VERSION "canboat-NMEA2000-curated"

NS_ :

BS_:

BU_: Vector__XXX
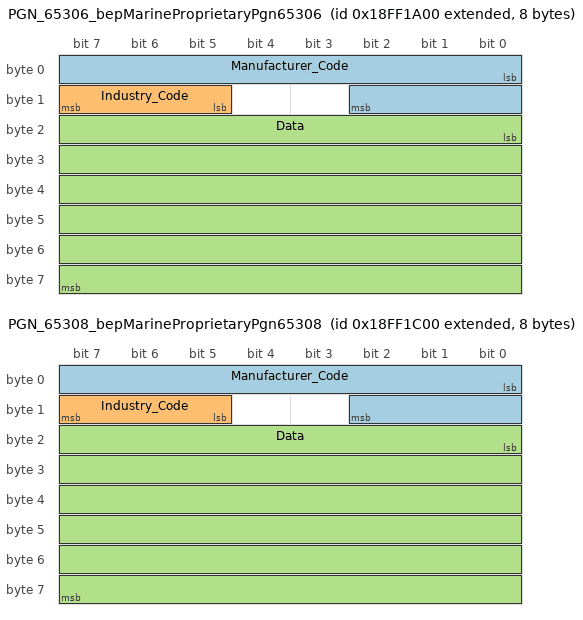
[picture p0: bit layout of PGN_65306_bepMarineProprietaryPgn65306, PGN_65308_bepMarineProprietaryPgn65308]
BO_ 2566855168 PGN_65306_bepMarineProprietaryPgn65306: 8 Vector__XXX
 SG_ Manufacturer_Code : 0|11@1+ (1.0,0) [0|2047] "" Vector__XXX
 SG_ Industry_Code : 13|3@1+ (1.0,0) [0|7] "" Vector__XXX
 SG_ Data : 16|48@1+ (1.0,0) [0|281474976710655] "" Vector__XXX

BO_ 2566855680 PGN_65308_bepMarineProprietaryPgn65308: 8 Vector__XXX
 SG_ Manufacturer_Code : 0|11@1+ (1.0,0) [0|2047] "" Vector__XXX
 SG_ Industry_Code : 13|3@1+ (1.0,0) [0|7] "" Vector__XXX
 SG_ Data : 16|48@1+ (1.0,0) [0|281474976710655] "" Vector__XXX

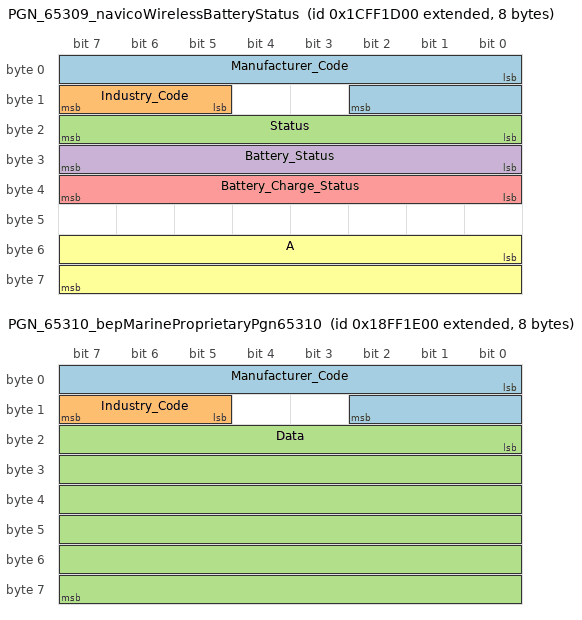
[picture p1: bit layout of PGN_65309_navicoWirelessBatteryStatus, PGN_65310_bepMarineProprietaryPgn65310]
BO_ 2633964800 PGN_65309_navicoWirelessBatteryStatus: 8 Vector__XXX
 SG_ Manufacturer_Code : 0|11@1+ (1.0,0) [0|2047] "" Vector__XXX
 SG_ Industry_Code : 13|3@1+ (1.0,0) [0|7] "" Vector__XXX
 SG_ Status : 16|8@1+ (1.0,0) [0|255] "" Vector__XXX
 SG_ Battery_Status : 24|8@1+ (1.0,0) [0|255] "%" Vector__XXX
 SG_ Battery_Charge_Status : 32|8@1+ (1.0,0) [0|255] "%" Vector__XXX
 SG_ A : 48|16@1- (1.0,0) [-32768|32767] "" Vector__XXX

BO_ 2566856192 PGN_65310_bepMarineProprietaryPgn65310: 8 Vector__XXX
 SG_ Manufacturer_Code : 0|11@1+ (1.0,0) [0|2047] "" Vector__XXX
 SG_ Industry_Code : 13|3@1+ (1.0,0) [0|7] "" Vector__XXX
 SG_ Data : 16|48@1+ (1.0,0) [0|281474976710655] "" Vector__XXX

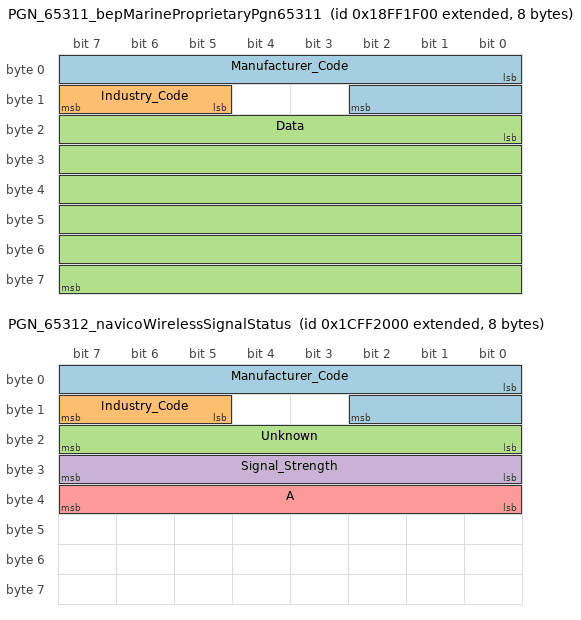
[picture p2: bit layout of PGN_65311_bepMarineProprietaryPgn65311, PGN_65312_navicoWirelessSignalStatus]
BO_ 2566856448 PGN_65311_bepMarineProprietaryPgn65311: 8 Vector__XXX
 SG_ Manufacturer_Code : 0|11@1+ (1.0,0) [0|2047] "" Vector__XXX
 SG_ Industry_Code : 13|3@1+ (1.0,0) [0|7] "" Vector__XXX
 SG_ Data : 16|48@1+ (1.0,0) [0|281474976710655] "" Vector__XXX

BO_ 2633965568 PGN_65312_navicoWirelessSignalStatus: 8 Vector__XXX
 SG_ Manufacturer_Code : 0|11@1+ (1.0,0) [0|2047] "" Vector__XXX
 SG_ Industry_Code : 13|3@1+ (1.0,0) [0|7] "" Vector__XXX
 SG_ Unknown : 16|8@1+ (1.0,0) [0|255] "" Vector__XXX
 SG_ Signal_Strength : 24|8@1+ (1.0,0) [0|255] "%" Vector__XXX
 SG_ A : 32|8@1- (1.0,0) [-128|127] "" Vector__XXX

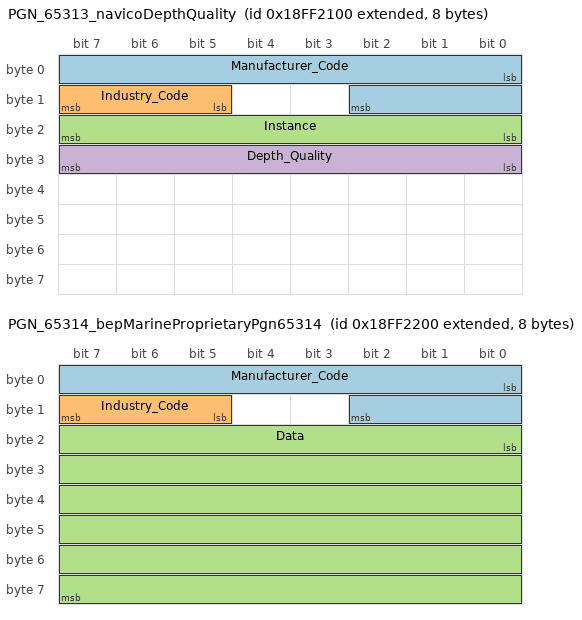
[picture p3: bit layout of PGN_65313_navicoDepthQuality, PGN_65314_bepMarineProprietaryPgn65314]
BO_ 2566856960 PGN_65313_navicoDepthQuality: 8 Vector__XXX
 SG_ Manufacturer_Code : 0|11@1+ (1.0,0) [0|2047] "" Vector__XXX
 SG_ Industry_Code : 13|3@1+ (1.0,0) [0|7] "" Vector__XXX
 SG_ Instance : 16|8@1+ (1.0,0) [0|255] "" Vector__XXX
 SG_ Depth_Quality : 24|8@1- (0.01,0) [-1.28|1.27] "" Vector__XXX

BO_ 2566857216 PGN_65314_bepMarineProprietaryPgn65314: 8 Vector__XXX
 SG_ Manufacturer_Code : 0|11@1+ (1.0,0) [0|2047] "" Vector__XXX
 SG_ Industry_Code : 13|3@1+ (1.0,0) [0|7] "" Vector__XXX
 SG_ Data : 16|48@1+ (1.0,0) [0|281474976710655] "" Vector__XXX

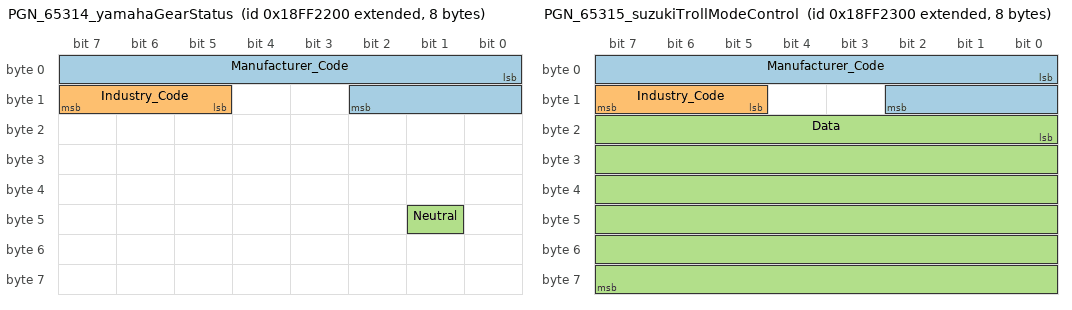
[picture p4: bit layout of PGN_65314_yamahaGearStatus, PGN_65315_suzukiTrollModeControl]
BO_ 2566857216 PGN_65314_yamahaGearStatus: 8 Vector__XXX
 SG_ Manufacturer_Code : 0|11@1+ (1.0,0) [0|2047] "" Vector__XXX
 SG_ Industry_Code : 13|3@1+ (1.0,0) [0|7] "" Vector__XXX
 SG_ Neutral : 41|1@1+ (1.0,0) [0|1] "" Vector__XXX

BO_ 2566857472 PGN_65315_suzukiTrollModeControl: 8 Vector__XXX
 SG_ Manufacturer_Code : 0|11@1+ (1.0,0) [0|2047] "" Vector__XXX
 SG_ Industry_Code : 13|3@1+ (1.0,0) [0|7] "" Vector__XXX
 SG_ Data : 16|48@1+ (1.0,0) [0|281474976710655] "" Vector__XXX

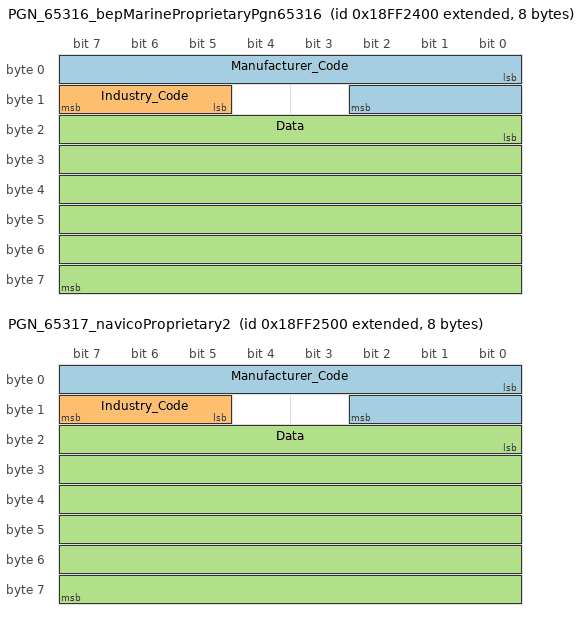
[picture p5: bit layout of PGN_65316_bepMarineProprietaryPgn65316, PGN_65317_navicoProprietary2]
BO_ 2566857728 PGN_65316_bepMarineProprietaryPgn65316: 8 Vector__XXX
 SG_ Manufacturer_Code : 0|11@1+ (1.0,0) [0|2047] "" Vector__XXX
 SG_ Industry_Code : 13|3@1+ (1.0,0) [0|7] "" Vector__XXX
 SG_ Data : 16|48@1+ (1.0,0) [0|281474976710655] "" Vector__XXX

BO_ 2566857984 PGN_65317_navicoProprietary2: 8 Vector__XXX
 SG_ Manufacturer_Code : 0|11@1+ (1.0,0) [0|2047] "" Vector__XXX
 SG_ Industry_Code : 13|3@1+ (1.0,0) [0|7] "" Vector__XXX
 SG_ Data : 16|48@1+ (1.0,0) [0|281474976710655] "" Vector__XXX

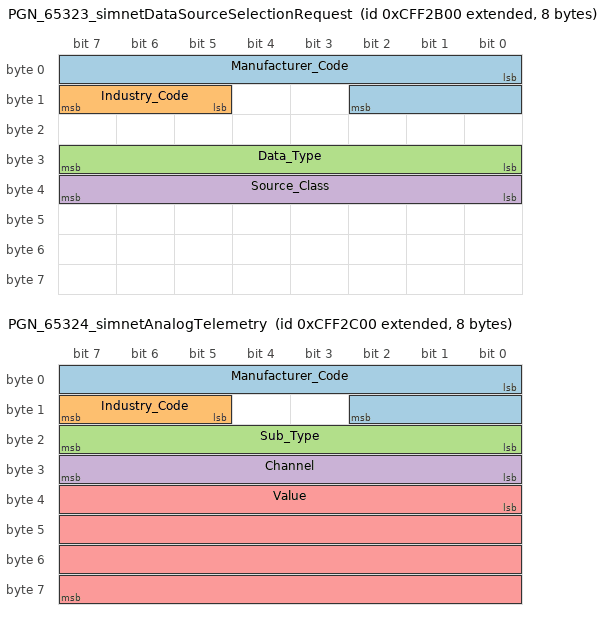
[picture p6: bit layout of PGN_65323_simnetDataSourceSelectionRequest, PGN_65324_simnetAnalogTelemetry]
BO_ 2365532928 PGN_65323_simnetDataSourceSelectionRequest: 8 Vector__XXX
 SG_ Manufacturer_Code : 0|11@1+ (1.0,0) [0|2047] "" Vector__XXX
 SG_ Industry_Code : 13|3@1+ (1.0,0) [0|7] "" Vector__XXX
 SG_ Data_Type : 24|8@1+ (1.0,0) [0|255] "" Vector__XXX
 SG_ Source_Class : 32|8@1+ (1.0,0) [0|255] "" Vector__XXX

BO_ 2365533184 PGN_65324_simnetAnalogTelemetry: 8 Vector__XXX
 SG_ Manufacturer_Code : 0|11@1+ (1.0,0) [0|2047] "" Vector__XXX
 SG_ Industry_Code : 13|3@1+ (1.0,0) [0|7] "" Vector__XXX
 SG_ Sub_Type : 16|8@1+ (1.0,0) [0|255] "" Vector__XXX
 SG_ Channel : 24|8@1+ (1.0,0) [0|255] "" Vector__XXX
 SG_ Value : 32|32@1+ (1.0,0) [0|4294967295] "" Vector__XXX

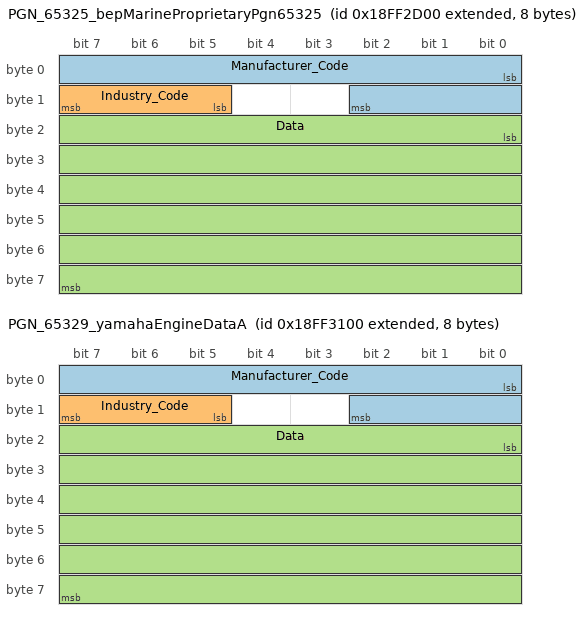
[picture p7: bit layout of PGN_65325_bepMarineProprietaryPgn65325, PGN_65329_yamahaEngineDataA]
BO_ 2566860032 PGN_65325_bepMarineProprietaryPgn65325: 8 Vector__XXX
 SG_ Manufacturer_Code : 0|11@1+ (1.0,0) [0|2047] "" Vector__XXX
 SG_ Industry_Code : 13|3@1+ (1.0,0) [0|7] "" Vector__XXX
 SG_ Data : 16|48@1+ (1.0,0) [0|281474976710655] "" Vector__XXX

BO_ 2566861056 PGN_65329_yamahaEngineDataA: 8 Vector__XXX
 SG_ Manufacturer_Code : 0|11@1+ (1.0,0) [0|2047] "" Vector__XXX
 SG_ Industry_Code : 13|3@1+ (1.0,0) [0|7] "" Vector__XXX
 SG_ Data : 16|48@1+ (1.0,0) [0|281474976710655] "" Vector__XXX

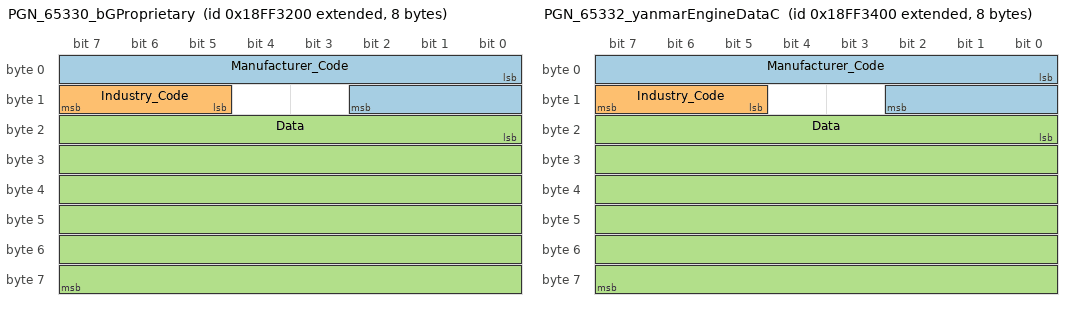
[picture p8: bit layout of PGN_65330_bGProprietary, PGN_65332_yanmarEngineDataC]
BO_ 2566861312 PGN_65330_bGProprietary: 8 Vector__XXX
 SG_ Manufacturer_Code : 0|11@1+ (1.0,0) [0|2047] "" Vector__XXX
 SG_ Industry_Code : 13|3@1+ (1.0,0) [0|7] "" Vector__XXX
 SG_ Data : 16|48@1+ (1.0,0) [0|281474976710655] "" Vector__XXX

BO_ 2566861824 PGN_65332_yanmarEngineDataC: 8 Vector__XXX
 SG_ Manufacturer_Code : 0|11@1+ (1.0,0) [0|2047] "" Vector__XXX
 SG_ Industry_Code : 13|3@1+ (1.0,0) [0|7] "" Vector__XXX
 SG_ Data : 16|48@1+ (1.0,0) [0|281474976710655] "" Vector__XXX

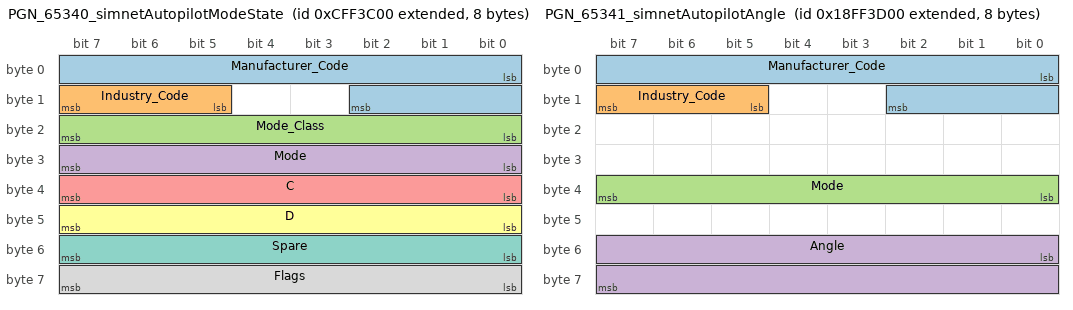
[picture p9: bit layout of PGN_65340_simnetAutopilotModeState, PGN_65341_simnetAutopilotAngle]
BO_ 2365537280 PGN_65340_simnetAutopilotModeState: 8 Vector__XXX
 SG_ Manufacturer_Code : 0|11@1+ (1.0,0) [0|2047] "" Vector__XXX
 SG_ Industry_Code : 13|3@1+ (1.0,0) [0|7] "" Vector__XXX
 SG_ Mode_Class : 16|8@1+ (1.0,0) [0|255] "" Vector__XXX
 SG_ Mode : 24|8@1+ (1.0,0) [0|255] "" Vector__XXX
 SG_ C : 32|8@1+ (1.0,0) [0|255] "" Vector__XXX
 SG_ D : 40|8@1+ (1.0,0) [0|255] "" Vector__XXX
 SG_ Spare : 48|8@1+ (1.0,0) [0|255] "" Vector__XXX
 SG_ Flags : 56|8@1+ (1.0,0) [0|255] "" Vector__XXX

BO_ 2566864128 PGN_65341_simnetAutopilotAngle: 8 Vector__XXX
 SG_ Manufacturer_Code : 0|11@1+ (1.0,0) [0|2047] "" Vector__XXX
 SG_ Industry_Code : 13|3@1+ (1.0,0) [0|7] "" Vector__XXX
 SG_ Mode : 32|8@1+ (1.0,0) [0|255] "" Vector__XXX
 SG_ Angle : 48|16@1+ (0.0001,0) [0.0|6.5535000000000005] "" Vector__XXX

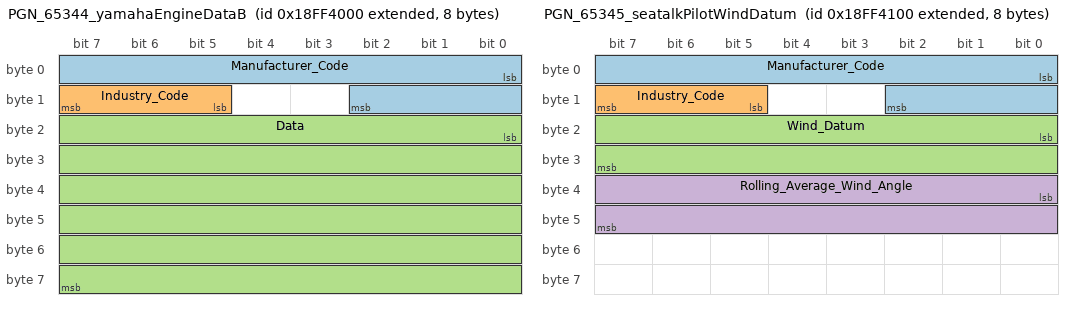
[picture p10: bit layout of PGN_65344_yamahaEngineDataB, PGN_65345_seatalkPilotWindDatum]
BO_ 2566864896 PGN_65344_yamahaEngineDataB: 8 Vector__XXX
 SG_ Manufacturer_Code : 0|11@1+ (1.0,0) [0|2047] "" Vector__XXX
 SG_ Industry_Code : 13|3@1+ (1.0,0) [0|7] "" Vector__XXX
 SG_ Data : 16|48@1+ (1.0,0) [0|281474976710655] "" Vector__XXX

BO_ 2566865152 PGN_65345_seatalkPilotWindDatum: 8 Vector__XXX
 SG_ Manufacturer_Code : 0|11@1+ (1.0,0) [0|2047] "" Vector__XXX
 SG_ Industry_Code : 13|3@1+ (1.0,0) [0|7] "" Vector__XXX
 SG_ Wind_Datum : 16|16@1+ (0.0001,0) [0.0|6.5535000000000005] "" Vector__XXX
 SG_ Rolling_Average_Wind_Angle : 32|16@1+ (0.0001,0) [0.0|6.5535000000000005] "" Vector__XXX

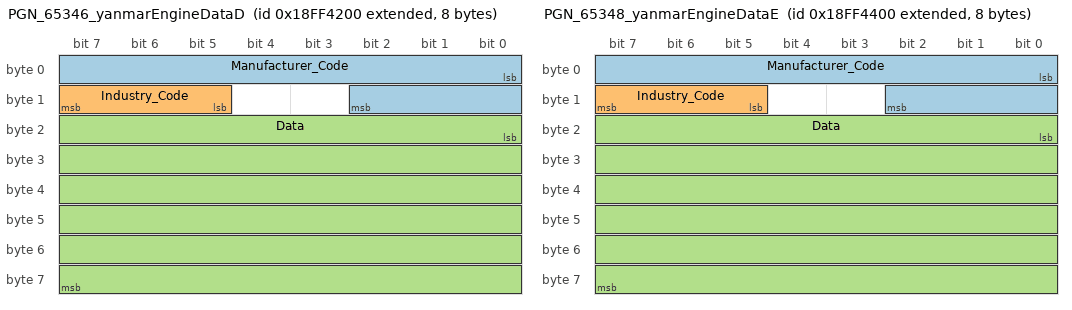
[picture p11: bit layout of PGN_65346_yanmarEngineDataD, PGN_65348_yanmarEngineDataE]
BO_ 2566865408 PGN_65346_yanmarEngineDataD: 8 Vector__XXX
 SG_ Manufacturer_Code : 0|11@1+ (1.0,0) [0|2047] "" Vector__XXX
 SG_ Industry_Code : 13|3@1+ (1.0,0) [0|7] "" Vector__XXX
 SG_ Data : 16|48@1+ (1.0,0) [0|281474976710655] "" Vector__XXX

BO_ 2566865920 PGN_65348_yanmarEngineDataE: 8 Vector__XXX
 SG_ Manufacturer_Code : 0|11@1+ (1.0,0) [0|2047] "" Vector__XXX
 SG_ Industry_Code : 13|3@1+ (1.0,0) [0|7] "" Vector__XXX
 SG_ Data : 16|48@1+ (1.0,0) [0|281474976710655] "" Vector__XXX

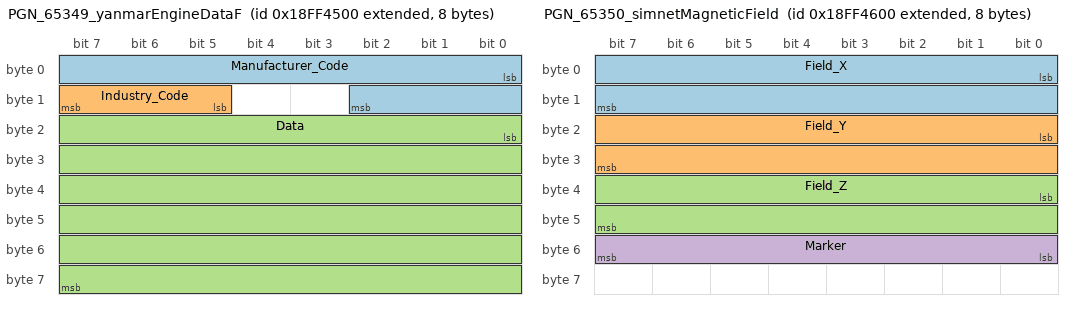
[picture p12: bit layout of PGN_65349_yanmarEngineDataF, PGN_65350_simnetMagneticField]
BO_ 2566866176 PGN_65349_yanmarEngineDataF: 8 Vector__XXX
 SG_ Manufacturer_Code : 0|11@1+ (1.0,0) [0|2047] "" Vector__XXX
 SG_ Industry_Code : 13|3@1+ (1.0,0) [0|7] "" Vector__XXX
 SG_ Data : 16|48@1+ (1.0,0) [0|281474976710655] "" Vector__XXX

BO_ 2566866432 PGN_65350_simnetMagneticField: 8 Vector__XXX
 SG_ Field_X : 0|16@1- (0.0001,0) [-3.2768|3.2767] "" Vector__XXX
 SG_ Field_Y : 16|16@1- (0.0001,0) [-3.2768|3.2767] "" Vector__XXX
 SG_ Field_Z : 32|16@1- (0.0001,0) [-3.2768|3.2767] "" Vector__XXX
 SG_ Marker : 48|8@1+ (1.0,0) [0|255] "" Vector__XXX

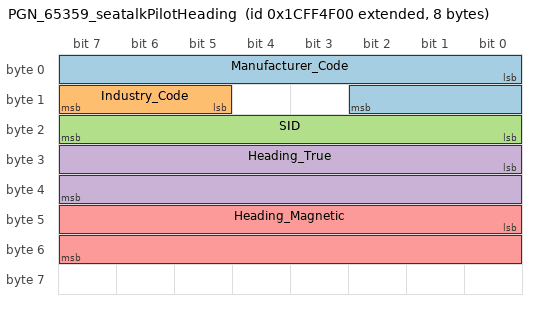
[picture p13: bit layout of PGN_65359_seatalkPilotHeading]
BO_ 2633977600 PGN_65359_seatalkPilotHeading: 8 Vector__XXX
 SG_ Manufacturer_Code : 0|11@1+ (1.0,0) [0|2047] "" Vector__XXX
 SG_ Industry_Code : 13|3@1+ (1.0,0) [0|7] "" Vector__XXX
 SG_ SID : 16|8@1+ (1.0,0) [0|255] "" Vector__XXX
 SG_ Heading_True : 24|16@1+ (0.0001,0) [0.0|6.5535000000000005] "" Vector__XXX
 SG_ Heading_Magnetic : 40|16@1+ (0.0001,0) [0.0|6.5535000000000005] "" Vector__XXX

CM_ BO_ 2566855168 "NMEA2000: PGN 65306 - BEP Marine: Proprietary PGN 65306 (type: Single)";
CM_ BO_ 2566855680 "NMEA2000: PGN 65308 - BEP Marine: Proprietary PGN 65308 (type: Single)";
CM_ BO_ 2633964800 "NMEA2000: PGN 65309 - Navico: Wireless Battery Status (type: Single)";
CM_ BO_ 2566856192 "NMEA2000: PGN 65310 - BEP Marine: Proprietary PGN 65310 (type: Single)";
CM_ BO_ 2566856448 "NMEA2000: PGN 65311 - BEP Marine: Proprietary PGN 65311 (type: Single)";
CM_ BO_ 2633965568 "NMEA2000: PGN 65312 - Navico: Wireless Signal Status (type: Single)";
CM_ BO_ 2566856960 "NMEA2000: PGN 65313 - Navico: Depth Quality (type: Single)";
CM_ BO_ 2566857216 "NMEA2000: PGN 65314 - BEP Marine: Proprietary PGN 65314 (type: Single)";
CM_ BO_ 2566857216 "NMEA2000: PGN 65314 - Yamaha: Gear Status (type: Single)";
CM_ BO_ 2566857472 "NMEA2000: PGN 65315 - Suzuki: Troll Mode Control (type: Single)";
CM_ BO_ 2566857728 "NMEA2000: PGN 65316 - BEP Marine: Proprietary PGN 65316 (type: Single)";
CM_ BO_ 2566857984 "NMEA2000: PGN 65317 - Navico: Proprietary 2 (type: Single)";
CM_ BO_ 2365532928 "NMEA2000: PGN 65323 - Simnet: Data Source Selection Request (type: Single)";
CM_ BO_ 2365533184 "NMEA2000: PGN 65324 - Simnet: Analog Telemetry (type: Single)";
CM_ BO_ 2566860032 "NMEA2000: PGN 65325 - BEP Marine: Proprietary PGN 65325 (type: Single)";
CM_ BO_ 2566861056 "NMEA2000: PGN 65329 - Yamaha: Engine Data A (type: Single)";
CM_ BO_ 2566861312 "NMEA2000: PGN 65330 - B&G: Proprietary (type: Single)";
CM_ BO_ 2566861824 "NMEA2000: PGN 65332 - Yanmar: Engine Data C (type: Single)";
CM_ BO_ 2365537280 "NMEA2000: PGN 65340 - Simnet: Autopilot Mode State (type: Single)";
CM_ BO_ 2566864128 "NMEA2000: PGN 65341 - Simnet: Autopilot Angle (type: Single)";
CM_ BO_ 2566864896 "NMEA2000: PGN 65344 - Yamaha: Engine Data B (type: Single)";
CM_ BO_ 2566865152 "NMEA2000: PGN 65345 - Seatalk: Pilot Wind Datum (type: Single)";
CM_ BO_ 2566865408 "NMEA2000: PGN 65346 - Yanmar: Engine Data D (type: Single)";
CM_ BO_ 2566865920 "NMEA2000: PGN 65348 - Yanmar: Engine Data E (type: Single)";
CM_ BO_ 2566866176 "NMEA2000: PGN 65349 - Yanmar: Engine Data F (type: Single)";
CM_ BO_ 2566866432 "NMEA2000: PGN 65350 - Simnet: Magnetic Field (type: Single)";
CM_ BO_ 2633977600 "NMEA2000: PGN 65359 - Seatalk: Pilot Heading (type: Single)";
CM_ SG_ 2566855168 Manufacturer_Code "BEP Marine; canboat type: LOOKUP";
CM_ SG_ 2566855168 Industry_Code "Marine Industry; canboat type: LOOKUP";
CM_ SG_ 2566855168 Data "canboat type: BINARY";
CM_ SG_ 2566855680 Manufacturer_Code "BEP Marine; canboat type: LOOKUP";
CM_ SG_ 2566855680 Industry_Code "Marine Industry; canboat type: LOOKUP";
CM_ SG_ 2566855680 Data "canboat type: BINARY";
CM_ SG_ 2633964800 Manufacturer_Code "Navico; canboat type: LOOKUP";
CM_ SG_ 2633964800 Industry_Code "Marine Industry; canboat type: LOOKUP";
CM_ SG_ 2633964800 Status "canboat type: UINT8";
CM_ SG_ 2633964800 Battery_Status "canboat type: PERCENTAGE_UINT8";
CM_ SG_ 2633964800 Battery_Charge_Status "canboat type: PERCENTAGE_UINT8";
CM_ SG_ 2633964800 A "canboat type: INT16";
CM_ SG_ 2566856192 Manufacturer_Code "BEP Marine; canboat type: LOOKUP";
CM_ SG_ 2566856192 Industry_Code "Marine Industry; canboat type: LOOKUP";
CM_ SG_ 2566856192 Data "canboat type: BINARY";
CM_ SG_ 2566856448 Manufacturer_Code "BEP Marine; canboat type: LOOKUP";
CM_ SG_ 2566856448 Industry_Code "Marine Industry; canboat type: LOOKUP";
CM_ SG_ 2566856448 Data "canboat type: BINARY";
CM_ SG_ 2633965568 Manufacturer_Code "Navico; canboat type: LOOKUP";
CM_ SG_ 2633965568 Industry_Code "Marine Industry; canboat type: LOOKUP";
CM_ SG_ 2633965568 Unknown "canboat type: UINT8";
CM_ SG_ 2633965568 Signal_Strength "canboat type: PERCENTAGE_UINT8";
CM_ SG_ 2633965568 A "canboat type: INT8";
CM_ SG_ 2566856960 Manufacturer_Code "Navico; canboat type: LOOKUP";
CM_ SG_ 2566856960 Industry_Code "Marine Industry; canboat type: LOOKUP";
CM_ SG_ 2566856960 Instance "canboat type: UINT8";
CM_ SG_ 2566856960 Depth_Quality "Depth signal quality ratio (0 = no bottom lock .. ~1.0 = good); canboat type: INT8";
CM_ SG_ 2566857216 Manufacturer_Code "BEP Marine; canboat type: LOOKUP";
CM_ SG_ 2566857216 Industry_Code "Marine Industry; canboat type: LOOKUP";
CM_ SG_ 2566857216 Data "canboat type: BINARY";
CM_ SG_ 2566857216 Manufacturer_Code "Mystic Valley Communications; canboat type: LOOKUP";
CM_ SG_ 2566857216 Industry_Code "Marine Industry; canboat type: LOOKUP";
CM_ SG_ 2566857216 Neutral "canboat type: LOOKUP";
CM_ SG_ 2566857472 Manufacturer_Code "Suzuki Motor Corporation; canboat type: LOOKUP";
CM_ SG_ 2566857472 Industry_Code "Marine Industry; canboat type: LOOKUP";
CM_ SG_ 2566857472 Data "canboat type: BINARY";
CM_ SG_ 2566857728 Manufacturer_Code "BEP Marine; canboat type: LOOKUP";
CM_ SG_ 2566857728 Industry_Code "Marine Industry; canboat type: LOOKUP";
CM_ SG_ 2566857728 Data "canboat type: BINARY";
CM_ SG_ 2566857984 Manufacturer_Code "Navico; canboat type: LOOKUP";
CM_ SG_ 2566857984 Industry_Code "Marine Industry; canboat type: LOOKUP";
CM_ SG_ 2566857984 Data "canboat type: BINARY";
CM_ SG_ 2365532928 Manufacturer_Code "Simrad; canboat type: LOOKUP";
CM_ SG_ 2365532928 Industry_Code "Marine Industry; canboat type: LOOKUP";
CM_ SG_ 2365532928 Data_Type "canboat type: LOOKUP";
CM_ SG_ 2365532928 Source_Class "Class of source for this Data Type, constant per Data Type: observed as 1 for direct sensor/navigation sources and 100 for autopilot-provided sources; canboat type: UINT8";
CM_ SG_ 2365533184 Manufacturer_Code "Simrad; canboat type: LOOKUP";
CM_ SG_ 2365533184 Industry_Code "Marine Industry; canboat type: LOOKUP";
CM_ SG_ 2365533184 Sub_Type "0x40 = telemetry; canboat type: UINT8";
CM_ SG_ 2365533184 Channel "Selects which analog quantity is reported (e.g. drive/heatsink temperature, drive supply voltage, drive current, rudder-feedback angle); canboat type: UINT8";
CM_ SG_ 2365533184 Value "Raw channel reading; 0x7FFF or 0xFFFF means not available; canboat type: UINT32";
CM_ SG_ 2566860032 Manufacturer_Code "BEP Marine; canboat type: LOOKUP";
CM_ SG_ 2566860032 Industry_Code "Marine Industry; canboat type: LOOKUP";
CM_ SG_ 2566860032 Data "canboat type: BINARY";
CM_ SG_ 2566861056 Manufacturer_Code "Mystic Valley Communications; canboat type: LOOKUP";
CM_ SG_ 2566861056 Industry_Code "Marine Industry; canboat type: LOOKUP";
CM_ SG_ 2566861056 Data "canboat type: BINARY";
CM_ SG_ 2566861312 Manufacturer_Code "B & G; canboat type: LOOKUP";
CM_ SG_ 2566861312 Industry_Code "Marine Industry; canboat type: LOOKUP";
CM_ SG_ 2566861312 Data "canboat type: BINARY";
CM_ SG_ 2566861824 Manufacturer_Code "Yanmar Marine; canboat type: LOOKUP";
CM_ SG_ 2566861824 Industry_Code "Marine Industry; canboat type: LOOKUP";
CM_ SG_ 2566861824 Data "canboat type: BINARY";
CM_ SG_ 2365537280 Manufacturer_Code "Simrad; canboat type: LOOKUP";
CM_ SG_ 2365537280 Industry_Code "Marine Industry; canboat type: LOOKUP";
CM_ SG_ 2365537280 Mode_Class "canboat type: LOOKUP";
CM_ SG_ 2365537280 Mode "canboat type: LOOKUP";
CM_ SG_ 2365537280 C "canboat type: UINT8";
CM_ SG_ 2365537280 D "canboat type: UINT8";
CM_ SG_ 2365537280 Spare "canboat type: SPARE";
CM_ SG_ 2365537280 Flags "canboat type: UINT8";
CM_ SG_ 2566864128 Manufacturer_Code "Simrad; canboat type: LOOKUP";
CM_ SG_ 2566864128 Industry_Code "Marine Industry; canboat type: LOOKUP";
CM_ SG_ 2566864128 Mode "canboat type: LOOKUP";
CM_ SG_ 2566864128 Angle "canboat type: ANGLE_UFIX16";
CM_ SG_ 2566864896 Manufacturer_Code "Mystic Valley Communications; canboat type: LOOKUP";
CM_ SG_ 2566864896 Industry_Code "Marine Industry; canboat type: LOOKUP";
CM_ SG_ 2566864896 Data "canboat type: BINARY";
CM_ SG_ 2566865152 Manufacturer_Code "Raymarine; canboat type: LOOKUP";
CM_ SG_ 2566865152 Industry_Code "Marine Industry; canboat type: LOOKUP";
CM_ SG_ 2566865152 Wind_Datum "canboat type: ANGLE_UFIX16";
CM_ SG_ 2566865152 Rolling_Average_Wind_Angle "canboat type: ANGLE_UFIX16";
CM_ SG_ 2566865408 Manufacturer_Code "Yanmar Marine; canboat type: LOOKUP";
CM_ SG_ 2566865408 Industry_Code "Marine Industry; canboat type: LOOKUP";
CM_ SG_ 2566865408 Data "canboat type: BINARY";
CM_ SG_ 2566865920 Manufacturer_Code "Yanmar Marine; canboat type: LOOKUP";
CM_ SG_ 2566865920 Industry_Code "Marine Industry; canboat type: LOOKUP";
CM_ SG_ 2566865920 Data "canboat type: BINARY";
CM_ SG_ 2566866176 Manufacturer_Code "Yanmar Marine; canboat type: LOOKUP";
CM_ SG_ 2566866176 Industry_Code "Marine Industry; canboat type: LOOKUP";
CM_ SG_ 2566866176 Data "canboat type: BINARY";
CM_ SG_ 2566866432 Field_X "canboat type: INT16";
CM_ SG_ 2566866432 Field_Y "canboat type: INT16";
CM_ SG_ 2566866432 Field_Z "canboat type: INT16";
CM_ SG_ 2566866432 Marker "canboat type: UINT8";
CM_ SG_ 2633977600 Manufacturer_Code "Raymarine; canboat type: LOOKUP";
CM_ SG_ 2633977600 Industry_Code "Marine Industry; canboat type: LOOKUP";
CM_ SG_ 2633977600 SID "canboat type: UINT8";
CM_ SG_ 2633977600 Heading_True "canboat type: ANGLE_UFIX16";
CM_ SG_ 2633977600 Heading_Magnetic "canboat type: ANGLE_UFIX16";
VAL_ 2566855168 Manufacturer_Code 69 "ARKS Enterprises" 78 "FW Murphy/Enovation Controls" 80 "Twin Disc" 85 "Kohler Power Systems" 88 "Hemisphere GPS" 135 "Airmar" 137 "Maretron" 140 "Lowrance" 144 "Mercury Marine" 147 "Nautibus Electronic" 148 "Blue Water Data" 154 "Westerbeke" 157 "ISSPRO" 161 "Offshore Systems (UK)" 163 "Evinrude/BRP" 165 "CPAC Systems" 168 "Xantrex Technology" 169 "Marlin Technologies" 172 "Yanmar Marine" 174 "Volvo Penta" 176 "Carling Technologies Inc. (Moritz Aerospace)" 185 "Beede Instruments" 192 "Floscan Instrument" 193 "Nobeltec" 198 "Mystic Valley Communications" 199 "Actia" 201 "Disenos Y Technologia" 211 "Digital Switching Systems" 215 "Xintex/Atena" 224 "EMMI NETWORK" 228 "ZF" 229 "Garmin" 233 "Yacht Monitoring Solutions" 235 "Sailormade Marine Telemetry/Tetra Technology" 243 "Eride" 257 "Honda Motor" 272 "Groco" 273 "Actisense" 274 "Amphenol LTW Technology" 275 "Navico" 283 "Hamilton Jet" 285 "Sea Recovery" 286 "Coelmo SRL Italy" 295 "BEP Marine" 304 "Empir Bus" 305 "NovAtel" 306 "Sleipner Motor" 307 "MBW Technologies" 315 "ICOM" 328 "Qwerty" 329 "Dief" 341 "Boening Automationstechnologie" 345 "Korean Maritime University" 351 "Thrane and Thrane" 355 "Mastervolt" 356 "Fischer Panda Generators" 358 "Victron Energy" 370 "Rolls Royce Marine" 373 "Electronic Design" 374 "Northern Lights" 378 "Glendinning" 381 "B & G" 384 "Rose Point Navigation Systems" 385 "Johnson Outdoors Marine Electronics Inc Geonav" 394 "Capi 2" 396 "Beyond Measure" 400 "Livorsi Marine" 404 "ComNav" 409 "Chetco" 419 "Fusion Electronics" 421 "Standard Horizon" 422 "True Heading" 426 "Egersund Marine Electronics" 427 "em-trak Marine Electronics" 431 "Tohatsu Co, JP" 437 "Digital Yacht" 438 "Comar Systems Limited" 440 "Cummins" 443 "VDO (aka Continental-Corporation)" 451 "Parker Hannifin aka Village Marine Tech" 459 "Alltek Marine Electronics" 460 "SAN GIORGIO S.E.I.N" 466 "Veethree Electronics & Marine" 470 "SI-TEX Marine Electronics" 471 "Sea Cross Marine" 475 "GME aka Standard Communications" 476 "Humminbird Marine Electronics" 478 "Ocean Sat" 481 "Chetco Digital Instruments" 493 "Watcheye" 499 "Lcj Capteurs" 502 "Attwood Marine" 503 "Naviop S.R.L." 504 "Vesper Marine" 510 "Marinesoft" 513 "Simarine" 517 "NoLand Engineering" 518 "Transas USA" 529 "National Instruments Korea" 530 "National Marine Electronics Association" 532 "Onwa Marine" 540 "Webasto" 571 "Marinecraft (South Korea)" 573 "McMurdo Group aka Orolia" 578 "Advansea" 579 "KVH" 580 "San Jose Technology" 583 "Yacht Control" 586 "Suzuki Motor" 591 "US Coast Guard" 595 "Ship Module aka Customware" 600 "Aquatic AV" 605 "Aventics" 606 "Intellian" 612 "SamwonIT" 614 "Arlt Tecnologies" 637 "Bavaria Yachts" 641 "Diverse Yacht Services" 644 "Wema U.S.A dba KUS" 658 "Shenzhen Jiuzhou Himunication" 688 "Rockford" 699 "Harman International" 704 "JL Audio" 708 "Lars Thrane" 715 "Autonnic" 717 "Yacht Devices" 734 "REAP Systems" 735 "AEM Performance Electronics" 739 "LxNav" 741 "Littelfuse, Inc (formerly Carling Technologies)" 743 "DaeMyung" 744 "Woosung" 748 "ISOTTA IFRA srl" 773 "Clarion US" 776 "HMI Systems" 777 "Ocean Signal" 778 "Seakeeper" 781 "Poly Planar" 785 "Fischer Panda DE" 795 "Broyda Industries" 796 "Canadian Automotive" 797 "Tides Marine" 798 "Lumishore" 799 "Still Water Designs and Audio" 802 "BJ Technologies (Beneteau)" 803 "Gill Sensors" 811 "Blue Water Desalination" 815 "FLIR" 824 "Undheim Systems" 826 "Lewmar" 838 "TeamSurv" 844 "Fell Marine" 847 "Oceanvolt" 862 "Prospec" 868 "Data Panel" 890 "L3 Technologies" 894 "Rhodan Marine Systems" 896 "Nexfour Solutions" 905 "ASA Electronics" 909 "Marines Co (South Korea)" 911 "Nautic-on" 917 "Sentinel" 929 "JL Marine Systems" 930 "Ecotronix" 944 "Zontisa Marine" 951 "EXOR International" 962 "Timbolier Industries" 963 "TJC Micro" 968 "Cox Powertrain" 969 "Blue Seas" 981 "Kobelt Manufacturing" 992 "Blue Ocean IOT" 997 "Xenta Systems" 999 "Signal K" 1004 "Ultraflex" 1008 "Lintest SmartBoat" 1011 "Soundmax" 1020 "Team Italia Marine (Onyx Marine Automation s.r.l)" 1021 "Entratech" 1022 "ITC" 1029 "The Marine Guardian" 1047 "Sonic" 1051 "ProNav" 1053 "Vetus Maxwell INC." 1056 "Lithium Pros" 1059 "Boatrax" 1062 "Marol Co ltd" 1065 "CALYPSO Instruments" 1066 "Spot Zero Water" 1069 "Lithionics Battery" 1070 "Quick-teck Electronics" 1075 "Uniden America" 1083 "Nauticoncept" 1084 "Shadow-Caster LED lighting" 1085 "Wet Sounds" 1088 "E-T-A Circuit Breakers" 1092 "Scheiber" 1100 "Smart Yachts International Limited" 1109 "Dockmate" 1114 "Bobs Machine" 1118 "L3Harris ASV" 1119 "Balmar" 1120 "Elettromedia" 1127 "Electromaax" 1140 "Across Oceans Systems" 1145 "Kiwi Yachting" 1150 "BSB Artificial Intelligence" 1151 "Orca Technologies" 1154 "TBS Electronics" 1158 "Technoton Electroics" 1160 "MG Energy Systems" 1169 "Sea Machine Robotics" 1171 "Vista Manufacturing" 1183 "Zipwake" 1186 "Sailmon" 1192 "Airmoniq Pro Kft" 1194 "Sierra Marine" 1200 "Xinuo Information Technology (Xiamen)" 1218 "Septentrio" 1233 "NKE Marine Electronics" 1238 "SuperTrack Aps" 1239 "Honda Electronics" 1245 "Raritan Engineering" 1249 "Integrated Power Solutions AG" 1260 "Interactive Technologies" 1283 "LTG-Tech" 1299 "Energy Solutions (UK)" 1300 "WATT Fuel Cell" 1302 "Pro Mainer" 1305 "Dragonfly Energy" 1306 "Koden Electronics" 1311 "Humphree" 1316 "Hinkley Yachts" 1317 "Global Marine Management GmbH (GMM)" 1320 "Triskel Marine" 1330 "Warwick Control Technologies" 1331 "Dolphin Charger" 1337 "Barnacle Systems" 1348 "Radian IoT" 1353 "Ocean LED Marine" 1359 "BluNav" 1361 "OVA (Nantong Saiyang Electronics Co., Ltd)" 1368 "RAD Propulsion" 1369 "Electric Yacht" 1372 "Elco Motor Yachts" 1384 "Tecnoseal Foundry S.r.l" 1385 "Pro Charging Systems" 1389 "EVEX" 1398 "Gobius Sensor Technology" 1403 "Arco Marine" 1408 "Lenco Marine" 1413 "Naocontrol" 1417 "Revatek" 1438 "Aeolionics" 1439 "PredictWind" 1440 "Egis Mobile Electric" 1445 "Starboard Yacht Group" 1446 "Roswell Marine" 1451 "ePropulsion (Guangdong ePropulsion Technology Ltd.)" 1452 "Micro-Air" 1453 "Vital Battery" 1458 "Ride Controller" 1460 "Tocaro Blue" 1461 "Vanquish Yachts" 1471 "FT Technologies" 1478 "Alps Alpine" 1481 "E-Force Marine" 1482 "CMC Marine" 1483 "Nanjing Sandemarine Information Technology" 1850 "Teleflex Marine (SeaStar Solutions)" 1851 "Raymarine" 1852 "Navionics" 1853 "Japan Radio" 1854 "Northstar Technologies" 1855 "Furuno" 1856 "Trimble" 1857 "Simrad" 1858 "Litton" 1859 "Kvasar" 1860 "MMP" 1861 "Vector Cantech" 1862 "Yamaha Marine" 1863 "Faria Instruments" ;
VAL_ 2566855168 Industry_Code 0 "Global" 1 "Highway" 2 "Agriculture" 3 "Construction" 4 "Marine Industry" 5 "Industrial" ;
VAL_ 2566855680 Manufacturer_Code 69 "ARKS Enterprises" 78 "FW Murphy/Enovation Controls" 80 "Twin Disc" 85 "Kohler Power Systems" 88 "Hemisphere GPS" 135 "Airmar" 137 "Maretron" 140 "Lowrance" 144 "Mercury Marine" 147 "Nautibus Electronic" 148 "Blue Water Data" 154 "Westerbeke" 157 "ISSPRO" 161 "Offshore Systems (UK)" 163 "Evinrude/BRP" 165 "CPAC Systems" 168 "Xantrex Technology" 169 "Marlin Technologies" 172 "Yanmar Marine" 174 "Volvo Penta" 176 "Carling Technologies Inc. (Moritz Aerospace)" 185 "Beede Instruments" 192 "Floscan Instrument" 193 "Nobeltec" 198 "Mystic Valley Communications" 199 "Actia" 201 "Disenos Y Technologia" 211 "Digital Switching Systems" 215 "Xintex/Atena" 224 "EMMI NETWORK" 228 "ZF" 229 "Garmin" 233 "Yacht Monitoring Solutions" 235 "Sailormade Marine Telemetry/Tetra Technology" 243 "Eride" 257 "Honda Motor" 272 "Groco" 273 "Actisense" 274 "Amphenol LTW Technology" 275 "Navico" 283 "Hamilton Jet" 285 "Sea Recovery" 286 "Coelmo SRL Italy" 295 "BEP Marine" 304 "Empir Bus" 305 "NovAtel" 306 "Sleipner Motor" 307 "MBW Technologies" 315 "ICOM" 328 "Qwerty" 329 "Dief" 341 "Boening Automationstechnologie" 345 "Korean Maritime University" 351 "Thrane and Thrane" 355 "Mastervolt" 356 "Fischer Panda Generators" 358 "Victron Energy" 370 "Rolls Royce Marine" 373 "Electronic Design" 374 "Northern Lights" 378 "Glendinning" 381 "B & G" 384 "Rose Point Navigation Systems" 385 "Johnson Outdoors Marine Electronics Inc Geonav" 394 "Capi 2" 396 "Beyond Measure" 400 "Livorsi Marine" 404 "ComNav" 409 "Chetco" 419 "Fusion Electronics" 421 "Standard Horizon" 422 "True Heading" 426 "Egersund Marine Electronics" 427 "em-trak Marine Electronics" 431 "Tohatsu Co, JP" 437 "Digital Yacht" 438 "Comar Systems Limited" 440 "Cummins" 443 "VDO (aka Continental-Corporation)" 451 "Parker Hannifin aka Village Marine Tech" 459 "Alltek Marine Electronics" 460 "SAN GIORGIO S.E.I.N" 466 "Veethree Electronics & Marine" 470 "SI-TEX Marine Electronics" 471 "Sea Cross Marine" 475 "GME aka Standard Communications" 476 "Humminbird Marine Electronics" 478 "Ocean Sat" 481 "Chetco Digital Instruments" 493 "Watcheye" 499 "Lcj Capteurs" 502 "Attwood Marine" 503 "Naviop S.R.L." 504 "Vesper Marine" 510 "Marinesoft" 513 "Simarine" 517 "NoLand Engineering" 518 "Transas USA" 529 "National Instruments Korea" 530 "National Marine Electronics Association" 532 "Onwa Marine" 540 "Webasto" 571 "Marinecraft (South Korea)" 573 "McMurdo Group aka Orolia" 578 "Advansea" 579 "KVH" 580 "San Jose Technology" 583 "Yacht Control" 586 "Suzuki Motor" 591 "US Coast Guard" 595 "Ship Module aka Customware" 600 "Aquatic AV" 605 "Aventics" 606 "Intellian" 612 "SamwonIT" 614 "Arlt Tecnologies" 637 "Bavaria Yachts" 641 "Diverse Yacht Services" 644 "Wema U.S.A dba KUS" 658 "Shenzhen Jiuzhou Himunication" 688 "Rockford" 699 "Harman International" 704 "JL Audio" 708 "Lars Thrane" 715 "Autonnic" 717 "Yacht Devices" 734 "REAP Systems" 735 "AEM Performance Electronics" 739 "LxNav" 741 "Littelfuse, Inc (formerly Carling Technologies)" 743 "DaeMyung" 744 "Woosung" 748 "ISOTTA IFRA srl" 773 "Clarion US" 776 "HMI Systems" 777 "Ocean Signal" 778 "Seakeeper" 781 "Poly Planar" 785 "Fischer Panda DE" 795 "Broyda Industries" 796 "Canadian Automotive" 797 "Tides Marine" 798 "Lumishore" 799 "Still Water Designs and Audio" 802 "BJ Technologies (Beneteau)" 803 "Gill Sensors" 811 "Blue Water Desalination" 815 "FLIR" 824 "Undheim Systems" 826 "Lewmar" 838 "TeamSurv" 844 "Fell Marine" 847 "Oceanvolt" 862 "Prospec" 868 "Data Panel" 890 "L3 Technologies" 894 "Rhodan Marine Systems" 896 "Nexfour Solutions" 905 "ASA Electronics" 909 "Marines Co (South Korea)" 911 "Nautic-on" 917 "Sentinel" 929 "JL Marine Systems" 930 "Ecotronix" 944 "Zontisa Marine" 951 "EXOR International" 962 "Timbolier Industries" 963 "TJC Micro" 968 "Cox Powertrain" 969 "Blue Seas" 981 "Kobelt Manufacturing" 992 "Blue Ocean IOT" 997 "Xenta Systems" 999 "Signal K" 1004 "Ultraflex" 1008 "Lintest SmartBoat" 1011 "Soundmax" 1020 "Team Italia Marine (Onyx Marine Automation s.r.l)" 1021 "Entratech" 1022 "ITC" 1029 "The Marine Guardian" 1047 "Sonic" 1051 "ProNav" 1053 "Vetus Maxwell INC." 1056 "Lithium Pros" 1059 "Boatrax" 1062 "Marol Co ltd" 1065 "CALYPSO Instruments" 1066 "Spot Zero Water" 1069 "Lithionics Battery" 1070 "Quick-teck Electronics" 1075 "Uniden America" 1083 "Nauticoncept" 1084 "Shadow-Caster LED lighting" 1085 "Wet Sounds" 1088 "E-T-A Circuit Breakers" 1092 "Scheiber" 1100 "Smart Yachts International Limited" 1109 "Dockmate" 1114 "Bobs Machine" 1118 "L3Harris ASV" 1119 "Balmar" 1120 "Elettromedia" 1127 "Electromaax" 1140 "Across Oceans Systems" 1145 "Kiwi Yachting" 1150 "BSB Artificial Intelligence" 1151 "Orca Technologies" 1154 "TBS Electronics" 1158 "Technoton Electroics" 1160 "MG Energy Systems" 1169 "Sea Machine Robotics" 1171 "Vista Manufacturing" 1183 "Zipwake" 1186 "Sailmon" 1192 "Airmoniq Pro Kft" 1194 "Sierra Marine" 1200 "Xinuo Information Technology (Xiamen)" 1218 "Septentrio" 1233 "NKE Marine Electronics" 1238 "SuperTrack Aps" 1239 "Honda Electronics" 1245 "Raritan Engineering" 1249 "Integrated Power Solutions AG" 1260 "Interactive Technologies" 1283 "LTG-Tech" 1299 "Energy Solutions (UK)" 1300 "WATT Fuel Cell" 1302 "Pro Mainer" 1305 "Dragonfly Energy" 1306 "Koden Electronics" 1311 "Humphree" 1316 "Hinkley Yachts" 1317 "Global Marine Management GmbH (GMM)" 1320 "Triskel Marine" 1330 "Warwick Control Technologies" 1331 "Dolphin Charger" 1337 "Barnacle Systems" 1348 "Radian IoT" 1353 "Ocean LED Marine" 1359 "BluNav" 1361 "OVA (Nantong Saiyang Electronics Co., Ltd)" 1368 "RAD Propulsion" 1369 "Electric Yacht" 1372 "Elco Motor Yachts" 1384 "Tecnoseal Foundry S.r.l" 1385 "Pro Charging Systems" 1389 "EVEX" 1398 "Gobius Sensor Technology" 1403 "Arco Marine" 1408 "Lenco Marine" 1413 "Naocontrol" 1417 "Revatek" 1438 "Aeolionics" 1439 "PredictWind" 1440 "Egis Mobile Electric" 1445 "Starboard Yacht Group" 1446 "Roswell Marine" 1451 "ePropulsion (Guangdong ePropulsion Technology Ltd.)" 1452 "Micro-Air" 1453 "Vital Battery" 1458 "Ride Controller" 1460 "Tocaro Blue" 1461 "Vanquish Yachts" 1471 "FT Technologies" 1478 "Alps Alpine" 1481 "E-Force Marine" 1482 "CMC Marine" 1483 "Nanjing Sandemarine Information Technology" 1850 "Teleflex Marine (SeaStar Solutions)" 1851 "Raymarine" 1852 "Navionics" 1853 "Japan Radio" 1854 "Northstar Technologies" 1855 "Furuno" 1856 "Trimble" 1857 "Simrad" 1858 "Litton" 1859 "Kvasar" 1860 "MMP" 1861 "Vector Cantech" 1862 "Yamaha Marine" 1863 "Faria Instruments" ;
VAL_ 2566855680 Industry_Code 0 "Global" 1 "Highway" 2 "Agriculture" 3 "Construction" 4 "Marine Industry" 5 "Industrial" ;
VAL_ 2633964800 Manufacturer_Code 69 "ARKS Enterprises" 78 "FW Murphy/Enovation Controls" 80 "Twin Disc" 85 "Kohler Power Systems" 88 "Hemisphere GPS" 135 "Airmar" 137 "Maretron" 140 "Lowrance" 144 "Mercury Marine" 147 "Nautibus Electronic" 148 "Blue Water Data" 154 "Westerbeke" 157 "ISSPRO" 161 "Offshore Systems (UK)" 163 "Evinrude/BRP" 165 "CPAC Systems" 168 "Xantrex Technology" 169 "Marlin Technologies" 172 "Yanmar Marine" 174 "Volvo Penta" 176 "Carling Technologies Inc. (Moritz Aerospace)" 185 "Beede Instruments" 192 "Floscan Instrument" 193 "Nobeltec" 198 "Mystic Valley Communications" 199 "Actia" 201 "Disenos Y Technologia" 211 "Digital Switching Systems" 215 "Xintex/Atena" 224 "EMMI NETWORK" 228 "ZF" 229 "Garmin" 233 "Yacht Monitoring Solutions" 235 "Sailormade Marine Telemetry/Tetra Technology" 243 "Eride" 257 "Honda Motor" 272 "Groco" 273 "Actisense" 274 "Amphenol LTW Technology" 275 "Navico" 283 "Hamilton Jet" 285 "Sea Recovery" 286 "Coelmo SRL Italy" 295 "BEP Marine" 304 "Empir Bus" 305 "NovAtel" 306 "Sleipner Motor" 307 "MBW Technologies" 315 "ICOM" 328 "Qwerty" 329 "Dief" 341 "Boening Automationstechnologie" 345 "Korean Maritime University" 351 "Thrane and Thrane" 355 "Mastervolt" 356 "Fischer Panda Generators" 358 "Victron Energy" 370 "Rolls Royce Marine" 373 "Electronic Design" 374 "Northern Lights" 378 "Glendinning" 381 "B & G" 384 "Rose Point Navigation Systems" 385 "Johnson Outdoors Marine Electronics Inc Geonav" 394 "Capi 2" 396 "Beyond Measure" 400 "Livorsi Marine" 404 "ComNav" 409 "Chetco" 419 "Fusion Electronics" 421 "Standard Horizon" 422 "True Heading" 426 "Egersund Marine Electronics" 427 "em-trak Marine Electronics" 431 "Tohatsu Co, JP" 437 "Digital Yacht" 438 "Comar Systems Limited" 440 "Cummins" 443 "VDO (aka Continental-Corporation)" 451 "Parker Hannifin aka Village Marine Tech" 459 "Alltek Marine Electronics" 460 "SAN GIORGIO S.E.I.N" 466 "Veethree Electronics & Marine" 470 "SI-TEX Marine Electronics" 471 "Sea Cross Marine" 475 "GME aka Standard Communications" 476 "Humminbird Marine Electronics" 478 "Ocean Sat" 481 "Chetco Digital Instruments" 493 "Watcheye" 499 "Lcj Capteurs" 502 "Attwood Marine" 503 "Naviop S.R.L." 504 "Vesper Marine" 510 "Marinesoft" 513 "Simarine" 517 "NoLand Engineering" 518 "Transas USA" 529 "National Instruments Korea" 530 "National Marine Electronics Association" 532 "Onwa Marine" 540 "Webasto" 571 "Marinecraft (South Korea)" 573 "McMurdo Group aka Orolia" 578 "Advansea" 579 "KVH" 580 "San Jose Technology" 583 "Yacht Control" 586 "Suzuki Motor" 591 "US Coast Guard" 595 "Ship Module aka Customware" 600 "Aquatic AV" 605 "Aventics" 606 "Intellian" 612 "SamwonIT" 614 "Arlt Tecnologies" 637 "Bavaria Yachts" 641 "Diverse Yacht Services" 644 "Wema U.S.A dba KUS" 658 "Shenzhen Jiuzhou Himunication" 688 "Rockford" 699 "Harman International" 704 "JL Audio" 708 "Lars Thrane" 715 "Autonnic" 717 "Yacht Devices" 734 "REAP Systems" 735 "AEM Performance Electronics" 739 "LxNav" 741 "Littelfuse, Inc (formerly Carling Technologies)" 743 "DaeMyung" 744 "Woosung" 748 "ISOTTA IFRA srl" 773 "Clarion US" 776 "HMI Systems" 777 "Ocean Signal" 778 "Seakeeper" 781 "Poly Planar" 785 "Fischer Panda DE" 795 "Broyda Industries" 796 "Canadian Automotive" 797 "Tides Marine" 798 "Lumishore" 799 "Still Water Designs and Audio" 802 "BJ Technologies (Beneteau)" 803 "Gill Sensors" 811 "Blue Water Desalination" 815 "FLIR" 824 "Undheim Systems" 826 "Lewmar" 838 "TeamSurv" 844 "Fell Marine" 847 "Oceanvolt" 862 "Prospec" 868 "Data Panel" 890 "L3 Technologies" 894 "Rhodan Marine Systems" 896 "Nexfour Solutions" 905 "ASA Electronics" 909 "Marines Co (South Korea)" 911 "Nautic-on" 917 "Sentinel" 929 "JL Marine Systems" 930 "Ecotronix" 944 "Zontisa Marine" 951 "EXOR International" 962 "Timbolier Industries" 963 "TJC Micro" 968 "Cox Powertrain" 969 "Blue Seas" 981 "Kobelt Manufacturing" 992 "Blue Ocean IOT" 997 "Xenta Systems" 999 "Signal K" 1004 "Ultraflex" 1008 "Lintest SmartBoat" 1011 "Soundmax" 1020 "Team Italia Marine (Onyx Marine Automation s.r.l)" 1021 "Entratech" 1022 "ITC" 1029 "The Marine Guardian" 1047 "Sonic" 1051 "ProNav" 1053 "Vetus Maxwell INC." 1056 "Lithium Pros" 1059 "Boatrax" 1062 "Marol Co ltd" 1065 "CALYPSO Instruments" 1066 "Spot Zero Water" 1069 "Lithionics Battery" 1070 "Quick-teck Electronics" 1075 "Uniden America" 1083 "Nauticoncept" 1084 "Shadow-Caster LED lighting" 1085 "Wet Sounds" 1088 "E-T-A Circuit Breakers" 1092 "Scheiber" 1100 "Smart Yachts International Limited" 1109 "Dockmate" 1114 "Bobs Machine" 1118 "L3Harris ASV" 1119 "Balmar" 1120 "Elettromedia" 1127 "Electromaax" 1140 "Across Oceans Systems" 1145 "Kiwi Yachting" 1150 "BSB Artificial Intelligence" 1151 "Orca Technologies" 1154 "TBS Electronics" 1158 "Technoton Electroics" 1160 "MG Energy Systems" 1169 "Sea Machine Robotics" 1171 "Vista Manufacturing" 1183 "Zipwake" 1186 "Sailmon" 1192 "Airmoniq Pro Kft" 1194 "Sierra Marine" 1200 "Xinuo Information Technology (Xiamen)" 1218 "Septentrio" 1233 "NKE Marine Electronics" 1238 "SuperTrack Aps" 1239 "Honda Electronics" 1245 "Raritan Engineering" 1249 "Integrated Power Solutions AG" 1260 "Interactive Technologies" 1283 "LTG-Tech" 1299 "Energy Solutions (UK)" 1300 "WATT Fuel Cell" 1302 "Pro Mainer" 1305 "Dragonfly Energy" 1306 "Koden Electronics" 1311 "Humphree" 1316 "Hinkley Yachts" 1317 "Global Marine Management GmbH (GMM)" 1320 "Triskel Marine" 1330 "Warwick Control Technologies" 1331 "Dolphin Charger" 1337 "Barnacle Systems" 1348 "Radian IoT" 1353 "Ocean LED Marine" 1359 "BluNav" 1361 "OVA (Nantong Saiyang Electronics Co., Ltd)" 1368 "RAD Propulsion" 1369 "Electric Yacht" 1372 "Elco Motor Yachts" 1384 "Tecnoseal Foundry S.r.l" 1385 "Pro Charging Systems" 1389 "EVEX" 1398 "Gobius Sensor Technology" 1403 "Arco Marine" 1408 "Lenco Marine" 1413 "Naocontrol" 1417 "Revatek" 1438 "Aeolionics" 1439 "PredictWind" 1440 "Egis Mobile Electric" 1445 "Starboard Yacht Group" 1446 "Roswell Marine" 1451 "ePropulsion (Guangdong ePropulsion Technology Ltd.)" 1452 "Micro-Air" 1453 "Vital Battery" 1458 "Ride Controller" 1460 "Tocaro Blue" 1461 "Vanquish Yachts" 1471 "FT Technologies" 1478 "Alps Alpine" 1481 "E-Force Marine" 1482 "CMC Marine" 1483 "Nanjing Sandemarine Information Technology" 1850 "Teleflex Marine (SeaStar Solutions)" 1851 "Raymarine" 1852 "Navionics" 1853 "Japan Radio" 1854 "Northstar Technologies" 1855 "Furuno" 1856 "Trimble" 1857 "Simrad" 1858 "Litton" 1859 "Kvasar" 1860 "MMP" 1861 "Vector Cantech" 1862 "Yamaha Marine" 1863 "Faria Instruments" ;
VAL_ 2633964800 Industry_Code 0 "Global" 1 "Highway" 2 "Agriculture" 3 "Construction" 4 "Marine Industry" 5 "Industrial" ;
VAL_ 2566856192 Manufacturer_Code 69 "ARKS Enterprises" 78 "FW Murphy/Enovation Controls" 80 "Twin Disc" 85 "Kohler Power Systems" 88 "Hemisphere GPS" 135 "Airmar" 137 "Maretron" 140 "Lowrance" 144 "Mercury Marine" 147 "Nautibus Electronic" 148 "Blue Water Data" 154 "Westerbeke" 157 "ISSPRO" 161 "Offshore Systems (UK)" 163 "Evinrude/BRP" 165 "CPAC Systems" 168 "Xantrex Technology" 169 "Marlin Technologies" 172 "Yanmar Marine" 174 "Volvo Penta" 176 "Carling Technologies Inc. (Moritz Aerospace)" 185 "Beede Instruments" 192 "Floscan Instrument" 193 "Nobeltec" 198 "Mystic Valley Communications" 199 "Actia" 201 "Disenos Y Technologia" 211 "Digital Switching Systems" 215 "Xintex/Atena" 224 "EMMI NETWORK" 228 "ZF" 229 "Garmin" 233 "Yacht Monitoring Solutions" 235 "Sailormade Marine Telemetry/Tetra Technology" 243 "Eride" 257 "Honda Motor" 272 "Groco" 273 "Actisense" 274 "Amphenol LTW Technology" 275 "Navico" 283 "Hamilton Jet" 285 "Sea Recovery" 286 "Coelmo SRL Italy" 295 "BEP Marine" 304 "Empir Bus" 305 "NovAtel" 306 "Sleipner Motor" 307 "MBW Technologies" 315 "ICOM" 328 "Qwerty" 329 "Dief" 341 "Boening Automationstechnologie" 345 "Korean Maritime University" 351 "Thrane and Thrane" 355 "Mastervolt" 356 "Fischer Panda Generators" 358 "Victron Energy" 370 "Rolls Royce Marine" 373 "Electronic Design" 374 "Northern Lights" 378 "Glendinning" 381 "B & G" 384 "Rose Point Navigation Systems" 385 "Johnson Outdoors Marine Electronics Inc Geonav" 394 "Capi 2" 396 "Beyond Measure" 400 "Livorsi Marine" 404 "ComNav" 409 "Chetco" 419 "Fusion Electronics" 421 "Standard Horizon" 422 "True Heading" 426 "Egersund Marine Electronics" 427 "em-trak Marine Electronics" 431 "Tohatsu Co, JP" 437 "Digital Yacht" 438 "Comar Systems Limited" 440 "Cummins" 443 "VDO (aka Continental-Corporation)" 451 "Parker Hannifin aka Village Marine Tech" 459 "Alltek Marine Electronics" 460 "SAN GIORGIO S.E.I.N" 466 "Veethree Electronics & Marine" 470 "SI-TEX Marine Electronics" 471 "Sea Cross Marine" 475 "GME aka Standard Communications" 476 "Humminbird Marine Electronics" 478 "Ocean Sat" 481 "Chetco Digital Instruments" 493 "Watcheye" 499 "Lcj Capteurs" 502 "Attwood Marine" 503 "Naviop S.R.L." 504 "Vesper Marine" 510 "Marinesoft" 513 "Simarine" 517 "NoLand Engineering" 518 "Transas USA" 529 "National Instruments Korea" 530 "National Marine Electronics Association" 532 "Onwa Marine" 540 "Webasto" 571 "Marinecraft (South Korea)" 573 "McMurdo Group aka Orolia" 578 "Advansea" 579 "KVH" 580 "San Jose Technology" 583 "Yacht Control" 586 "Suzuki Motor" 591 "US Coast Guard" 595 "Ship Module aka Customware" 600 "Aquatic AV" 605 "Aventics" 606 "Intellian" 612 "SamwonIT" 614 "Arlt Tecnologies" 637 "Bavaria Yachts" 641 "Diverse Yacht Services" 644 "Wema U.S.A dba KUS" 658 "Shenzhen Jiuzhou Himunication" 688 "Rockford" 699 "Harman International" 704 "JL Audio" 708 "Lars Thrane" 715 "Autonnic" 717 "Yacht Devices" 734 "REAP Systems" 735 "AEM Performance Electronics" 739 "LxNav" 741 "Littelfuse, Inc (formerly Carling Technologies)" 743 "DaeMyung" 744 "Woosung" 748 "ISOTTA IFRA srl" 773 "Clarion US" 776 "HMI Systems" 777 "Ocean Signal" 778 "Seakeeper" 781 "Poly Planar" 785 "Fischer Panda DE" 795 "Broyda Industries" 796 "Canadian Automotive" 797 "Tides Marine" 798 "Lumishore" 799 "Still Water Designs and Audio" 802 "BJ Technologies (Beneteau)" 803 "Gill Sensors" 811 "Blue Water Desalination" 815 "FLIR" 824 "Undheim Systems" 826 "Lewmar" 838 "TeamSurv" 844 "Fell Marine" 847 "Oceanvolt" 862 "Prospec" 868 "Data Panel" 890 "L3 Technologies" 894 "Rhodan Marine Systems" 896 "Nexfour Solutions" 905 "ASA Electronics" 909 "Marines Co (South Korea)" 911 "Nautic-on" 917 "Sentinel" 929 "JL Marine Systems" 930 "Ecotronix" 944 "Zontisa Marine" 951 "EXOR International" 962 "Timbolier Industries" 963 "TJC Micro" 968 "Cox Powertrain" 969 "Blue Seas" 981 "Kobelt Manufacturing" 992 "Blue Ocean IOT" 997 "Xenta Systems" 999 "Signal K" 1004 "Ultraflex" 1008 "Lintest SmartBoat" 1011 "Soundmax" 1020 "Team Italia Marine (Onyx Marine Automation s.r.l)" 1021 "Entratech" 1022 "ITC" 1029 "The Marine Guardian" 1047 "Sonic" 1051 "ProNav" 1053 "Vetus Maxwell INC." 1056 "Lithium Pros" 1059 "Boatrax" 1062 "Marol Co ltd" 1065 "CALYPSO Instruments" 1066 "Spot Zero Water" 1069 "Lithionics Battery" 1070 "Quick-teck Electronics" 1075 "Uniden America" 1083 "Nauticoncept" 1084 "Shadow-Caster LED lighting" 1085 "Wet Sounds" 1088 "E-T-A Circuit Breakers" 1092 "Scheiber" 1100 "Smart Yachts International Limited" 1109 "Dockmate" 1114 "Bobs Machine" 1118 "L3Harris ASV" 1119 "Balmar" 1120 "Elettromedia" 1127 "Electromaax" 1140 "Across Oceans Systems" 1145 "Kiwi Yachting" 1150 "BSB Artificial Intelligence" 1151 "Orca Technologies" 1154 "TBS Electronics" 1158 "Technoton Electroics" 1160 "MG Energy Systems" 1169 "Sea Machine Robotics" 1171 "Vista Manufacturing" 1183 "Zipwake" 1186 "Sailmon" 1192 "Airmoniq Pro Kft" 1194 "Sierra Marine" 1200 "Xinuo Information Technology (Xiamen)" 1218 "Septentrio" 1233 "NKE Marine Electronics" 1238 "SuperTrack Aps" 1239 "Honda Electronics" 1245 "Raritan Engineering" 1249 "Integrated Power Solutions AG" 1260 "Interactive Technologies" 1283 "LTG-Tech" 1299 "Energy Solutions (UK)" 1300 "WATT Fuel Cell" 1302 "Pro Mainer" 1305 "Dragonfly Energy" 1306 "Koden Electronics" 1311 "Humphree" 1316 "Hinkley Yachts" 1317 "Global Marine Management GmbH (GMM)" 1320 "Triskel Marine" 1330 "Warwick Control Technologies" 1331 "Dolphin Charger" 1337 "Barnacle Systems" 1348 "Radian IoT" 1353 "Ocean LED Marine" 1359 "BluNav" 1361 "OVA (Nantong Saiyang Electronics Co., Ltd)" 1368 "RAD Propulsion" 1369 "Electric Yacht" 1372 "Elco Motor Yachts" 1384 "Tecnoseal Foundry S.r.l" 1385 "Pro Charging Systems" 1389 "EVEX" 1398 "Gobius Sensor Technology" 1403 "Arco Marine" 1408 "Lenco Marine" 1413 "Naocontrol" 1417 "Revatek" 1438 "Aeolionics" 1439 "PredictWind" 1440 "Egis Mobile Electric" 1445 "Starboard Yacht Group" 1446 "Roswell Marine" 1451 "ePropulsion (Guangdong ePropulsion Technology Ltd.)" 1452 "Micro-Air" 1453 "Vital Battery" 1458 "Ride Controller" 1460 "Tocaro Blue" 1461 "Vanquish Yachts" 1471 "FT Technologies" 1478 "Alps Alpine" 1481 "E-Force Marine" 1482 "CMC Marine" 1483 "Nanjing Sandemarine Information Technology" 1850 "Teleflex Marine (SeaStar Solutions)" 1851 "Raymarine" 1852 "Navionics" 1853 "Japan Radio" 1854 "Northstar Technologies" 1855 "Furuno" 1856 "Trimble" 1857 "Simrad" 1858 "Litton" 1859 "Kvasar" 1860 "MMP" 1861 "Vector Cantech" 1862 "Yamaha Marine" 1863 "Faria Instruments" ;
VAL_ 2566856192 Industry_Code 0 "Global" 1 "Highway" 2 "Agriculture" 3 "Construction" 4 "Marine Industry" 5 "Industrial" ;
VAL_ 2566856448 Manufacturer_Code 69 "ARKS Enterprises" 78 "FW Murphy/Enovation Controls" 80 "Twin Disc" 85 "Kohler Power Systems" 88 "Hemisphere GPS" 135 "Airmar" 137 "Maretron" 140 "Lowrance" 144 "Mercury Marine" 147 "Nautibus Electronic" 148 "Blue Water Data" 154 "Westerbeke" 157 "ISSPRO" 161 "Offshore Systems (UK)" 163 "Evinrude/BRP" 165 "CPAC Systems" 168 "Xantrex Technology" 169 "Marlin Technologies" 172 "Yanmar Marine" 174 "Volvo Penta" 176 "Carling Technologies Inc. (Moritz Aerospace)" 185 "Beede Instruments" 192 "Floscan Instrument" 193 "Nobeltec" 198 "Mystic Valley Communications" 199 "Actia" 201 "Disenos Y Technologia" 211 "Digital Switching Systems" 215 "Xintex/Atena" 224 "EMMI NETWORK" 228 "ZF" 229 "Garmin" 233 "Yacht Monitoring Solutions" 235 "Sailormade Marine Telemetry/Tetra Technology" 243 "Eride" 257 "Honda Motor" 272 "Groco" 273 "Actisense" 274 "Amphenol LTW Technology" 275 "Navico" 283 "Hamilton Jet" 285 "Sea Recovery" 286 "Coelmo SRL Italy" 295 "BEP Marine" 304 "Empir Bus" 305 "NovAtel" 306 "Sleipner Motor" 307 "MBW Technologies" 315 "ICOM" 328 "Qwerty" 329 "Dief" 341 "Boening Automationstechnologie" 345 "Korean Maritime University" 351 "Thrane and Thrane" 355 "Mastervolt" 356 "Fischer Panda Generators" 358 "Victron Energy" 370 "Rolls Royce Marine" 373 "Electronic Design" 374 "Northern Lights" 378 "Glendinning" 381 "B & G" 384 "Rose Point Navigation Systems" 385 "Johnson Outdoors Marine Electronics Inc Geonav" 394 "Capi 2" 396 "Beyond Measure" 400 "Livorsi Marine" 404 "ComNav" 409 "Chetco" 419 "Fusion Electronics" 421 "Standard Horizon" 422 "True Heading" 426 "Egersund Marine Electronics" 427 "em-trak Marine Electronics" 431 "Tohatsu Co, JP" 437 "Digital Yacht" 438 "Comar Systems Limited" 440 "Cummins" 443 "VDO (aka Continental-Corporation)" 451 "Parker Hannifin aka Village Marine Tech" 459 "Alltek Marine Electronics" 460 "SAN GIORGIO S.E.I.N" 466 "Veethree Electronics & Marine" 470 "SI-TEX Marine Electronics" 471 "Sea Cross Marine" 475 "GME aka Standard Communications" 476 "Humminbird Marine Electronics" 478 "Ocean Sat" 481 "Chetco Digital Instruments" 493 "Watcheye" 499 "Lcj Capteurs" 502 "Attwood Marine" 503 "Naviop S.R.L." 504 "Vesper Marine" 510 "Marinesoft" 513 "Simarine" 517 "NoLand Engineering" 518 "Transas USA" 529 "National Instruments Korea" 530 "National Marine Electronics Association" 532 "Onwa Marine" 540 "Webasto" 571 "Marinecraft (South Korea)" 573 "McMurdo Group aka Orolia" 578 "Advansea" 579 "KVH" 580 "San Jose Technology" 583 "Yacht Control" 586 "Suzuki Motor" 591 "US Coast Guard" 595 "Ship Module aka Customware" 600 "Aquatic AV" 605 "Aventics" 606 "Intellian" 612 "SamwonIT" 614 "Arlt Tecnologies" 637 "Bavaria Yachts" 641 "Diverse Yacht Services" 644 "Wema U.S.A dba KUS" 658 "Shenzhen Jiuzhou Himunication" 688 "Rockford" 699 "Harman International" 704 "JL Audio" 708 "Lars Thrane" 715 "Autonnic" 717 "Yacht Devices" 734 "REAP Systems" 735 "AEM Performance Electronics" 739 "LxNav" 741 "Littelfuse, Inc (formerly Carling Technologies)" 743 "DaeMyung" 744 "Woosung" 748 "ISOTTA IFRA srl" 773 "Clarion US" 776 "HMI Systems" 777 "Ocean Signal" 778 "Seakeeper" 781 "Poly Planar" 785 "Fischer Panda DE" 795 "Broyda Industries" 796 "Canadian Automotive" 797 "Tides Marine" 798 "Lumishore" 799 "Still Water Designs and Audio" 802 "BJ Technologies (Beneteau)" 803 "Gill Sensors" 811 "Blue Water Desalination" 815 "FLIR" 824 "Undheim Systems" 826 "Lewmar" 838 "TeamSurv" 844 "Fell Marine" 847 "Oceanvolt" 862 "Prospec" 868 "Data Panel" 890 "L3 Technologies" 894 "Rhodan Marine Systems" 896 "Nexfour Solutions" 905 "ASA Electronics" 909 "Marines Co (South Korea)" 911 "Nautic-on" 917 "Sentinel" 929 "JL Marine Systems" 930 "Ecotronix" 944 "Zontisa Marine" 951 "EXOR International" 962 "Timbolier Industries" 963 "TJC Micro" 968 "Cox Powertrain" 969 "Blue Seas" 981 "Kobelt Manufacturing" 992 "Blue Ocean IOT" 997 "Xenta Systems" 999 "Signal K" 1004 "Ultraflex" 1008 "Lintest SmartBoat" 1011 "Soundmax" 1020 "Team Italia Marine (Onyx Marine Automation s.r.l)" 1021 "Entratech" 1022 "ITC" 1029 "The Marine Guardian" 1047 "Sonic" 1051 "ProNav" 1053 "Vetus Maxwell INC." 1056 "Lithium Pros" 1059 "Boatrax" 1062 "Marol Co ltd" 1065 "CALYPSO Instruments" 1066 "Spot Zero Water" 1069 "Lithionics Battery" 1070 "Quick-teck Electronics" 1075 "Uniden America" 1083 "Nauticoncept" 1084 "Shadow-Caster LED lighting" 1085 "Wet Sounds" 1088 "E-T-A Circuit Breakers" 1092 "Scheiber" 1100 "Smart Yachts International Limited" 1109 "Dockmate" 1114 "Bobs Machine" 1118 "L3Harris ASV" 1119 "Balmar" 1120 "Elettromedia" 1127 "Electromaax" 1140 "Across Oceans Systems" 1145 "Kiwi Yachting" 1150 "BSB Artificial Intelligence" 1151 "Orca Technologies" 1154 "TBS Electronics" 1158 "Technoton Electroics" 1160 "MG Energy Systems" 1169 "Sea Machine Robotics" 1171 "Vista Manufacturing" 1183 "Zipwake" 1186 "Sailmon" 1192 "Airmoniq Pro Kft" 1194 "Sierra Marine" 1200 "Xinuo Information Technology (Xiamen)" 1218 "Septentrio" 1233 "NKE Marine Electronics" 1238 "SuperTrack Aps" 1239 "Honda Electronics" 1245 "Raritan Engineering" 1249 "Integrated Power Solutions AG" 1260 "Interactive Technologies" 1283 "LTG-Tech" 1299 "Energy Solutions (UK)" 1300 "WATT Fuel Cell" 1302 "Pro Mainer" 1305 "Dragonfly Energy" 1306 "Koden Electronics" 1311 "Humphree" 1316 "Hinkley Yachts" 1317 "Global Marine Management GmbH (GMM)" 1320 "Triskel Marine" 1330 "Warwick Control Technologies" 1331 "Dolphin Charger" 1337 "Barnacle Systems" 1348 "Radian IoT" 1353 "Ocean LED Marine" 1359 "BluNav" 1361 "OVA (Nantong Saiyang Electronics Co., Ltd)" 1368 "RAD Propulsion" 1369 "Electric Yacht" 1372 "Elco Motor Yachts" 1384 "Tecnoseal Foundry S.r.l" 1385 "Pro Charging Systems" 1389 "EVEX" 1398 "Gobius Sensor Technology" 1403 "Arco Marine" 1408 "Lenco Marine" 1413 "Naocontrol" 1417 "Revatek" 1438 "Aeolionics" 1439 "PredictWind" 1440 "Egis Mobile Electric" 1445 "Starboard Yacht Group" 1446 "Roswell Marine" 1451 "ePropulsion (Guangdong ePropulsion Technology Ltd.)" 1452 "Micro-Air" 1453 "Vital Battery" 1458 "Ride Controller" 1460 "Tocaro Blue" 1461 "Vanquish Yachts" 1471 "FT Technologies" 1478 "Alps Alpine" 1481 "E-Force Marine" 1482 "CMC Marine" 1483 "Nanjing Sandemarine Information Technology" 1850 "Teleflex Marine (SeaStar Solutions)" 1851 "Raymarine" 1852 "Navionics" 1853 "Japan Radio" 1854 "Northstar Technologies" 1855 "Furuno" 1856 "Trimble" 1857 "Simrad" 1858 "Litton" 1859 "Kvasar" 1860 "MMP" 1861 "Vector Cantech" 1862 "Yamaha Marine" 1863 "Faria Instruments" ;
VAL_ 2566856448 Industry_Code 0 "Global" 1 "Highway" 2 "Agriculture" 3 "Construction" 4 "Marine Industry" 5 "Industrial" ;
VAL_ 2633965568 Manufacturer_Code 69 "ARKS Enterprises" 78 "FW Murphy/Enovation Controls" 80 "Twin Disc" 85 "Kohler Power Systems" 88 "Hemisphere GPS" 135 "Airmar" 137 "Maretron" 140 "Lowrance" 144 "Mercury Marine" 147 "Nautibus Electronic" 148 "Blue Water Data" 154 "Westerbeke" 157 "ISSPRO" 161 "Offshore Systems (UK)" 163 "Evinrude/BRP" 165 "CPAC Systems" 168 "Xantrex Technology" 169 "Marlin Technologies" 172 "Yanmar Marine" 174 "Volvo Penta" 176 "Carling Technologies Inc. (Moritz Aerospace)" 185 "Beede Instruments" 192 "Floscan Instrument" 193 "Nobeltec" 198 "Mystic Valley Communications" 199 "Actia" 201 "Disenos Y Technologia" 211 "Digital Switching Systems" 215 "Xintex/Atena" 224 "EMMI NETWORK" 228 "ZF" 229 "Garmin" 233 "Yacht Monitoring Solutions" 235 "Sailormade Marine Telemetry/Tetra Technology" 243 "Eride" 257 "Honda Motor" 272 "Groco" 273 "Actisense" 274 "Amphenol LTW Technology" 275 "Navico" 283 "Hamilton Jet" 285 "Sea Recovery" 286 "Coelmo SRL Italy" 295 "BEP Marine" 304 "Empir Bus" 305 "NovAtel" 306 "Sleipner Motor" 307 "MBW Technologies" 315 "ICOM" 328 "Qwerty" 329 "Dief" 341 "Boening Automationstechnologie" 345 "Korean Maritime University" 351 "Thrane and Thrane" 355 "Mastervolt" 356 "Fischer Panda Generators" 358 "Victron Energy" 370 "Rolls Royce Marine" 373 "Electronic Design" 374 "Northern Lights" 378 "Glendinning" 381 "B & G" 384 "Rose Point Navigation Systems" 385 "Johnson Outdoors Marine Electronics Inc Geonav" 394 "Capi 2" 396 "Beyond Measure" 400 "Livorsi Marine" 404 "ComNav" 409 "Chetco" 419 "Fusion Electronics" 421 "Standard Horizon" 422 "True Heading" 426 "Egersund Marine Electronics" 427 "em-trak Marine Electronics" 431 "Tohatsu Co, JP" 437 "Digital Yacht" 438 "Comar Systems Limited" 440 "Cummins" 443 "VDO (aka Continental-Corporation)" 451 "Parker Hannifin aka Village Marine Tech" 459 "Alltek Marine Electronics" 460 "SAN GIORGIO S.E.I.N" 466 "Veethree Electronics & Marine" 470 "SI-TEX Marine Electronics" 471 "Sea Cross Marine" 475 "GME aka Standard Communications" 476 "Humminbird Marine Electronics" 478 "Ocean Sat" 481 "Chetco Digital Instruments" 493 "Watcheye" 499 "Lcj Capteurs" 502 "Attwood Marine" 503 "Naviop S.R.L." 504 "Vesper Marine" 510 "Marinesoft" 513 "Simarine" 517 "NoLand Engineering" 518 "Transas USA" 529 "National Instruments Korea" 530 "National Marine Electronics Association" 532 "Onwa Marine" 540 "Webasto" 571 "Marinecraft (South Korea)" 573 "McMurdo Group aka Orolia" 578 "Advansea" 579 "KVH" 580 "San Jose Technology" 583 "Yacht Control" 586 "Suzuki Motor" 591 "US Coast Guard" 595 "Ship Module aka Customware" 600 "Aquatic AV" 605 "Aventics" 606 "Intellian" 612 "SamwonIT" 614 "Arlt Tecnologies" 637 "Bavaria Yachts" 641 "Diverse Yacht Services" 644 "Wema U.S.A dba KUS" 658 "Shenzhen Jiuzhou Himunication" 688 "Rockford" 699 "Harman International" 704 "JL Audio" 708 "Lars Thrane" 715 "Autonnic" 717 "Yacht Devices" 734 "REAP Systems" 735 "AEM Performance Electronics" 739 "LxNav" 741 "Littelfuse, Inc (formerly Carling Technologies)" 743 "DaeMyung" 744 "Woosung" 748 "ISOTTA IFRA srl" 773 "Clarion US" 776 "HMI Systems" 777 "Ocean Signal" 778 "Seakeeper" 781 "Poly Planar" 785 "Fischer Panda DE" 795 "Broyda Industries" 796 "Canadian Automotive" 797 "Tides Marine" 798 "Lumishore" 799 "Still Water Designs and Audio" 802 "BJ Technologies (Beneteau)" 803 "Gill Sensors" 811 "Blue Water Desalination" 815 "FLIR" 824 "Undheim Systems" 826 "Lewmar" 838 "TeamSurv" 844 "Fell Marine" 847 "Oceanvolt" 862 "Prospec" 868 "Data Panel" 890 "L3 Technologies" 894 "Rhodan Marine Systems" 896 "Nexfour Solutions" 905 "ASA Electronics" 909 "Marines Co (South Korea)" 911 "Nautic-on" 917 "Sentinel" 929 "JL Marine Systems" 930 "Ecotronix" 944 "Zontisa Marine" 951 "EXOR International" 962 "Timbolier Industries" 963 "TJC Micro" 968 "Cox Powertrain" 969 "Blue Seas" 981 "Kobelt Manufacturing" 992 "Blue Ocean IOT" 997 "Xenta Systems" 999 "Signal K" 1004 "Ultraflex" 1008 "Lintest SmartBoat" 1011 "Soundmax" 1020 "Team Italia Marine (Onyx Marine Automation s.r.l)" 1021 "Entratech" 1022 "ITC" 1029 "The Marine Guardian" 1047 "Sonic" 1051 "ProNav" 1053 "Vetus Maxwell INC." 1056 "Lithium Pros" 1059 "Boatrax" 1062 "Marol Co ltd" 1065 "CALYPSO Instruments" 1066 "Spot Zero Water" 1069 "Lithionics Battery" 1070 "Quick-teck Electronics" 1075 "Uniden America" 1083 "Nauticoncept" 1084 "Shadow-Caster LED lighting" 1085 "Wet Sounds" 1088 "E-T-A Circuit Breakers" 1092 "Scheiber" 1100 "Smart Yachts International Limited" 1109 "Dockmate" 1114 "Bobs Machine" 1118 "L3Harris ASV" 1119 "Balmar" 1120 "Elettromedia" 1127 "Electromaax" 1140 "Across Oceans Systems" 1145 "Kiwi Yachting" 1150 "BSB Artificial Intelligence" 1151 "Orca Technologies" 1154 "TBS Electronics" 1158 "Technoton Electroics" 1160 "MG Energy Systems" 1169 "Sea Machine Robotics" 1171 "Vista Manufacturing" 1183 "Zipwake" 1186 "Sailmon" 1192 "Airmoniq Pro Kft" 1194 "Sierra Marine" 1200 "Xinuo Information Technology (Xiamen)" 1218 "Septentrio" 1233 "NKE Marine Electronics" 1238 "SuperTrack Aps" 1239 "Honda Electronics" 1245 "Raritan Engineering" 1249 "Integrated Power Solutions AG" 1260 "Interactive Technologies" 1283 "LTG-Tech" 1299 "Energy Solutions (UK)" 1300 "WATT Fuel Cell" 1302 "Pro Mainer" 1305 "Dragonfly Energy" 1306 "Koden Electronics" 1311 "Humphree" 1316 "Hinkley Yachts" 1317 "Global Marine Management GmbH (GMM)" 1320 "Triskel Marine" 1330 "Warwick Control Technologies" 1331 "Dolphin Charger" 1337 "Barnacle Systems" 1348 "Radian IoT" 1353 "Ocean LED Marine" 1359 "BluNav" 1361 "OVA (Nantong Saiyang Electronics Co., Ltd)" 1368 "RAD Propulsion" 1369 "Electric Yacht" 1372 "Elco Motor Yachts" 1384 "Tecnoseal Foundry S.r.l" 1385 "Pro Charging Systems" 1389 "EVEX" 1398 "Gobius Sensor Technology" 1403 "Arco Marine" 1408 "Lenco Marine" 1413 "Naocontrol" 1417 "Revatek" 1438 "Aeolionics" 1439 "PredictWind" 1440 "Egis Mobile Electric" 1445 "Starboard Yacht Group" 1446 "Roswell Marine" 1451 "ePropulsion (Guangdong ePropulsion Technology Ltd.)" 1452 "Micro-Air" 1453 "Vital Battery" 1458 "Ride Controller" 1460 "Tocaro Blue" 1461 "Vanquish Yachts" 1471 "FT Technologies" 1478 "Alps Alpine" 1481 "E-Force Marine" 1482 "CMC Marine" 1483 "Nanjing Sandemarine Information Technology" 1850 "Teleflex Marine (SeaStar Solutions)" 1851 "Raymarine" 1852 "Navionics" 1853 "Japan Radio" 1854 "Northstar Technologies" 1855 "Furuno" 1856 "Trimble" 1857 "Simrad" 1858 "Litton" 1859 "Kvasar" 1860 "MMP" 1861 "Vector Cantech" 1862 "Yamaha Marine" 1863 "Faria Instruments" ;
VAL_ 2633965568 Industry_Code 0 "Global" 1 "Highway" 2 "Agriculture" 3 "Construction" 4 "Marine Industry" 5 "Industrial" ;
VAL_ 2566856960 Manufacturer_Code 69 "ARKS Enterprises" 78 "FW Murphy/Enovation Controls" 80 "Twin Disc" 85 "Kohler Power Systems" 88 "Hemisphere GPS" 135 "Airmar" 137 "Maretron" 140 "Lowrance" 144 "Mercury Marine" 147 "Nautibus Electronic" 148 "Blue Water Data" 154 "Westerbeke" 157 "ISSPRO" 161 "Offshore Systems (UK)" 163 "Evinrude/BRP" 165 "CPAC Systems" 168 "Xantrex Technology" 169 "Marlin Technologies" 172 "Yanmar Marine" 174 "Volvo Penta" 176 "Carling Technologies Inc. (Moritz Aerospace)" 185 "Beede Instruments" 192 "Floscan Instrument" 193 "Nobeltec" 198 "Mystic Valley Communications" 199 "Actia" 201 "Disenos Y Technologia" 211 "Digital Switching Systems" 215 "Xintex/Atena" 224 "EMMI NETWORK" 228 "ZF" 229 "Garmin" 233 "Yacht Monitoring Solutions" 235 "Sailormade Marine Telemetry/Tetra Technology" 243 "Eride" 257 "Honda Motor" 272 "Groco" 273 "Actisense" 274 "Amphenol LTW Technology" 275 "Navico" 283 "Hamilton Jet" 285 "Sea Recovery" 286 "Coelmo SRL Italy" 295 "BEP Marine" 304 "Empir Bus" 305 "NovAtel" 306 "Sleipner Motor" 307 "MBW Technologies" 315 "ICOM" 328 "Qwerty" 329 "Dief" 341 "Boening Automationstechnologie" 345 "Korean Maritime University" 351 "Thrane and Thrane" 355 "Mastervolt" 356 "Fischer Panda Generators" 358 "Victron Energy" 370 "Rolls Royce Marine" 373 "Electronic Design" 374 "Northern Lights" 378 "Glendinning" 381 "B & G" 384 "Rose Point Navigation Systems" 385 "Johnson Outdoors Marine Electronics Inc Geonav" 394 "Capi 2" 396 "Beyond Measure" 400 "Livorsi Marine" 404 "ComNav" 409 "Chetco" 419 "Fusion Electronics" 421 "Standard Horizon" 422 "True Heading" 426 "Egersund Marine Electronics" 427 "em-trak Marine Electronics" 431 "Tohatsu Co, JP" 437 "Digital Yacht" 438 "Comar Systems Limited" 440 "Cummins" 443 "VDO (aka Continental-Corporation)" 451 "Parker Hannifin aka Village Marine Tech" 459 "Alltek Marine Electronics" 460 "SAN GIORGIO S.E.I.N" 466 "Veethree Electronics & Marine" 470 "SI-TEX Marine Electronics" 471 "Sea Cross Marine" 475 "GME aka Standard Communications" 476 "Humminbird Marine Electronics" 478 "Ocean Sat" 481 "Chetco Digital Instruments" 493 "Watcheye" 499 "Lcj Capteurs" 502 "Attwood Marine" 503 "Naviop S.R.L." 504 "Vesper Marine" 510 "Marinesoft" 513 "Simarine" 517 "NoLand Engineering" 518 "Transas USA" 529 "National Instruments Korea" 530 "National Marine Electronics Association" 532 "Onwa Marine" 540 "Webasto" 571 "Marinecraft (South Korea)" 573 "McMurdo Group aka Orolia" 578 "Advansea" 579 "KVH" 580 "San Jose Technology" 583 "Yacht Control" 586 "Suzuki Motor" 591 "US Coast Guard" 595 "Ship Module aka Customware" 600 "Aquatic AV" 605 "Aventics" 606 "Intellian" 612 "SamwonIT" 614 "Arlt Tecnologies" 637 "Bavaria Yachts" 641 "Diverse Yacht Services" 644 "Wema U.S.A dba KUS" 658 "Shenzhen Jiuzhou Himunication" 688 "Rockford" 699 "Harman International" 704 "JL Audio" 708 "Lars Thrane" 715 "Autonnic" 717 "Yacht Devices" 734 "REAP Systems" 735 "AEM Performance Electronics" 739 "LxNav" 741 "Littelfuse, Inc (formerly Carling Technologies)" 743 "DaeMyung" 744 "Woosung" 748 "ISOTTA IFRA srl" 773 "Clarion US" 776 "HMI Systems" 777 "Ocean Signal" 778 "Seakeeper" 781 "Poly Planar" 785 "Fischer Panda DE" 795 "Broyda Industries" 796 "Canadian Automotive" 797 "Tides Marine" 798 "Lumishore" 799 "Still Water Designs and Audio" 802 "BJ Technologies (Beneteau)" 803 "Gill Sensors" 811 "Blue Water Desalination" 815 "FLIR" 824 "Undheim Systems" 826 "Lewmar" 838 "TeamSurv" 844 "Fell Marine" 847 "Oceanvolt" 862 "Prospec" 868 "Data Panel" 890 "L3 Technologies" 894 "Rhodan Marine Systems" 896 "Nexfour Solutions" 905 "ASA Electronics" 909 "Marines Co (South Korea)" 911 "Nautic-on" 917 "Sentinel" 929 "JL Marine Systems" 930 "Ecotronix" 944 "Zontisa Marine" 951 "EXOR International" 962 "Timbolier Industries" 963 "TJC Micro" 968 "Cox Powertrain" 969 "Blue Seas" 981 "Kobelt Manufacturing" 992 "Blue Ocean IOT" 997 "Xenta Systems" 999 "Signal K" 1004 "Ultraflex" 1008 "Lintest SmartBoat" 1011 "Soundmax" 1020 "Team Italia Marine (Onyx Marine Automation s.r.l)" 1021 "Entratech" 1022 "ITC" 1029 "The Marine Guardian" 1047 "Sonic" 1051 "ProNav" 1053 "Vetus Maxwell INC." 1056 "Lithium Pros" 1059 "Boatrax" 1062 "Marol Co ltd" 1065 "CALYPSO Instruments" 1066 "Spot Zero Water" 1069 "Lithionics Battery" 1070 "Quick-teck Electronics" 1075 "Uniden America" 1083 "Nauticoncept" 1084 "Shadow-Caster LED lighting" 1085 "Wet Sounds" 1088 "E-T-A Circuit Breakers" 1092 "Scheiber" 1100 "Smart Yachts International Limited" 1109 "Dockmate" 1114 "Bobs Machine" 1118 "L3Harris ASV" 1119 "Balmar" 1120 "Elettromedia" 1127 "Electromaax" 1140 "Across Oceans Systems" 1145 "Kiwi Yachting" 1150 "BSB Artificial Intelligence" 1151 "Orca Technologies" 1154 "TBS Electronics" 1158 "Technoton Electroics" 1160 "MG Energy Systems" 1169 "Sea Machine Robotics" 1171 "Vista Manufacturing" 1183 "Zipwake" 1186 "Sailmon" 1192 "Airmoniq Pro Kft" 1194 "Sierra Marine" 1200 "Xinuo Information Technology (Xiamen)" 1218 "Septentrio" 1233 "NKE Marine Electronics" 1238 "SuperTrack Aps" 1239 "Honda Electronics" 1245 "Raritan Engineering" 1249 "Integrated Power Solutions AG" 1260 "Interactive Technologies" 1283 "LTG-Tech" 1299 "Energy Solutions (UK)" 1300 "WATT Fuel Cell" 1302 "Pro Mainer" 1305 "Dragonfly Energy" 1306 "Koden Electronics" 1311 "Humphree" 1316 "Hinkley Yachts" 1317 "Global Marine Management GmbH (GMM)" 1320 "Triskel Marine" 1330 "Warwick Control Technologies" 1331 "Dolphin Charger" 1337 "Barnacle Systems" 1348 "Radian IoT" 1353 "Ocean LED Marine" 1359 "BluNav" 1361 "OVA (Nantong Saiyang Electronics Co., Ltd)" 1368 "RAD Propulsion" 1369 "Electric Yacht" 1372 "Elco Motor Yachts" 1384 "Tecnoseal Foundry S.r.l" 1385 "Pro Charging Systems" 1389 "EVEX" 1398 "Gobius Sensor Technology" 1403 "Arco Marine" 1408 "Lenco Marine" 1413 "Naocontrol" 1417 "Revatek" 1438 "Aeolionics" 1439 "PredictWind" 1440 "Egis Mobile Electric" 1445 "Starboard Yacht Group" 1446 "Roswell Marine" 1451 "ePropulsion (Guangdong ePropulsion Technology Ltd.)" 1452 "Micro-Air" 1453 "Vital Battery" 1458 "Ride Controller" 1460 "Tocaro Blue" 1461 "Vanquish Yachts" 1471 "FT Technologies" 1478 "Alps Alpine" 1481 "E-Force Marine" 1482 "CMC Marine" 1483 "Nanjing Sandemarine Information Technology" 1850 "Teleflex Marine (SeaStar Solutions)" 1851 "Raymarine" 1852 "Navionics" 1853 "Japan Radio" 1854 "Northstar Technologies" 1855 "Furuno" 1856 "Trimble" 1857 "Simrad" 1858 "Litton" 1859 "Kvasar" 1860 "MMP" 1861 "Vector Cantech" 1862 "Yamaha Marine" 1863 "Faria Instruments" ;
VAL_ 2566856960 Industry_Code 0 "Global" 1 "Highway" 2 "Agriculture" 3 "Construction" 4 "Marine Industry" 5 "Industrial" ;
VAL_ 2566857216 Manufacturer_Code 69 "ARKS Enterprises" 78 "FW Murphy/Enovation Controls" 80 "Twin Disc" 85 "Kohler Power Systems" 88 "Hemisphere GPS" 135 "Airmar" 137 "Maretron" 140 "Lowrance" 144 "Mercury Marine" 147 "Nautibus Electronic" 148 "Blue Water Data" 154 "Westerbeke" 157 "ISSPRO" 161 "Offshore Systems (UK)" 163 "Evinrude/BRP" 165 "CPAC Systems" 168 "Xantrex Technology" 169 "Marlin Technologies" 172 "Yanmar Marine" 174 "Volvo Penta" 176 "Carling Technologies Inc. (Moritz Aerospace)" 185 "Beede Instruments" 192 "Floscan Instrument" 193 "Nobeltec" 198 "Mystic Valley Communications" 199 "Actia" 201 "Disenos Y Technologia" 211 "Digital Switching Systems" 215 "Xintex/Atena" 224 "EMMI NETWORK" 228 "ZF" 229 "Garmin" 233 "Yacht Monitoring Solutions" 235 "Sailormade Marine Telemetry/Tetra Technology" 243 "Eride" 257 "Honda Motor" 272 "Groco" 273 "Actisense" 274 "Amphenol LTW Technology" 275 "Navico" 283 "Hamilton Jet" 285 "Sea Recovery" 286 "Coelmo SRL Italy" 295 "BEP Marine" 304 "Empir Bus" 305 "NovAtel" 306 "Sleipner Motor" 307 "MBW Technologies" 315 "ICOM" 328 "Qwerty" 329 "Dief" 341 "Boening Automationstechnologie" 345 "Korean Maritime University" 351 "Thrane and Thrane" 355 "Mastervolt" 356 "Fischer Panda Generators" 358 "Victron Energy" 370 "Rolls Royce Marine" 373 "Electronic Design" 374 "Northern Lights" 378 "Glendinning" 381 "B & G" 384 "Rose Point Navigation Systems" 385 "Johnson Outdoors Marine Electronics Inc Geonav" 394 "Capi 2" 396 "Beyond Measure" 400 "Livorsi Marine" 404 "ComNav" 409 "Chetco" 419 "Fusion Electronics" 421 "Standard Horizon" 422 "True Heading" 426 "Egersund Marine Electronics" 427 "em-trak Marine Electronics" 431 "Tohatsu Co, JP" 437 "Digital Yacht" 438 "Comar Systems Limited" 440 "Cummins" 443 "VDO (aka Continental-Corporation)" 451 "Parker Hannifin aka Village Marine Tech" 459 "Alltek Marine Electronics" 460 "SAN GIORGIO S.E.I.N" 466 "Veethree Electronics & Marine" 470 "SI-TEX Marine Electronics" 471 "Sea Cross Marine" 475 "GME aka Standard Communications" 476 "Humminbird Marine Electronics" 478 "Ocean Sat" 481 "Chetco Digital Instruments" 493 "Watcheye" 499 "Lcj Capteurs" 502 "Attwood Marine" 503 "Naviop S.R.L." 504 "Vesper Marine" 510 "Marinesoft" 513 "Simarine" 517 "NoLand Engineering" 518 "Transas USA" 529 "National Instruments Korea" 530 "National Marine Electronics Association" 532 "Onwa Marine" 540 "Webasto" 571 "Marinecraft (South Korea)" 573 "McMurdo Group aka Orolia" 578 "Advansea" 579 "KVH" 580 "San Jose Technology" 583 "Yacht Control" 586 "Suzuki Motor" 591 "US Coast Guard" 595 "Ship Module aka Customware" 600 "Aquatic AV" 605 "Aventics" 606 "Intellian" 612 "SamwonIT" 614 "Arlt Tecnologies" 637 "Bavaria Yachts" 641 "Diverse Yacht Services" 644 "Wema U.S.A dba KUS" 658 "Shenzhen Jiuzhou Himunication" 688 "Rockford" 699 "Harman International" 704 "JL Audio" 708 "Lars Thrane" 715 "Autonnic" 717 "Yacht Devices" 734 "REAP Systems" 735 "AEM Performance Electronics" 739 "LxNav" 741 "Littelfuse, Inc (formerly Carling Technologies)" 743 "DaeMyung" 744 "Woosung" 748 "ISOTTA IFRA srl" 773 "Clarion US" 776 "HMI Systems" 777 "Ocean Signal" 778 "Seakeeper" 781 "Poly Planar" 785 "Fischer Panda DE" 795 "Broyda Industries" 796 "Canadian Automotive" 797 "Tides Marine" 798 "Lumishore" 799 "Still Water Designs and Audio" 802 "BJ Technologies (Beneteau)" 803 "Gill Sensors" 811 "Blue Water Desalination" 815 "FLIR" 824 "Undheim Systems" 826 "Lewmar" 838 "TeamSurv" 844 "Fell Marine" 847 "Oceanvolt" 862 "Prospec" 868 "Data Panel" 890 "L3 Technologies" 894 "Rhodan Marine Systems" 896 "Nexfour Solutions" 905 "ASA Electronics" 909 "Marines Co (South Korea)" 911 "Nautic-on" 917 "Sentinel" 929 "JL Marine Systems" 930 "Ecotronix" 944 "Zontisa Marine" 951 "EXOR International" 962 "Timbolier Industries" 963 "TJC Micro" 968 "Cox Powertrain" 969 "Blue Seas" 981 "Kobelt Manufacturing" 992 "Blue Ocean IOT" 997 "Xenta Systems" 999 "Signal K" 1004 "Ultraflex" 1008 "Lintest SmartBoat" 1011 "Soundmax" 1020 "Team Italia Marine (Onyx Marine Automation s.r.l)" 1021 "Entratech" 1022 "ITC" 1029 "The Marine Guardian" 1047 "Sonic" 1051 "ProNav" 1053 "Vetus Maxwell INC." 1056 "Lithium Pros" 1059 "Boatrax" 1062 "Marol Co ltd" 1065 "CALYPSO Instruments" 1066 "Spot Zero Water" 1069 "Lithionics Battery" 1070 "Quick-teck Electronics" 1075 "Uniden America" 1083 "Nauticoncept" 1084 "Shadow-Caster LED lighting" 1085 "Wet Sounds" 1088 "E-T-A Circuit Breakers" 1092 "Scheiber" 1100 "Smart Yachts International Limited" 1109 "Dockmate" 1114 "Bobs Machine" 1118 "L3Harris ASV" 1119 "Balmar" 1120 "Elettromedia" 1127 "Electromaax" 1140 "Across Oceans Systems" 1145 "Kiwi Yachting" 1150 "BSB Artificial Intelligence" 1151 "Orca Technologies" 1154 "TBS Electronics" 1158 "Technoton Electroics" 1160 "MG Energy Systems" 1169 "Sea Machine Robotics" 1171 "Vista Manufacturing" 1183 "Zipwake" 1186 "Sailmon" 1192 "Airmoniq Pro Kft" 1194 "Sierra Marine" 1200 "Xinuo Information Technology (Xiamen)" 1218 "Septentrio" 1233 "NKE Marine Electronics" 1238 "SuperTrack Aps" 1239 "Honda Electronics" 1245 "Raritan Engineering" 1249 "Integrated Power Solutions AG" 1260 "Interactive Technologies" 1283 "LTG-Tech" 1299 "Energy Solutions (UK)" 1300 "WATT Fuel Cell" 1302 "Pro Mainer" 1305 "Dragonfly Energy" 1306 "Koden Electronics" 1311 "Humphree" 1316 "Hinkley Yachts" 1317 "Global Marine Management GmbH (GMM)" 1320 "Triskel Marine" 1330 "Warwick Control Technologies" 1331 "Dolphin Charger" 1337 "Barnacle Systems" 1348 "Radian IoT" 1353 "Ocean LED Marine" 1359 "BluNav" 1361 "OVA (Nantong Saiyang Electronics Co., Ltd)" 1368 "RAD Propulsion" 1369 "Electric Yacht" 1372 "Elco Motor Yachts" 1384 "Tecnoseal Foundry S.r.l" 1385 "Pro Charging Systems" 1389 "EVEX" 1398 "Gobius Sensor Technology" 1403 "Arco Marine" 1408 "Lenco Marine" 1413 "Naocontrol" 1417 "Revatek" 1438 "Aeolionics" 1439 "PredictWind" 1440 "Egis Mobile Electric" 1445 "Starboard Yacht Group" 1446 "Roswell Marine" 1451 "ePropulsion (Guangdong ePropulsion Technology Ltd.)" 1452 "Micro-Air" 1453 "Vital Battery" 1458 "Ride Controller" 1460 "Tocaro Blue" 1461 "Vanquish Yachts" 1471 "FT Technologies" 1478 "Alps Alpine" 1481 "E-Force Marine" 1482 "CMC Marine" 1483 "Nanjing Sandemarine Information Technology" 1850 "Teleflex Marine (SeaStar Solutions)" 1851 "Raymarine" 1852 "Navionics" 1853 "Japan Radio" 1854 "Northstar Technologies" 1855 "Furuno" 1856 "Trimble" 1857 "Simrad" 1858 "Litton" 1859 "Kvasar" 1860 "MMP" 1861 "Vector Cantech" 1862 "Yamaha Marine" 1863 "Faria Instruments" ;
VAL_ 2566857216 Industry_Code 0 "Global" 1 "Highway" 2 "Agriculture" 3 "Construction" 4 "Marine Industry" 5 "Industrial" ;
VAL_ 2566857216 Manufacturer_Code 69 "ARKS Enterprises" 78 "FW Murphy/Enovation Controls" 80 "Twin Disc" 85 "Kohler Power Systems" 88 "Hemisphere GPS" 135 "Airmar" 137 "Maretron" 140 "Lowrance" 144 "Mercury Marine" 147 "Nautibus Electronic" 148 "Blue Water Data" 154 "Westerbeke" 157 "ISSPRO" 161 "Offshore Systems (UK)" 163 "Evinrude/BRP" 165 "CPAC Systems" 168 "Xantrex Technology" 169 "Marlin Technologies" 172 "Yanmar Marine" 174 "Volvo Penta" 176 "Carling Technologies Inc. (Moritz Aerospace)" 185 "Beede Instruments" 192 "Floscan Instrument" 193 "Nobeltec" 198 "Mystic Valley Communications" 199 "Actia" 201 "Disenos Y Technologia" 211 "Digital Switching Systems" 215 "Xintex/Atena" 224 "EMMI NETWORK" 228 "ZF" 229 "Garmin" 233 "Yacht Monitoring Solutions" 235 "Sailormade Marine Telemetry/Tetra Technology" 243 "Eride" 257 "Honda Motor" 272 "Groco" 273 "Actisense" 274 "Amphenol LTW Technology" 275 "Navico" 283 "Hamilton Jet" 285 "Sea Recovery" 286 "Coelmo SRL Italy" 295 "BEP Marine" 304 "Empir Bus" 305 "NovAtel" 306 "Sleipner Motor" 307 "MBW Technologies" 315 "ICOM" 328 "Qwerty" 329 "Dief" 341 "Boening Automationstechnologie" 345 "Korean Maritime University" 351 "Thrane and Thrane" 355 "Mastervolt" 356 "Fischer Panda Generators" 358 "Victron Energy" 370 "Rolls Royce Marine" 373 "Electronic Design" 374 "Northern Lights" 378 "Glendinning" 381 "B & G" 384 "Rose Point Navigation Systems" 385 "Johnson Outdoors Marine Electronics Inc Geonav" 394 "Capi 2" 396 "Beyond Measure" 400 "Livorsi Marine" 404 "ComNav" 409 "Chetco" 419 "Fusion Electronics" 421 "Standard Horizon" 422 "True Heading" 426 "Egersund Marine Electronics" 427 "em-trak Marine Electronics" 431 "Tohatsu Co, JP" 437 "Digital Yacht" 438 "Comar Systems Limited" 440 "Cummins" 443 "VDO (aka Continental-Corporation)" 451 "Parker Hannifin aka Village Marine Tech" 459 "Alltek Marine Electronics" 460 "SAN GIORGIO S.E.I.N" 466 "Veethree Electronics & Marine" 470 "SI-TEX Marine Electronics" 471 "Sea Cross Marine" 475 "GME aka Standard Communications" 476 "Humminbird Marine Electronics" 478 "Ocean Sat" 481 "Chetco Digital Instruments" 493 "Watcheye" 499 "Lcj Capteurs" 502 "Attwood Marine" 503 "Naviop S.R.L." 504 "Vesper Marine" 510 "Marinesoft" 513 "Simarine" 517 "NoLand Engineering" 518 "Transas USA" 529 "National Instruments Korea" 530 "National Marine Electronics Association" 532 "Onwa Marine" 540 "Webasto" 571 "Marinecraft (South Korea)" 573 "McMurdo Group aka Orolia" 578 "Advansea" 579 "KVH" 580 "San Jose Technology" 583 "Yacht Control" 586 "Suzuki Motor" 591 "US Coast Guard" 595 "Ship Module aka Customware" 600 "Aquatic AV" 605 "Aventics" 606 "Intellian" 612 "SamwonIT" 614 "Arlt Tecnologies" 637 "Bavaria Yachts" 641 "Diverse Yacht Services" 644 "Wema U.S.A dba KUS" 658 "Shenzhen Jiuzhou Himunication" 688 "Rockford" 699 "Harman International" 704 "JL Audio" 708 "Lars Thrane" 715 "Autonnic" 717 "Yacht Devices" 734 "REAP Systems" 735 "AEM Performance Electronics" 739 "LxNav" 741 "Littelfuse, Inc (formerly Carling Technologies)" 743 "DaeMyung" 744 "Woosung" 748 "ISOTTA IFRA srl" 773 "Clarion US" 776 "HMI Systems" 777 "Ocean Signal" 778 "Seakeeper" 781 "Poly Planar" 785 "Fischer Panda DE" 795 "Broyda Industries" 796 "Canadian Automotive" 797 "Tides Marine" 798 "Lumishore" 799 "Still Water Designs and Audio" 802 "BJ Technologies (Beneteau)" 803 "Gill Sensors" 811 "Blue Water Desalination" 815 "FLIR" 824 "Undheim Systems" 826 "Lewmar" 838 "TeamSurv" 844 "Fell Marine" 847 "Oceanvolt" 862 "Prospec" 868 "Data Panel" 890 "L3 Technologies" 894 "Rhodan Marine Systems" 896 "Nexfour Solutions" 905 "ASA Electronics" 909 "Marines Co (South Korea)" 911 "Nautic-on" 917 "Sentinel" 929 "JL Marine Systems" 930 "Ecotronix" 944 "Zontisa Marine" 951 "EXOR International" 962 "Timbolier Industries" 963 "TJC Micro" 968 "Cox Powertrain" 969 "Blue Seas" 981 "Kobelt Manufacturing" 992 "Blue Ocean IOT" 997 "Xenta Systems" 999 "Signal K" 1004 "Ultraflex" 1008 "Lintest SmartBoat" 1011 "Soundmax" 1020 "Team Italia Marine (Onyx Marine Automation s.r.l)" 1021 "Entratech" 1022 "ITC" 1029 "The Marine Guardian" 1047 "Sonic" 1051 "ProNav" 1053 "Vetus Maxwell INC." 1056 "Lithium Pros" 1059 "Boatrax" 1062 "Marol Co ltd" 1065 "CALYPSO Instruments" 1066 "Spot Zero Water" 1069 "Lithionics Battery" 1070 "Quick-teck Electronics" 1075 "Uniden America" 1083 "Nauticoncept" 1084 "Shadow-Caster LED lighting" 1085 "Wet Sounds" 1088 "E-T-A Circuit Breakers" 1092 "Scheiber" 1100 "Smart Yachts International Limited" 1109 "Dockmate" 1114 "Bobs Machine" 1118 "L3Harris ASV" 1119 "Balmar" 1120 "Elettromedia" 1127 "Electromaax" 1140 "Across Oceans Systems" 1145 "Kiwi Yachting" 1150 "BSB Artificial Intelligence" 1151 "Orca Technologies" 1154 "TBS Electronics" 1158 "Technoton Electroics" 1160 "MG Energy Systems" 1169 "Sea Machine Robotics" 1171 "Vista Manufacturing" 1183 "Zipwake" 1186 "Sailmon" 1192 "Airmoniq Pro Kft" 1194 "Sierra Marine" 1200 "Xinuo Information Technology (Xiamen)" 1218 "Septentrio" 1233 "NKE Marine Electronics" 1238 "SuperTrack Aps" 1239 "Honda Electronics" 1245 "Raritan Engineering" 1249 "Integrated Power Solutions AG" 1260 "Interactive Technologies" 1283 "LTG-Tech" 1299 "Energy Solutions (UK)" 1300 "WATT Fuel Cell" 1302 "Pro Mainer" 1305 "Dragonfly Energy" 1306 "Koden Electronics" 1311 "Humphree" 1316 "Hinkley Yachts" 1317 "Global Marine Management GmbH (GMM)" 1320 "Triskel Marine" 1330 "Warwick Control Technologies" 1331 "Dolphin Charger" 1337 "Barnacle Systems" 1348 "Radian IoT" 1353 "Ocean LED Marine" 1359 "BluNav" 1361 "OVA (Nantong Saiyang Electronics Co., Ltd)" 1368 "RAD Propulsion" 1369 "Electric Yacht" 1372 "Elco Motor Yachts" 1384 "Tecnoseal Foundry S.r.l" 1385 "Pro Charging Systems" 1389 "EVEX" 1398 "Gobius Sensor Technology" 1403 "Arco Marine" 1408 "Lenco Marine" 1413 "Naocontrol" 1417 "Revatek" 1438 "Aeolionics" 1439 "PredictWind" 1440 "Egis Mobile Electric" 1445 "Starboard Yacht Group" 1446 "Roswell Marine" 1451 "ePropulsion (Guangdong ePropulsion Technology Ltd.)" 1452 "Micro-Air" 1453 "Vital Battery" 1458 "Ride Controller" 1460 "Tocaro Blue" 1461 "Vanquish Yachts" 1471 "FT Technologies" 1478 "Alps Alpine" 1481 "E-Force Marine" 1482 "CMC Marine" 1483 "Nanjing Sandemarine Information Technology" 1850 "Teleflex Marine (SeaStar Solutions)" 1851 "Raymarine" 1852 "Navionics" 1853 "Japan Radio" 1854 "Northstar Technologies" 1855 "Furuno" 1856 "Trimble" 1857 "Simrad" 1858 "Litton" 1859 "Kvasar" 1860 "MMP" 1861 "Vector Cantech" 1862 "Yamaha Marine" 1863 "Faria Instruments" ;
VAL_ 2566857216 Industry_Code 0 "Global" 1 "Highway" 2 "Agriculture" 3 "Construction" 4 "Marine Industry" 5 "Industrial" ;
VAL_ 2566857216 Neutral 0 "No" 1 "Yes" ;
VAL_ 2566857472 Manufacturer_Code 69 "ARKS Enterprises" 78 "FW Murphy/Enovation Controls" 80 "Twin Disc" 85 "Kohler Power Systems" 88 "Hemisphere GPS" 135 "Airmar" 137 "Maretron" 140 "Lowrance" 144 "Mercury Marine" 147 "Nautibus Electronic" 148 "Blue Water Data" 154 "Westerbeke" 157 "ISSPRO" 161 "Offshore Systems (UK)" 163 "Evinrude/BRP" 165 "CPAC Systems" 168 "Xantrex Technology" 169 "Marlin Technologies" 172 "Yanmar Marine" 174 "Volvo Penta" 176 "Carling Technologies Inc. (Moritz Aerospace)" 185 "Beede Instruments" 192 "Floscan Instrument" 193 "Nobeltec" 198 "Mystic Valley Communications" 199 "Actia" 201 "Disenos Y Technologia" 211 "Digital Switching Systems" 215 "Xintex/Atena" 224 "EMMI NETWORK" 228 "ZF" 229 "Garmin" 233 "Yacht Monitoring Solutions" 235 "Sailormade Marine Telemetry/Tetra Technology" 243 "Eride" 257 "Honda Motor" 272 "Groco" 273 "Actisense" 274 "Amphenol LTW Technology" 275 "Navico" 283 "Hamilton Jet" 285 "Sea Recovery" 286 "Coelmo SRL Italy" 295 "BEP Marine" 304 "Empir Bus" 305 "NovAtel" 306 "Sleipner Motor" 307 "MBW Technologies" 315 "ICOM" 328 "Qwerty" 329 "Dief" 341 "Boening Automationstechnologie" 345 "Korean Maritime University" 351 "Thrane and Thrane" 355 "Mastervolt" 356 "Fischer Panda Generators" 358 "Victron Energy" 370 "Rolls Royce Marine" 373 "Electronic Design" 374 "Northern Lights" 378 "Glendinning" 381 "B & G" 384 "Rose Point Navigation Systems" 385 "Johnson Outdoors Marine Electronics Inc Geonav" 394 "Capi 2" 396 "Beyond Measure" 400 "Livorsi Marine" 404 "ComNav" 409 "Chetco" 419 "Fusion Electronics" 421 "Standard Horizon" 422 "True Heading" 426 "Egersund Marine Electronics" 427 "em-trak Marine Electronics" 431 "Tohatsu Co, JP" 437 "Digital Yacht" 438 "Comar Systems Limited" 440 "Cummins" 443 "VDO (aka Continental-Corporation)" 451 "Parker Hannifin aka Village Marine Tech" 459 "Alltek Marine Electronics" 460 "SAN GIORGIO S.E.I.N" 466 "Veethree Electronics & Marine" 470 "SI-TEX Marine Electronics" 471 "Sea Cross Marine" 475 "GME aka Standard Communications" 476 "Humminbird Marine Electronics" 478 "Ocean Sat" 481 "Chetco Digital Instruments" 493 "Watcheye" 499 "Lcj Capteurs" 502 "Attwood Marine" 503 "Naviop S.R.L." 504 "Vesper Marine" 510 "Marinesoft" 513 "Simarine" 517 "NoLand Engineering" 518 "Transas USA" 529 "National Instruments Korea" 530 "National Marine Electronics Association" 532 "Onwa Marine" 540 "Webasto" 571 "Marinecraft (South Korea)" 573 "McMurdo Group aka Orolia" 578 "Advansea" 579 "KVH" 580 "San Jose Technology" 583 "Yacht Control" 586 "Suzuki Motor" 591 "US Coast Guard" 595 "Ship Module aka Customware" 600 "Aquatic AV" 605 "Aventics" 606 "Intellian" 612 "SamwonIT" 614 "Arlt Tecnologies" 637 "Bavaria Yachts" 641 "Diverse Yacht Services" 644 "Wema U.S.A dba KUS" 658 "Shenzhen Jiuzhou Himunication" 688 "Rockford" 699 "Harman International" 704 "JL Audio" 708 "Lars Thrane" 715 "Autonnic" 717 "Yacht Devices" 734 "REAP Systems" 735 "AEM Performance Electronics" 739 "LxNav" 741 "Littelfuse, Inc (formerly Carling Technologies)" 743 "DaeMyung" 744 "Woosung" 748 "ISOTTA IFRA srl" 773 "Clarion US" 776 "HMI Systems" 777 "Ocean Signal" 778 "Seakeeper" 781 "Poly Planar" 785 "Fischer Panda DE" 795 "Broyda Industries" 796 "Canadian Automotive" 797 "Tides Marine" 798 "Lumishore" 799 "Still Water Designs and Audio" 802 "BJ Technologies (Beneteau)" 803 "Gill Sensors" 811 "Blue Water Desalination" 815 "FLIR" 824 "Undheim Systems" 826 "Lewmar" 838 "TeamSurv" 844 "Fell Marine" 847 "Oceanvolt" 862 "Prospec" 868 "Data Panel" 890 "L3 Technologies" 894 "Rhodan Marine Systems" 896 "Nexfour Solutions" 905 "ASA Electronics" 909 "Marines Co (South Korea)" 911 "Nautic-on" 917 "Sentinel" 929 "JL Marine Systems" 930 "Ecotronix" 944 "Zontisa Marine" 951 "EXOR International" 962 "Timbolier Industries" 963 "TJC Micro" 968 "Cox Powertrain" 969 "Blue Seas" 981 "Kobelt Manufacturing" 992 "Blue Ocean IOT" 997 "Xenta Systems" 999 "Signal K" 1004 "Ultraflex" 1008 "Lintest SmartBoat" 1011 "Soundmax" 1020 "Team Italia Marine (Onyx Marine Automation s.r.l)" 1021 "Entratech" 1022 "ITC" 1029 "The Marine Guardian" 1047 "Sonic" 1051 "ProNav" 1053 "Vetus Maxwell INC." 1056 "Lithium Pros" 1059 "Boatrax" 1062 "Marol Co ltd" 1065 "CALYPSO Instruments" 1066 "Spot Zero Water" 1069 "Lithionics Battery" 1070 "Quick-teck Electronics" 1075 "Uniden America" 1083 "Nauticoncept" 1084 "Shadow-Caster LED lighting" 1085 "Wet Sounds" 1088 "E-T-A Circuit Breakers" 1092 "Scheiber" 1100 "Smart Yachts International Limited" 1109 "Dockmate" 1114 "Bobs Machine" 1118 "L3Harris ASV" 1119 "Balmar" 1120 "Elettromedia" 1127 "Electromaax" 1140 "Across Oceans Systems" 1145 "Kiwi Yachting" 1150 "BSB Artificial Intelligence" 1151 "Orca Technologies" 1154 "TBS Electronics" 1158 "Technoton Electroics" 1160 "MG Energy Systems" 1169 "Sea Machine Robotics" 1171 "Vista Manufacturing" 1183 "Zipwake" 1186 "Sailmon" 1192 "Airmoniq Pro Kft" 1194 "Sierra Marine" 1200 "Xinuo Information Technology (Xiamen)" 1218 "Septentrio" 1233 "NKE Marine Electronics" 1238 "SuperTrack Aps" 1239 "Honda Electronics" 1245 "Raritan Engineering" 1249 "Integrated Power Solutions AG" 1260 "Interactive Technologies" 1283 "LTG-Tech" 1299 "Energy Solutions (UK)" 1300 "WATT Fuel Cell" 1302 "Pro Mainer" 1305 "Dragonfly Energy" 1306 "Koden Electronics" 1311 "Humphree" 1316 "Hinkley Yachts" 1317 "Global Marine Management GmbH (GMM)" 1320 "Triskel Marine" 1330 "Warwick Control Technologies" 1331 "Dolphin Charger" 1337 "Barnacle Systems" 1348 "Radian IoT" 1353 "Ocean LED Marine" 1359 "BluNav" 1361 "OVA (Nantong Saiyang Electronics Co., Ltd)" 1368 "RAD Propulsion" 1369 "Electric Yacht" 1372 "Elco Motor Yachts" 1384 "Tecnoseal Foundry S.r.l" 1385 "Pro Charging Systems" 1389 "EVEX" 1398 "Gobius Sensor Technology" 1403 "Arco Marine" 1408 "Lenco Marine" 1413 "Naocontrol" 1417 "Revatek" 1438 "Aeolionics" 1439 "PredictWind" 1440 "Egis Mobile Electric" 1445 "Starboard Yacht Group" 1446 "Roswell Marine" 1451 "ePropulsion (Guangdong ePropulsion Technology Ltd.)" 1452 "Micro-Air" 1453 "Vital Battery" 1458 "Ride Controller" 1460 "Tocaro Blue" 1461 "Vanquish Yachts" 1471 "FT Technologies" 1478 "Alps Alpine" 1481 "E-Force Marine" 1482 "CMC Marine" 1483 "Nanjing Sandemarine Information Technology" 1850 "Teleflex Marine (SeaStar Solutions)" 1851 "Raymarine" 1852 "Navionics" 1853 "Japan Radio" 1854 "Northstar Technologies" 1855 "Furuno" 1856 "Trimble" 1857 "Simrad" 1858 "Litton" 1859 "Kvasar" 1860 "MMP" 1861 "Vector Cantech" 1862 "Yamaha Marine" 1863 "Faria Instruments" ;
VAL_ 2566857472 Industry_Code 0 "Global" 1 "Highway" 2 "Agriculture" 3 "Construction" 4 "Marine Industry" 5 "Industrial" ;
VAL_ 2566857728 Manufacturer_Code 69 "ARKS Enterprises" 78 "FW Murphy/Enovation Controls" 80 "Twin Disc" 85 "Kohler Power Systems" 88 "Hemisphere GPS" 135 "Airmar" 137 "Maretron" 140 "Lowrance" 144 "Mercury Marine" 147 "Nautibus Electronic" 148 "Blue Water Data" 154 "Westerbeke" 157 "ISSPRO" 161 "Offshore Systems (UK)" 163 "Evinrude/BRP" 165 "CPAC Systems" 168 "Xantrex Technology" 169 "Marlin Technologies" 172 "Yanmar Marine" 174 "Volvo Penta" 176 "Carling Technologies Inc. (Moritz Aerospace)" 185 "Beede Instruments" 192 "Floscan Instrument" 193 "Nobeltec" 198 "Mystic Valley Communications" 199 "Actia" 201 "Disenos Y Technologia" 211 "Digital Switching Systems" 215 "Xintex/Atena" 224 "EMMI NETWORK" 228 "ZF" 229 "Garmin" 233 "Yacht Monitoring Solutions" 235 "Sailormade Marine Telemetry/Tetra Technology" 243 "Eride" 257 "Honda Motor" 272 "Groco" 273 "Actisense" 274 "Amphenol LTW Technology" 275 "Navico" 283 "Hamilton Jet" 285 "Sea Recovery" 286 "Coelmo SRL Italy" 295 "BEP Marine" 304 "Empir Bus" 305 "NovAtel" 306 "Sleipner Motor" 307 "MBW Technologies" 315 "ICOM" 328 "Qwerty" 329 "Dief" 341 "Boening Automationstechnologie" 345 "Korean Maritime University" 351 "Thrane and Thrane" 355 "Mastervolt" 356 "Fischer Panda Generators" 358 "Victron Energy" 370 "Rolls Royce Marine" 373 "Electronic Design" 374 "Northern Lights" 378 "Glendinning" 381 "B & G" 384 "Rose Point Navigation Systems" 385 "Johnson Outdoors Marine Electronics Inc Geonav" 394 "Capi 2" 396 "Beyond Measure" 400 "Livorsi Marine" 404 "ComNav" 409 "Chetco" 419 "Fusion Electronics" 421 "Standard Horizon" 422 "True Heading" 426 "Egersund Marine Electronics" 427 "em-trak Marine Electronics" 431 "Tohatsu Co, JP" 437 "Digital Yacht" 438 "Comar Systems Limited" 440 "Cummins" 443 "VDO (aka Continental-Corporation)" 451 "Parker Hannifin aka Village Marine Tech" 459 "Alltek Marine Electronics" 460 "SAN GIORGIO S.E.I.N" 466 "Veethree Electronics & Marine" 470 "SI-TEX Marine Electronics" 471 "Sea Cross Marine" 475 "GME aka Standard Communications" 476 "Humminbird Marine Electronics" 478 "Ocean Sat" 481 "Chetco Digital Instruments" 493 "Watcheye" 499 "Lcj Capteurs" 502 "Attwood Marine" 503 "Naviop S.R.L." 504 "Vesper Marine" 510 "Marinesoft" 513 "Simarine" 517 "NoLand Engineering" 518 "Transas USA" 529 "National Instruments Korea" 530 "National Marine Electronics Association" 532 "Onwa Marine" 540 "Webasto" 571 "Marinecraft (South Korea)" 573 "McMurdo Group aka Orolia" 578 "Advansea" 579 "KVH" 580 "San Jose Technology" 583 "Yacht Control" 586 "Suzuki Motor" 591 "US Coast Guard" 595 "Ship Module aka Customware" 600 "Aquatic AV" 605 "Aventics" 606 "Intellian" 612 "SamwonIT" 614 "Arlt Tecnologies" 637 "Bavaria Yachts" 641 "Diverse Yacht Services" 644 "Wema U.S.A dba KUS" 658 "Shenzhen Jiuzhou Himunication" 688 "Rockford" 699 "Harman International" 704 "JL Audio" 708 "Lars Thrane" 715 "Autonnic" 717 "Yacht Devices" 734 "REAP Systems" 735 "AEM Performance Electronics" 739 "LxNav" 741 "Littelfuse, Inc (formerly Carling Technologies)" 743 "DaeMyung" 744 "Woosung" 748 "ISOTTA IFRA srl" 773 "Clarion US" 776 "HMI Systems" 777 "Ocean Signal" 778 "Seakeeper" 781 "Poly Planar" 785 "Fischer Panda DE" 795 "Broyda Industries" 796 "Canadian Automotive" 797 "Tides Marine" 798 "Lumishore" 799 "Still Water Designs and Audio" 802 "BJ Technologies (Beneteau)" 803 "Gill Sensors" 811 "Blue Water Desalination" 815 "FLIR" 824 "Undheim Systems" 826 "Lewmar" 838 "TeamSurv" 844 "Fell Marine" 847 "Oceanvolt" 862 "Prospec" 868 "Data Panel" 890 "L3 Technologies" 894 "Rhodan Marine Systems" 896 "Nexfour Solutions" 905 "ASA Electronics" 909 "Marines Co (South Korea)" 911 "Nautic-on" 917 "Sentinel" 929 "JL Marine Systems" 930 "Ecotronix" 944 "Zontisa Marine" 951 "EXOR International" 962 "Timbolier Industries" 963 "TJC Micro" 968 "Cox Powertrain" 969 "Blue Seas" 981 "Kobelt Manufacturing" 992 "Blue Ocean IOT" 997 "Xenta Systems" 999 "Signal K" 1004 "Ultraflex" 1008 "Lintest SmartBoat" 1011 "Soundmax" 1020 "Team Italia Marine (Onyx Marine Automation s.r.l)" 1021 "Entratech" 1022 "ITC" 1029 "The Marine Guardian" 1047 "Sonic" 1051 "ProNav" 1053 "Vetus Maxwell INC." 1056 "Lithium Pros" 1059 "Boatrax" 1062 "Marol Co ltd" 1065 "CALYPSO Instruments" 1066 "Spot Zero Water" 1069 "Lithionics Battery" 1070 "Quick-teck Electronics" 1075 "Uniden America" 1083 "Nauticoncept" 1084 "Shadow-Caster LED lighting" 1085 "Wet Sounds" 1088 "E-T-A Circuit Breakers" 1092 "Scheiber" 1100 "Smart Yachts International Limited" 1109 "Dockmate" 1114 "Bobs Machine" 1118 "L3Harris ASV" 1119 "Balmar" 1120 "Elettromedia" 1127 "Electromaax" 1140 "Across Oceans Systems" 1145 "Kiwi Yachting" 1150 "BSB Artificial Intelligence" 1151 "Orca Technologies" 1154 "TBS Electronics" 1158 "Technoton Electroics" 1160 "MG Energy Systems" 1169 "Sea Machine Robotics" 1171 "Vista Manufacturing" 1183 "Zipwake" 1186 "Sailmon" 1192 "Airmoniq Pro Kft" 1194 "Sierra Marine" 1200 "Xinuo Information Technology (Xiamen)" 1218 "Septentrio" 1233 "NKE Marine Electronics" 1238 "SuperTrack Aps" 1239 "Honda Electronics" 1245 "Raritan Engineering" 1249 "Integrated Power Solutions AG" 1260 "Interactive Technologies" 1283 "LTG-Tech" 1299 "Energy Solutions (UK)" 1300 "WATT Fuel Cell" 1302 "Pro Mainer" 1305 "Dragonfly Energy" 1306 "Koden Electronics" 1311 "Humphree" 1316 "Hinkley Yachts" 1317 "Global Marine Management GmbH (GMM)" 1320 "Triskel Marine" 1330 "Warwick Control Technologies" 1331 "Dolphin Charger" 1337 "Barnacle Systems" 1348 "Radian IoT" 1353 "Ocean LED Marine" 1359 "BluNav" 1361 "OVA (Nantong Saiyang Electronics Co., Ltd)" 1368 "RAD Propulsion" 1369 "Electric Yacht" 1372 "Elco Motor Yachts" 1384 "Tecnoseal Foundry S.r.l" 1385 "Pro Charging Systems" 1389 "EVEX" 1398 "Gobius Sensor Technology" 1403 "Arco Marine" 1408 "Lenco Marine" 1413 "Naocontrol" 1417 "Revatek" 1438 "Aeolionics" 1439 "PredictWind" 1440 "Egis Mobile Electric" 1445 "Starboard Yacht Group" 1446 "Roswell Marine" 1451 "ePropulsion (Guangdong ePropulsion Technology Ltd.)" 1452 "Micro-Air" 1453 "Vital Battery" 1458 "Ride Controller" 1460 "Tocaro Blue" 1461 "Vanquish Yachts" 1471 "FT Technologies" 1478 "Alps Alpine" 1481 "E-Force Marine" 1482 "CMC Marine" 1483 "Nanjing Sandemarine Information Technology" 1850 "Teleflex Marine (SeaStar Solutions)" 1851 "Raymarine" 1852 "Navionics" 1853 "Japan Radio" 1854 "Northstar Technologies" 1855 "Furuno" 1856 "Trimble" 1857 "Simrad" 1858 "Litton" 1859 "Kvasar" 1860 "MMP" 1861 "Vector Cantech" 1862 "Yamaha Marine" 1863 "Faria Instruments" ;
VAL_ 2566857728 Industry_Code 0 "Global" 1 "Highway" 2 "Agriculture" 3 "Construction" 4 "Marine Industry" 5 "Industrial" ;
VAL_ 2566857984 Manufacturer_Code 69 "ARKS Enterprises" 78 "FW Murphy/Enovation Controls" 80 "Twin Disc" 85 "Kohler Power Systems" 88 "Hemisphere GPS" 135 "Airmar" 137 "Maretron" 140 "Lowrance" 144 "Mercury Marine" 147 "Nautibus Electronic" 148 "Blue Water Data" 154 "Westerbeke" 157 "ISSPRO" 161 "Offshore Systems (UK)" 163 "Evinrude/BRP" 165 "CPAC Systems" 168 "Xantrex Technology" 169 "Marlin Technologies" 172 "Yanmar Marine" 174 "Volvo Penta" 176 "Carling Technologies Inc. (Moritz Aerospace)" 185 "Beede Instruments" 192 "Floscan Instrument" 193 "Nobeltec" 198 "Mystic Valley Communications" 199 "Actia" 201 "Disenos Y Technologia" 211 "Digital Switching Systems" 215 "Xintex/Atena" 224 "EMMI NETWORK" 228 "ZF" 229 "Garmin" 233 "Yacht Monitoring Solutions" 235 "Sailormade Marine Telemetry/Tetra Technology" 243 "Eride" 257 "Honda Motor" 272 "Groco" 273 "Actisense" 274 "Amphenol LTW Technology" 275 "Navico" 283 "Hamilton Jet" 285 "Sea Recovery" 286 "Coelmo SRL Italy" 295 "BEP Marine" 304 "Empir Bus" 305 "NovAtel" 306 "Sleipner Motor" 307 "MBW Technologies" 315 "ICOM" 328 "Qwerty" 329 "Dief" 341 "Boening Automationstechnologie" 345 "Korean Maritime University" 351 "Thrane and Thrane" 355 "Mastervolt" 356 "Fischer Panda Generators" 358 "Victron Energy" 370 "Rolls Royce Marine" 373 "Electronic Design" 374 "Northern Lights" 378 "Glendinning" 381 "B & G" 384 "Rose Point Navigation Systems" 385 "Johnson Outdoors Marine Electronics Inc Geonav" 394 "Capi 2" 396 "Beyond Measure" 400 "Livorsi Marine" 404 "ComNav" 409 "Chetco" 419 "Fusion Electronics" 421 "Standard Horizon" 422 "True Heading" 426 "Egersund Marine Electronics" 427 "em-trak Marine Electronics" 431 "Tohatsu Co, JP" 437 "Digital Yacht" 438 "Comar Systems Limited" 440 "Cummins" 443 "VDO (aka Continental-Corporation)" 451 "Parker Hannifin aka Village Marine Tech" 459 "Alltek Marine Electronics" 460 "SAN GIORGIO S.E.I.N" 466 "Veethree Electronics & Marine" 470 "SI-TEX Marine Electronics" 471 "Sea Cross Marine" 475 "GME aka Standard Communications" 476 "Humminbird Marine Electronics" 478 "Ocean Sat" 481 "Chetco Digital Instruments" 493 "Watcheye" 499 "Lcj Capteurs" 502 "Attwood Marine" 503 "Naviop S.R.L." 504 "Vesper Marine" 510 "Marinesoft" 513 "Simarine" 517 "NoLand Engineering" 518 "Transas USA" 529 "National Instruments Korea" 530 "National Marine Electronics Association" 532 "Onwa Marine" 540 "Webasto" 571 "Marinecraft (South Korea)" 573 "McMurdo Group aka Orolia" 578 "Advansea" 579 "KVH" 580 "San Jose Technology" 583 "Yacht Control" 586 "Suzuki Motor" 591 "US Coast Guard" 595 "Ship Module aka Customware" 600 "Aquatic AV" 605 "Aventics" 606 "Intellian" 612 "SamwonIT" 614 "Arlt Tecnologies" 637 "Bavaria Yachts" 641 "Diverse Yacht Services" 644 "Wema U.S.A dba KUS" 658 "Shenzhen Jiuzhou Himunication" 688 "Rockford" 699 "Harman International" 704 "JL Audio" 708 "Lars Thrane" 715 "Autonnic" 717 "Yacht Devices" 734 "REAP Systems" 735 "AEM Performance Electronics" 739 "LxNav" 741 "Littelfuse, Inc (formerly Carling Technologies)" 743 "DaeMyung" 744 "Woosung" 748 "ISOTTA IFRA srl" 773 "Clarion US" 776 "HMI Systems" 777 "Ocean Signal" 778 "Seakeeper" 781 "Poly Planar" 785 "Fischer Panda DE" 795 "Broyda Industries" 796 "Canadian Automotive" 797 "Tides Marine" 798 "Lumishore" 799 "Still Water Designs and Audio" 802 "BJ Technologies (Beneteau)" 803 "Gill Sensors" 811 "Blue Water Desalination" 815 "FLIR" 824 "Undheim Systems" 826 "Lewmar" 838 "TeamSurv" 844 "Fell Marine" 847 "Oceanvolt" 862 "Prospec" 868 "Data Panel" 890 "L3 Technologies" 894 "Rhodan Marine Systems" 896 "Nexfour Solutions" 905 "ASA Electronics" 909 "Marines Co (South Korea)" 911 "Nautic-on" 917 "Sentinel" 929 "JL Marine Systems" 930 "Ecotronix" 944 "Zontisa Marine" 951 "EXOR International" 962 "Timbolier Industries" 963 "TJC Micro" 968 "Cox Powertrain" 969 "Blue Seas" 981 "Kobelt Manufacturing" 992 "Blue Ocean IOT" 997 "Xenta Systems" 999 "Signal K" 1004 "Ultraflex" 1008 "Lintest SmartBoat" 1011 "Soundmax" 1020 "Team Italia Marine (Onyx Marine Automation s.r.l)" 1021 "Entratech" 1022 "ITC" 1029 "The Marine Guardian" 1047 "Sonic" 1051 "ProNav" 1053 "Vetus Maxwell INC." 1056 "Lithium Pros" 1059 "Boatrax" 1062 "Marol Co ltd" 1065 "CALYPSO Instruments" 1066 "Spot Zero Water" 1069 "Lithionics Battery" 1070 "Quick-teck Electronics" 1075 "Uniden America" 1083 "Nauticoncept" 1084 "Shadow-Caster LED lighting" 1085 "Wet Sounds" 1088 "E-T-A Circuit Breakers" 1092 "Scheiber" 1100 "Smart Yachts International Limited" 1109 "Dockmate" 1114 "Bobs Machine" 1118 "L3Harris ASV" 1119 "Balmar" 1120 "Elettromedia" 1127 "Electromaax" 1140 "Across Oceans Systems" 1145 "Kiwi Yachting" 1150 "BSB Artificial Intelligence" 1151 "Orca Technologies" 1154 "TBS Electronics" 1158 "Technoton Electroics" 1160 "MG Energy Systems" 1169 "Sea Machine Robotics" 1171 "Vista Manufacturing" 1183 "Zipwake" 1186 "Sailmon" 1192 "Airmoniq Pro Kft" 1194 "Sierra Marine" 1200 "Xinuo Information Technology (Xiamen)" 1218 "Septentrio" 1233 "NKE Marine Electronics" 1238 "SuperTrack Aps" 1239 "Honda Electronics" 1245 "Raritan Engineering" 1249 "Integrated Power Solutions AG" 1260 "Interactive Technologies" 1283 "LTG-Tech" 1299 "Energy Solutions (UK)" 1300 "WATT Fuel Cell" 1302 "Pro Mainer" 1305 "Dragonfly Energy" 1306 "Koden Electronics" 1311 "Humphree" 1316 "Hinkley Yachts" 1317 "Global Marine Management GmbH (GMM)" 1320 "Triskel Marine" 1330 "Warwick Control Technologies" 1331 "Dolphin Charger" 1337 "Barnacle Systems" 1348 "Radian IoT" 1353 "Ocean LED Marine" 1359 "BluNav" 1361 "OVA (Nantong Saiyang Electronics Co., Ltd)" 1368 "RAD Propulsion" 1369 "Electric Yacht" 1372 "Elco Motor Yachts" 1384 "Tecnoseal Foundry S.r.l" 1385 "Pro Charging Systems" 1389 "EVEX" 1398 "Gobius Sensor Technology" 1403 "Arco Marine" 1408 "Lenco Marine" 1413 "Naocontrol" 1417 "Revatek" 1438 "Aeolionics" 1439 "PredictWind" 1440 "Egis Mobile Electric" 1445 "Starboard Yacht Group" 1446 "Roswell Marine" 1451 "ePropulsion (Guangdong ePropulsion Technology Ltd.)" 1452 "Micro-Air" 1453 "Vital Battery" 1458 "Ride Controller" 1460 "Tocaro Blue" 1461 "Vanquish Yachts" 1471 "FT Technologies" 1478 "Alps Alpine" 1481 "E-Force Marine" 1482 "CMC Marine" 1483 "Nanjing Sandemarine Information Technology" 1850 "Teleflex Marine (SeaStar Solutions)" 1851 "Raymarine" 1852 "Navionics" 1853 "Japan Radio" 1854 "Northstar Technologies" 1855 "Furuno" 1856 "Trimble" 1857 "Simrad" 1858 "Litton" 1859 "Kvasar" 1860 "MMP" 1861 "Vector Cantech" 1862 "Yamaha Marine" 1863 "Faria Instruments" ;
VAL_ 2566857984 Industry_Code 0 "Global" 1 "Highway" 2 "Agriculture" 3 "Construction" 4 "Marine Industry" 5 "Industrial" ;
VAL_ 2365532928 Manufacturer_Code 69 "ARKS Enterprises" 78 "FW Murphy/Enovation Controls" 80 "Twin Disc" 85 "Kohler Power Systems" 88 "Hemisphere GPS" 135 "Airmar" 137 "Maretron" 140 "Lowrance" 144 "Mercury Marine" 147 "Nautibus Electronic" 148 "Blue Water Data" 154 "Westerbeke" 157 "ISSPRO" 161 "Offshore Systems (UK)" 163 "Evinrude/BRP" 165 "CPAC Systems" 168 "Xantrex Technology" 169 "Marlin Technologies" 172 "Yanmar Marine" 174 "Volvo Penta" 176 "Carling Technologies Inc. (Moritz Aerospace)" 185 "Beede Instruments" 192 "Floscan Instrument" 193 "Nobeltec" 198 "Mystic Valley Communications" 199 "Actia" 201 "Disenos Y Technologia" 211 "Digital Switching Systems" 215 "Xintex/Atena" 224 "EMMI NETWORK" 228 "ZF" 229 "Garmin" 233 "Yacht Monitoring Solutions" 235 "Sailormade Marine Telemetry/Tetra Technology" 243 "Eride" 257 "Honda Motor" 272 "Groco" 273 "Actisense" 274 "Amphenol LTW Technology" 275 "Navico" 283 "Hamilton Jet" 285 "Sea Recovery" 286 "Coelmo SRL Italy" 295 "BEP Marine" 304 "Empir Bus" 305 "NovAtel" 306 "Sleipner Motor" 307 "MBW Technologies" 315 "ICOM" 328 "Qwerty" 329 "Dief" 341 "Boening Automationstechnologie" 345 "Korean Maritime University" 351 "Thrane and Thrane" 355 "Mastervolt" 356 "Fischer Panda Generators" 358 "Victron Energy" 370 "Rolls Royce Marine" 373 "Electronic Design" 374 "Northern Lights" 378 "Glendinning" 381 "B & G" 384 "Rose Point Navigation Systems" 385 "Johnson Outdoors Marine Electronics Inc Geonav" 394 "Capi 2" 396 "Beyond Measure" 400 "Livorsi Marine" 404 "ComNav" 409 "Chetco" 419 "Fusion Electronics" 421 "Standard Horizon" 422 "True Heading" 426 "Egersund Marine Electronics" 427 "em-trak Marine Electronics" 431 "Tohatsu Co, JP" 437 "Digital Yacht" 438 "Comar Systems Limited" 440 "Cummins" 443 "VDO (aka Continental-Corporation)" 451 "Parker Hannifin aka Village Marine Tech" 459 "Alltek Marine Electronics" 460 "SAN GIORGIO S.E.I.N" 466 "Veethree Electronics & Marine" 470 "SI-TEX Marine Electronics" 471 "Sea Cross Marine" 475 "GME aka Standard Communications" 476 "Humminbird Marine Electronics" 478 "Ocean Sat" 481 "Chetco Digital Instruments" 493 "Watcheye" 499 "Lcj Capteurs" 502 "Attwood Marine" 503 "Naviop S.R.L." 504 "Vesper Marine" 510 "Marinesoft" 513 "Simarine" 517 "NoLand Engineering" 518 "Transas USA" 529 "National Instruments Korea" 530 "National Marine Electronics Association" 532 "Onwa Marine" 540 "Webasto" 571 "Marinecraft (South Korea)" 573 "McMurdo Group aka Orolia" 578 "Advansea" 579 "KVH" 580 "San Jose Technology" 583 "Yacht Control" 586 "Suzuki Motor" 591 "US Coast Guard" 595 "Ship Module aka Customware" 600 "Aquatic AV" 605 "Aventics" 606 "Intellian" 612 "SamwonIT" 614 "Arlt Tecnologies" 637 "Bavaria Yachts" 641 "Diverse Yacht Services" 644 "Wema U.S.A dba KUS" 658 "Shenzhen Jiuzhou Himunication" 688 "Rockford" 699 "Harman International" 704 "JL Audio" 708 "Lars Thrane" 715 "Autonnic" 717 "Yacht Devices" 734 "REAP Systems" 735 "AEM Performance Electronics" 739 "LxNav" 741 "Littelfuse, Inc (formerly Carling Technologies)" 743 "DaeMyung" 744 "Woosung" 748 "ISOTTA IFRA srl" 773 "Clarion US" 776 "HMI Systems" 777 "Ocean Signal" 778 "Seakeeper" 781 "Poly Planar" 785 "Fischer Panda DE" 795 "Broyda Industries" 796 "Canadian Automotive" 797 "Tides Marine" 798 "Lumishore" 799 "Still Water Designs and Audio" 802 "BJ Technologies (Beneteau)" 803 "Gill Sensors" 811 "Blue Water Desalination" 815 "FLIR" 824 "Undheim Systems" 826 "Lewmar" 838 "TeamSurv" 844 "Fell Marine" 847 "Oceanvolt" 862 "Prospec" 868 "Data Panel" 890 "L3 Technologies" 894 "Rhodan Marine Systems" 896 "Nexfour Solutions" 905 "ASA Electronics" 909 "Marines Co (South Korea)" 911 "Nautic-on" 917 "Sentinel" 929 "JL Marine Systems" 930 "Ecotronix" 944 "Zontisa Marine" 951 "EXOR International" 962 "Timbolier Industries" 963 "TJC Micro" 968 "Cox Powertrain" 969 "Blue Seas" 981 "Kobelt Manufacturing" 992 "Blue Ocean IOT" 997 "Xenta Systems" 999 "Signal K" 1004 "Ultraflex" 1008 "Lintest SmartBoat" 1011 "Soundmax" 1020 "Team Italia Marine (Onyx Marine Automation s.r.l)" 1021 "Entratech" 1022 "ITC" 1029 "The Marine Guardian" 1047 "Sonic" 1051 "ProNav" 1053 "Vetus Maxwell INC." 1056 "Lithium Pros" 1059 "Boatrax" 1062 "Marol Co ltd" 1065 "CALYPSO Instruments" 1066 "Spot Zero Water" 1069 "Lithionics Battery" 1070 "Quick-teck Electronics" 1075 "Uniden America" 1083 "Nauticoncept" 1084 "Shadow-Caster LED lighting" 1085 "Wet Sounds" 1088 "E-T-A Circuit Breakers" 1092 "Scheiber" 1100 "Smart Yachts International Limited" 1109 "Dockmate" 1114 "Bobs Machine" 1118 "L3Harris ASV" 1119 "Balmar" 1120 "Elettromedia" 1127 "Electromaax" 1140 "Across Oceans Systems" 1145 "Kiwi Yachting" 1150 "BSB Artificial Intelligence" 1151 "Orca Technologies" 1154 "TBS Electronics" 1158 "Technoton Electroics" 1160 "MG Energy Systems" 1169 "Sea Machine Robotics" 1171 "Vista Manufacturing" 1183 "Zipwake" 1186 "Sailmon" 1192 "Airmoniq Pro Kft" 1194 "Sierra Marine" 1200 "Xinuo Information Technology (Xiamen)" 1218 "Septentrio" 1233 "NKE Marine Electronics" 1238 "SuperTrack Aps" 1239 "Honda Electronics" 1245 "Raritan Engineering" 1249 "Integrated Power Solutions AG" 1260 "Interactive Technologies" 1283 "LTG-Tech" 1299 "Energy Solutions (UK)" 1300 "WATT Fuel Cell" 1302 "Pro Mainer" 1305 "Dragonfly Energy" 1306 "Koden Electronics" 1311 "Humphree" 1316 "Hinkley Yachts" 1317 "Global Marine Management GmbH (GMM)" 1320 "Triskel Marine" 1330 "Warwick Control Technologies" 1331 "Dolphin Charger" 1337 "Barnacle Systems" 1348 "Radian IoT" 1353 "Ocean LED Marine" 1359 "BluNav" 1361 "OVA (Nantong Saiyang Electronics Co., Ltd)" 1368 "RAD Propulsion" 1369 "Electric Yacht" 1372 "Elco Motor Yachts" 1384 "Tecnoseal Foundry S.r.l" 1385 "Pro Charging Systems" 1389 "EVEX" 1398 "Gobius Sensor Technology" 1403 "Arco Marine" 1408 "Lenco Marine" 1413 "Naocontrol" 1417 "Revatek" 1438 "Aeolionics" 1439 "PredictWind" 1440 "Egis Mobile Electric" 1445 "Starboard Yacht Group" 1446 "Roswell Marine" 1451 "ePropulsion (Guangdong ePropulsion Technology Ltd.)" 1452 "Micro-Air" 1453 "Vital Battery" 1458 "Ride Controller" 1460 "Tocaro Blue" 1461 "Vanquish Yachts" 1471 "FT Technologies" 1478 "Alps Alpine" 1481 "E-Force Marine" 1482 "CMC Marine" 1483 "Nanjing Sandemarine Information Technology" 1850 "Teleflex Marine (SeaStar Solutions)" 1851 "Raymarine" 1852 "Navionics" 1853 "Japan Radio" 1854 "Northstar Technologies" 1855 "Furuno" 1856 "Trimble" 1857 "Simrad" 1858 "Litton" 1859 "Kvasar" 1860 "MMP" 1861 "Vector Cantech" 1862 "Yamaha Marine" 1863 "Faria Instruments" ;
VAL_ 2365532928 Industry_Code 0 "Global" 1 "Highway" 2 "Agriculture" 3 "Construction" 4 "Marine Industry" 5 "Industrial" ;
VAL_ 2365532928 Data_Type 0 "Heading" 1 "Navigation" 2 "Position" 3 "Apparent Wind" 4 "True Wind" 5 "Speed Through Water" 6 "Sea Temperature" 7 "Distance Log" 8 "Depth" 9 "Rudder Feedback" 19 "Monitor Compass" 20 "Position Backup" 21 "Boat Speed Backup" 22 "Air Temperature" 28 "Barometric Pressure" 30 "Heel Angle" 34 "Sailing Navigation" 35 "Trim Angle" 36 "Sailing" 37 "Aft Depth" 38 "Speed Log" 39 "RTCM Signal" 40 "RTCM Corrections" 54 "Autopilot" 59 "Autopilot Function Backup" 104 "Autopilot Control" ;
VAL_ 2365533184 Manufacturer_Code 69 "ARKS Enterprises" 78 "FW Murphy/Enovation Controls" 80 "Twin Disc" 85 "Kohler Power Systems" 88 "Hemisphere GPS" 135 "Airmar" 137 "Maretron" 140 "Lowrance" 144 "Mercury Marine" 147 "Nautibus Electronic" 148 "Blue Water Data" 154 "Westerbeke" 157 "ISSPRO" 161 "Offshore Systems (UK)" 163 "Evinrude/BRP" 165 "CPAC Systems" 168 "Xantrex Technology" 169 "Marlin Technologies" 172 "Yanmar Marine" 174 "Volvo Penta" 176 "Carling Technologies Inc. (Moritz Aerospace)" 185 "Beede Instruments" 192 "Floscan Instrument" 193 "Nobeltec" 198 "Mystic Valley Communications" 199 "Actia" 201 "Disenos Y Technologia" 211 "Digital Switching Systems" 215 "Xintex/Atena" 224 "EMMI NETWORK" 228 "ZF" 229 "Garmin" 233 "Yacht Monitoring Solutions" 235 "Sailormade Marine Telemetry/Tetra Technology" 243 "Eride" 257 "Honda Motor" 272 "Groco" 273 "Actisense" 274 "Amphenol LTW Technology" 275 "Navico" 283 "Hamilton Jet" 285 "Sea Recovery" 286 "Coelmo SRL Italy" 295 "BEP Marine" 304 "Empir Bus" 305 "NovAtel" 306 "Sleipner Motor" 307 "MBW Technologies" 315 "ICOM" 328 "Qwerty" 329 "Dief" 341 "Boening Automationstechnologie" 345 "Korean Maritime University" 351 "Thrane and Thrane" 355 "Mastervolt" 356 "Fischer Panda Generators" 358 "Victron Energy" 370 "Rolls Royce Marine" 373 "Electronic Design" 374 "Northern Lights" 378 "Glendinning" 381 "B & G" 384 "Rose Point Navigation Systems" 385 "Johnson Outdoors Marine Electronics Inc Geonav" 394 "Capi 2" 396 "Beyond Measure" 400 "Livorsi Marine" 404 "ComNav" 409 "Chetco" 419 "Fusion Electronics" 421 "Standard Horizon" 422 "True Heading" 426 "Egersund Marine Electronics" 427 "em-trak Marine Electronics" 431 "Tohatsu Co, JP" 437 "Digital Yacht" 438 "Comar Systems Limited" 440 "Cummins" 443 "VDO (aka Continental-Corporation)" 451 "Parker Hannifin aka Village Marine Tech" 459 "Alltek Marine Electronics" 460 "SAN GIORGIO S.E.I.N" 466 "Veethree Electronics & Marine" 470 "SI-TEX Marine Electronics" 471 "Sea Cross Marine" 475 "GME aka Standard Communications" 476 "Humminbird Marine Electronics" 478 "Ocean Sat" 481 "Chetco Digital Instruments" 493 "Watcheye" 499 "Lcj Capteurs" 502 "Attwood Marine" 503 "Naviop S.R.L." 504 "Vesper Marine" 510 "Marinesoft" 513 "Simarine" 517 "NoLand Engineering" 518 "Transas USA" 529 "National Instruments Korea" 530 "National Marine Electronics Association" 532 "Onwa Marine" 540 "Webasto" 571 "Marinecraft (South Korea)" 573 "McMurdo Group aka Orolia" 578 "Advansea" 579 "KVH" 580 "San Jose Technology" 583 "Yacht Control" 586 "Suzuki Motor" 591 "US Coast Guard" 595 "Ship Module aka Customware" 600 "Aquatic AV" 605 "Aventics" 606 "Intellian" 612 "SamwonIT" 614 "Arlt Tecnologies" 637 "Bavaria Yachts" 641 "Diverse Yacht Services" 644 "Wema U.S.A dba KUS" 658 "Shenzhen Jiuzhou Himunication" 688 "Rockford" 699 "Harman International" 704 "JL Audio" 708 "Lars Thrane" 715 "Autonnic" 717 "Yacht Devices" 734 "REAP Systems" 735 "AEM Performance Electronics" 739 "LxNav" 741 "Littelfuse, Inc (formerly Carling Technologies)" 743 "DaeMyung" 744 "Woosung" 748 "ISOTTA IFRA srl" 773 "Clarion US" 776 "HMI Systems" 777 "Ocean Signal" 778 "Seakeeper" 781 "Poly Planar" 785 "Fischer Panda DE" 795 "Broyda Industries" 796 "Canadian Automotive" 797 "Tides Marine" 798 "Lumishore" 799 "Still Water Designs and Audio" 802 "BJ Technologies (Beneteau)" 803 "Gill Sensors" 811 "Blue Water Desalination" 815 "FLIR" 824 "Undheim Systems" 826 "Lewmar" 838 "TeamSurv" 844 "Fell Marine" 847 "Oceanvolt" 862 "Prospec" 868 "Data Panel" 890 "L3 Technologies" 894 "Rhodan Marine Systems" 896 "Nexfour Solutions" 905 "ASA Electronics" 909 "Marines Co (South Korea)" 911 "Nautic-on" 917 "Sentinel" 929 "JL Marine Systems" 930 "Ecotronix" 944 "Zontisa Marine" 951 "EXOR International" 962 "Timbolier Industries" 963 "TJC Micro" 968 "Cox Powertrain" 969 "Blue Seas" 981 "Kobelt Manufacturing" 992 "Blue Ocean IOT" 997 "Xenta Systems" 999 "Signal K" 1004 "Ultraflex" 1008 "Lintest SmartBoat" 1011 "Soundmax" 1020 "Team Italia Marine (Onyx Marine Automation s.r.l)" 1021 "Entratech" 1022 "ITC" 1029 "The Marine Guardian" 1047 "Sonic" 1051 "ProNav" 1053 "Vetus Maxwell INC." 1056 "Lithium Pros" 1059 "Boatrax" 1062 "Marol Co ltd" 1065 "CALYPSO Instruments" 1066 "Spot Zero Water" 1069 "Lithionics Battery" 1070 "Quick-teck Electronics" 1075 "Uniden America" 1083 "Nauticoncept" 1084 "Shadow-Caster LED lighting" 1085 "Wet Sounds" 1088 "E-T-A Circuit Breakers" 1092 "Scheiber" 1100 "Smart Yachts International Limited" 1109 "Dockmate" 1114 "Bobs Machine" 1118 "L3Harris ASV" 1119 "Balmar" 1120 "Elettromedia" 1127 "Electromaax" 1140 "Across Oceans Systems" 1145 "Kiwi Yachting" 1150 "BSB Artificial Intelligence" 1151 "Orca Technologies" 1154 "TBS Electronics" 1158 "Technoton Electroics" 1160 "MG Energy Systems" 1169 "Sea Machine Robotics" 1171 "Vista Manufacturing" 1183 "Zipwake" 1186 "Sailmon" 1192 "Airmoniq Pro Kft" 1194 "Sierra Marine" 1200 "Xinuo Information Technology (Xiamen)" 1218 "Septentrio" 1233 "NKE Marine Electronics" 1238 "SuperTrack Aps" 1239 "Honda Electronics" 1245 "Raritan Engineering" 1249 "Integrated Power Solutions AG" 1260 "Interactive Technologies" 1283 "LTG-Tech" 1299 "Energy Solutions (UK)" 1300 "WATT Fuel Cell" 1302 "Pro Mainer" 1305 "Dragonfly Energy" 1306 "Koden Electronics" 1311 "Humphree" 1316 "Hinkley Yachts" 1317 "Global Marine Management GmbH (GMM)" 1320 "Triskel Marine" 1330 "Warwick Control Technologies" 1331 "Dolphin Charger" 1337 "Barnacle Systems" 1348 "Radian IoT" 1353 "Ocean LED Marine" 1359 "BluNav" 1361 "OVA (Nantong Saiyang Electronics Co., Ltd)" 1368 "RAD Propulsion" 1369 "Electric Yacht" 1372 "Elco Motor Yachts" 1384 "Tecnoseal Foundry S.r.l" 1385 "Pro Charging Systems" 1389 "EVEX" 1398 "Gobius Sensor Technology" 1403 "Arco Marine" 1408 "Lenco Marine" 1413 "Naocontrol" 1417 "Revatek" 1438 "Aeolionics" 1439 "PredictWind" 1440 "Egis Mobile Electric" 1445 "Starboard Yacht Group" 1446 "Roswell Marine" 1451 "ePropulsion (Guangdong ePropulsion Technology Ltd.)" 1452 "Micro-Air" 1453 "Vital Battery" 1458 "Ride Controller" 1460 "Tocaro Blue" 1461 "Vanquish Yachts" 1471 "FT Technologies" 1478 "Alps Alpine" 1481 "E-Force Marine" 1482 "CMC Marine" 1483 "Nanjing Sandemarine Information Technology" 1850 "Teleflex Marine (SeaStar Solutions)" 1851 "Raymarine" 1852 "Navionics" 1853 "Japan Radio" 1854 "Northstar Technologies" 1855 "Furuno" 1856 "Trimble" 1857 "Simrad" 1858 "Litton" 1859 "Kvasar" 1860 "MMP" 1861 "Vector Cantech" 1862 "Yamaha Marine" 1863 "Faria Instruments" ;
VAL_ 2365533184 Industry_Code 0 "Global" 1 "Highway" 2 "Agriculture" 3 "Construction" 4 "Marine Industry" 5 "Industrial" ;
VAL_ 2566860032 Manufacturer_Code 69 "ARKS Enterprises" 78 "FW Murphy/Enovation Controls" 80 "Twin Disc" 85 "Kohler Power Systems" 88 "Hemisphere GPS" 135 "Airmar" 137 "Maretron" 140 "Lowrance" 144 "Mercury Marine" 147 "Nautibus Electronic" 148 "Blue Water Data" 154 "Westerbeke" 157 "ISSPRO" 161 "Offshore Systems (UK)" 163 "Evinrude/BRP" 165 "CPAC Systems" 168 "Xantrex Technology" 169 "Marlin Technologies" 172 "Yanmar Marine" 174 "Volvo Penta" 176 "Carling Technologies Inc. (Moritz Aerospace)" 185 "Beede Instruments" 192 "Floscan Instrument" 193 "Nobeltec" 198 "Mystic Valley Communications" 199 "Actia" 201 "Disenos Y Technologia" 211 "Digital Switching Systems" 215 "Xintex/Atena" 224 "EMMI NETWORK" 228 "ZF" 229 "Garmin" 233 "Yacht Monitoring Solutions" 235 "Sailormade Marine Telemetry/Tetra Technology" 243 "Eride" 257 "Honda Motor" 272 "Groco" 273 "Actisense" 274 "Amphenol LTW Technology" 275 "Navico" 283 "Hamilton Jet" 285 "Sea Recovery" 286 "Coelmo SRL Italy" 295 "BEP Marine" 304 "Empir Bus" 305 "NovAtel" 306 "Sleipner Motor" 307 "MBW Technologies" 315 "ICOM" 328 "Qwerty" 329 "Dief" 341 "Boening Automationstechnologie" 345 "Korean Maritime University" 351 "Thrane and Thrane" 355 "Mastervolt" 356 "Fischer Panda Generators" 358 "Victron Energy" 370 "Rolls Royce Marine" 373 "Electronic Design" 374 "Northern Lights" 378 "Glendinning" 381 "B & G" 384 "Rose Point Navigation Systems" 385 "Johnson Outdoors Marine Electronics Inc Geonav" 394 "Capi 2" 396 "Beyond Measure" 400 "Livorsi Marine" 404 "ComNav" 409 "Chetco" 419 "Fusion Electronics" 421 "Standard Horizon" 422 "True Heading" 426 "Egersund Marine Electronics" 427 "em-trak Marine Electronics" 431 "Tohatsu Co, JP" 437 "Digital Yacht" 438 "Comar Systems Limited" 440 "Cummins" 443 "VDO (aka Continental-Corporation)" 451 "Parker Hannifin aka Village Marine Tech" 459 "Alltek Marine Electronics" 460 "SAN GIORGIO S.E.I.N" 466 "Veethree Electronics & Marine" 470 "SI-TEX Marine Electronics" 471 "Sea Cross Marine" 475 "GME aka Standard Communications" 476 "Humminbird Marine Electronics" 478 "Ocean Sat" 481 "Chetco Digital Instruments" 493 "Watcheye" 499 "Lcj Capteurs" 502 "Attwood Marine" 503 "Naviop S.R.L." 504 "Vesper Marine" 510 "Marinesoft" 513 "Simarine" 517 "NoLand Engineering" 518 "Transas USA" 529 "National Instruments Korea" 530 "National Marine Electronics Association" 532 "Onwa Marine" 540 "Webasto" 571 "Marinecraft (South Korea)" 573 "McMurdo Group aka Orolia" 578 "Advansea" 579 "KVH" 580 "San Jose Technology" 583 "Yacht Control" 586 "Suzuki Motor" 591 "US Coast Guard" 595 "Ship Module aka Customware" 600 "Aquatic AV" 605 "Aventics" 606 "Intellian" 612 "SamwonIT" 614 "Arlt Tecnologies" 637 "Bavaria Yachts" 641 "Diverse Yacht Services" 644 "Wema U.S.A dba KUS" 658 "Shenzhen Jiuzhou Himunication" 688 "Rockford" 699 "Harman International" 704 "JL Audio" 708 "Lars Thrane" 715 "Autonnic" 717 "Yacht Devices" 734 "REAP Systems" 735 "AEM Performance Electronics" 739 "LxNav" 741 "Littelfuse, Inc (formerly Carling Technologies)" 743 "DaeMyung" 744 "Woosung" 748 "ISOTTA IFRA srl" 773 "Clarion US" 776 "HMI Systems" 777 "Ocean Signal" 778 "Seakeeper" 781 "Poly Planar" 785 "Fischer Panda DE" 795 "Broyda Industries" 796 "Canadian Automotive" 797 "Tides Marine" 798 "Lumishore" 799 "Still Water Designs and Audio" 802 "BJ Technologies (Beneteau)" 803 "Gill Sensors" 811 "Blue Water Desalination" 815 "FLIR" 824 "Undheim Systems" 826 "Lewmar" 838 "TeamSurv" 844 "Fell Marine" 847 "Oceanvolt" 862 "Prospec" 868 "Data Panel" 890 "L3 Technologies" 894 "Rhodan Marine Systems" 896 "Nexfour Solutions" 905 "ASA Electronics" 909 "Marines Co (South Korea)" 911 "Nautic-on" 917 "Sentinel" 929 "JL Marine Systems" 930 "Ecotronix" 944 "Zontisa Marine" 951 "EXOR International" 962 "Timbolier Industries" 963 "TJC Micro" 968 "Cox Powertrain" 969 "Blue Seas" 981 "Kobelt Manufacturing" 992 "Blue Ocean IOT" 997 "Xenta Systems" 999 "Signal K" 1004 "Ultraflex" 1008 "Lintest SmartBoat" 1011 "Soundmax" 1020 "Team Italia Marine (Onyx Marine Automation s.r.l)" 1021 "Entratech" 1022 "ITC" 1029 "The Marine Guardian" 1047 "Sonic" 1051 "ProNav" 1053 "Vetus Maxwell INC." 1056 "Lithium Pros" 1059 "Boatrax" 1062 "Marol Co ltd" 1065 "CALYPSO Instruments" 1066 "Spot Zero Water" 1069 "Lithionics Battery" 1070 "Quick-teck Electronics" 1075 "Uniden America" 1083 "Nauticoncept" 1084 "Shadow-Caster LED lighting" 1085 "Wet Sounds" 1088 "E-T-A Circuit Breakers" 1092 "Scheiber" 1100 "Smart Yachts International Limited" 1109 "Dockmate" 1114 "Bobs Machine" 1118 "L3Harris ASV" 1119 "Balmar" 1120 "Elettromedia" 1127 "Electromaax" 1140 "Across Oceans Systems" 1145 "Kiwi Yachting" 1150 "BSB Artificial Intelligence" 1151 "Orca Technologies" 1154 "TBS Electronics" 1158 "Technoton Electroics" 1160 "MG Energy Systems" 1169 "Sea Machine Robotics" 1171 "Vista Manufacturing" 1183 "Zipwake" 1186 "Sailmon" 1192 "Airmoniq Pro Kft" 1194 "Sierra Marine" 1200 "Xinuo Information Technology (Xiamen)" 1218 "Septentrio" 1233 "NKE Marine Electronics" 1238 "SuperTrack Aps" 1239 "Honda Electronics" 1245 "Raritan Engineering" 1249 "Integrated Power Solutions AG" 1260 "Interactive Technologies" 1283 "LTG-Tech" 1299 "Energy Solutions (UK)" 1300 "WATT Fuel Cell" 1302 "Pro Mainer" 1305 "Dragonfly Energy" 1306 "Koden Electronics" 1311 "Humphree" 1316 "Hinkley Yachts" 1317 "Global Marine Management GmbH (GMM)" 1320 "Triskel Marine" 1330 "Warwick Control Technologies" 1331 "Dolphin Charger" 1337 "Barnacle Systems" 1348 "Radian IoT" 1353 "Ocean LED Marine" 1359 "BluNav" 1361 "OVA (Nantong Saiyang Electronics Co., Ltd)" 1368 "RAD Propulsion" 1369 "Electric Yacht" 1372 "Elco Motor Yachts" 1384 "Tecnoseal Foundry S.r.l" 1385 "Pro Charging Systems" 1389 "EVEX" 1398 "Gobius Sensor Technology" 1403 "Arco Marine" 1408 "Lenco Marine" 1413 "Naocontrol" 1417 "Revatek" 1438 "Aeolionics" 1439 "PredictWind" 1440 "Egis Mobile Electric" 1445 "Starboard Yacht Group" 1446 "Roswell Marine" 1451 "ePropulsion (Guangdong ePropulsion Technology Ltd.)" 1452 "Micro-Air" 1453 "Vital Battery" 1458 "Ride Controller" 1460 "Tocaro Blue" 1461 "Vanquish Yachts" 1471 "FT Technologies" 1478 "Alps Alpine" 1481 "E-Force Marine" 1482 "CMC Marine" 1483 "Nanjing Sandemarine Information Technology" 1850 "Teleflex Marine (SeaStar Solutions)" 1851 "Raymarine" 1852 "Navionics" 1853 "Japan Radio" 1854 "Northstar Technologies" 1855 "Furuno" 1856 "Trimble" 1857 "Simrad" 1858 "Litton" 1859 "Kvasar" 1860 "MMP" 1861 "Vector Cantech" 1862 "Yamaha Marine" 1863 "Faria Instruments" ;
VAL_ 2566860032 Industry_Code 0 "Global" 1 "Highway" 2 "Agriculture" 3 "Construction" 4 "Marine Industry" 5 "Industrial" ;
VAL_ 2566861056 Manufacturer_Code 69 "ARKS Enterprises" 78 "FW Murphy/Enovation Controls" 80 "Twin Disc" 85 "Kohler Power Systems" 88 "Hemisphere GPS" 135 "Airmar" 137 "Maretron" 140 "Lowrance" 144 "Mercury Marine" 147 "Nautibus Electronic" 148 "Blue Water Data" 154 "Westerbeke" 157 "ISSPRO" 161 "Offshore Systems (UK)" 163 "Evinrude/BRP" 165 "CPAC Systems" 168 "Xantrex Technology" 169 "Marlin Technologies" 172 "Yanmar Marine" 174 "Volvo Penta" 176 "Carling Technologies Inc. (Moritz Aerospace)" 185 "Beede Instruments" 192 "Floscan Instrument" 193 "Nobeltec" 198 "Mystic Valley Communications" 199 "Actia" 201 "Disenos Y Technologia" 211 "Digital Switching Systems" 215 "Xintex/Atena" 224 "EMMI NETWORK" 228 "ZF" 229 "Garmin" 233 "Yacht Monitoring Solutions" 235 "Sailormade Marine Telemetry/Tetra Technology" 243 "Eride" 257 "Honda Motor" 272 "Groco" 273 "Actisense" 274 "Amphenol LTW Technology" 275 "Navico" 283 "Hamilton Jet" 285 "Sea Recovery" 286 "Coelmo SRL Italy" 295 "BEP Marine" 304 "Empir Bus" 305 "NovAtel" 306 "Sleipner Motor" 307 "MBW Technologies" 315 "ICOM" 328 "Qwerty" 329 "Dief" 341 "Boening Automationstechnologie" 345 "Korean Maritime University" 351 "Thrane and Thrane" 355 "Mastervolt" 356 "Fischer Panda Generators" 358 "Victron Energy" 370 "Rolls Royce Marine" 373 "Electronic Design" 374 "Northern Lights" 378 "Glendinning" 381 "B & G" 384 "Rose Point Navigation Systems" 385 "Johnson Outdoors Marine Electronics Inc Geonav" 394 "Capi 2" 396 "Beyond Measure" 400 "Livorsi Marine" 404 "ComNav" 409 "Chetco" 419 "Fusion Electronics" 421 "Standard Horizon" 422 "True Heading" 426 "Egersund Marine Electronics" 427 "em-trak Marine Electronics" 431 "Tohatsu Co, JP" 437 "Digital Yacht" 438 "Comar Systems Limited" 440 "Cummins" 443 "VDO (aka Continental-Corporation)" 451 "Parker Hannifin aka Village Marine Tech" 459 "Alltek Marine Electronics" 460 "SAN GIORGIO S.E.I.N" 466 "Veethree Electronics & Marine" 470 "SI-TEX Marine Electronics" 471 "Sea Cross Marine" 475 "GME aka Standard Communications" 476 "Humminbird Marine Electronics" 478 "Ocean Sat" 481 "Chetco Digital Instruments" 493 "Watcheye" 499 "Lcj Capteurs" 502 "Attwood Marine" 503 "Naviop S.R.L." 504 "Vesper Marine" 510 "Marinesoft" 513 "Simarine" 517 "NoLand Engineering" 518 "Transas USA" 529 "National Instruments Korea" 530 "National Marine Electronics Association" 532 "Onwa Marine" 540 "Webasto" 571 "Marinecraft (South Korea)" 573 "McMurdo Group aka Orolia" 578 "Advansea" 579 "KVH" 580 "San Jose Technology" 583 "Yacht Control" 586 "Suzuki Motor" 591 "US Coast Guard" 595 "Ship Module aka Customware" 600 "Aquatic AV" 605 "Aventics" 606 "Intellian" 612 "SamwonIT" 614 "Arlt Tecnologies" 637 "Bavaria Yachts" 641 "Diverse Yacht Services" 644 "Wema U.S.A dba KUS" 658 "Shenzhen Jiuzhou Himunication" 688 "Rockford" 699 "Harman International" 704 "JL Audio" 708 "Lars Thrane" 715 "Autonnic" 717 "Yacht Devices" 734 "REAP Systems" 735 "AEM Performance Electronics" 739 "LxNav" 741 "Littelfuse, Inc (formerly Carling Technologies)" 743 "DaeMyung" 744 "Woosung" 748 "ISOTTA IFRA srl" 773 "Clarion US" 776 "HMI Systems" 777 "Ocean Signal" 778 "Seakeeper" 781 "Poly Planar" 785 "Fischer Panda DE" 795 "Broyda Industries" 796 "Canadian Automotive" 797 "Tides Marine" 798 "Lumishore" 799 "Still Water Designs and Audio" 802 "BJ Technologies (Beneteau)" 803 "Gill Sensors" 811 "Blue Water Desalination" 815 "FLIR" 824 "Undheim Systems" 826 "Lewmar" 838 "TeamSurv" 844 "Fell Marine" 847 "Oceanvolt" 862 "Prospec" 868 "Data Panel" 890 "L3 Technologies" 894 "Rhodan Marine Systems" 896 "Nexfour Solutions" 905 "ASA Electronics" 909 "Marines Co (South Korea)" 911 "Nautic-on" 917 "Sentinel" 929 "JL Marine Systems" 930 "Ecotronix" 944 "Zontisa Marine" 951 "EXOR International" 962 "Timbolier Industries" 963 "TJC Micro" 968 "Cox Powertrain" 969 "Blue Seas" 981 "Kobelt Manufacturing" 992 "Blue Ocean IOT" 997 "Xenta Systems" 999 "Signal K" 1004 "Ultraflex" 1008 "Lintest SmartBoat" 1011 "Soundmax" 1020 "Team Italia Marine (Onyx Marine Automation s.r.l)" 1021 "Entratech" 1022 "ITC" 1029 "The Marine Guardian" 1047 "Sonic" 1051 "ProNav" 1053 "Vetus Maxwell INC." 1056 "Lithium Pros" 1059 "Boatrax" 1062 "Marol Co ltd" 1065 "CALYPSO Instruments" 1066 "Spot Zero Water" 1069 "Lithionics Battery" 1070 "Quick-teck Electronics" 1075 "Uniden America" 1083 "Nauticoncept" 1084 "Shadow-Caster LED lighting" 1085 "Wet Sounds" 1088 "E-T-A Circuit Breakers" 1092 "Scheiber" 1100 "Smart Yachts International Limited" 1109 "Dockmate" 1114 "Bobs Machine" 1118 "L3Harris ASV" 1119 "Balmar" 1120 "Elettromedia" 1127 "Electromaax" 1140 "Across Oceans Systems" 1145 "Kiwi Yachting" 1150 "BSB Artificial Intelligence" 1151 "Orca Technologies" 1154 "TBS Electronics" 1158 "Technoton Electroics" 1160 "MG Energy Systems" 1169 "Sea Machine Robotics" 1171 "Vista Manufacturing" 1183 "Zipwake" 1186 "Sailmon" 1192 "Airmoniq Pro Kft" 1194 "Sierra Marine" 1200 "Xinuo Information Technology (Xiamen)" 1218 "Septentrio" 1233 "NKE Marine Electronics" 1238 "SuperTrack Aps" 1239 "Honda Electronics" 1245 "Raritan Engineering" 1249 "Integrated Power Solutions AG" 1260 "Interactive Technologies" 1283 "LTG-Tech" 1299 "Energy Solutions (UK)" 1300 "WATT Fuel Cell" 1302 "Pro Mainer" 1305 "Dragonfly Energy" 1306 "Koden Electronics" 1311 "Humphree" 1316 "Hinkley Yachts" 1317 "Global Marine Management GmbH (GMM)" 1320 "Triskel Marine" 1330 "Warwick Control Technologies" 1331 "Dolphin Charger" 1337 "Barnacle Systems" 1348 "Radian IoT" 1353 "Ocean LED Marine" 1359 "BluNav" 1361 "OVA (Nantong Saiyang Electronics Co., Ltd)" 1368 "RAD Propulsion" 1369 "Electric Yacht" 1372 "Elco Motor Yachts" 1384 "Tecnoseal Foundry S.r.l" 1385 "Pro Charging Systems" 1389 "EVEX" 1398 "Gobius Sensor Technology" 1403 "Arco Marine" 1408 "Lenco Marine" 1413 "Naocontrol" 1417 "Revatek" 1438 "Aeolionics" 1439 "PredictWind" 1440 "Egis Mobile Electric" 1445 "Starboard Yacht Group" 1446 "Roswell Marine" 1451 "ePropulsion (Guangdong ePropulsion Technology Ltd.)" 1452 "Micro-Air" 1453 "Vital Battery" 1458 "Ride Controller" 1460 "Tocaro Blue" 1461 "Vanquish Yachts" 1471 "FT Technologies" 1478 "Alps Alpine" 1481 "E-Force Marine" 1482 "CMC Marine" 1483 "Nanjing Sandemarine Information Technology" 1850 "Teleflex Marine (SeaStar Solutions)" 1851 "Raymarine" 1852 "Navionics" 1853 "Japan Radio" 1854 "Northstar Technologies" 1855 "Furuno" 1856 "Trimble" 1857 "Simrad" 1858 "Litton" 1859 "Kvasar" 1860 "MMP" 1861 "Vector Cantech" 1862 "Yamaha Marine" 1863 "Faria Instruments" ;
VAL_ 2566861056 Industry_Code 0 "Global" 1 "Highway" 2 "Agriculture" 3 "Construction" 4 "Marine Industry" 5 "Industrial" ;
VAL_ 2566861312 Manufacturer_Code 69 "ARKS Enterprises" 78 "FW Murphy/Enovation Controls" 80 "Twin Disc" 85 "Kohler Power Systems" 88 "Hemisphere GPS" 135 "Airmar" 137 "Maretron" 140 "Lowrance" 144 "Mercury Marine" 147 "Nautibus Electronic" 148 "Blue Water Data" 154 "Westerbeke" 157 "ISSPRO" 161 "Offshore Systems (UK)" 163 "Evinrude/BRP" 165 "CPAC Systems" 168 "Xantrex Technology" 169 "Marlin Technologies" 172 "Yanmar Marine" 174 "Volvo Penta" 176 "Carling Technologies Inc. (Moritz Aerospace)" 185 "Beede Instruments" 192 "Floscan Instrument" 193 "Nobeltec" 198 "Mystic Valley Communications" 199 "Actia" 201 "Disenos Y Technologia" 211 "Digital Switching Systems" 215 "Xintex/Atena" 224 "EMMI NETWORK" 228 "ZF" 229 "Garmin" 233 "Yacht Monitoring Solutions" 235 "Sailormade Marine Telemetry/Tetra Technology" 243 "Eride" 257 "Honda Motor" 272 "Groco" 273 "Actisense" 274 "Amphenol LTW Technology" 275 "Navico" 283 "Hamilton Jet" 285 "Sea Recovery" 286 "Coelmo SRL Italy" 295 "BEP Marine" 304 "Empir Bus" 305 "NovAtel" 306 "Sleipner Motor" 307 "MBW Technologies" 315 "ICOM" 328 "Qwerty" 329 "Dief" 341 "Boening Automationstechnologie" 345 "Korean Maritime University" 351 "Thrane and Thrane" 355 "Mastervolt" 356 "Fischer Panda Generators" 358 "Victron Energy" 370 "Rolls Royce Marine" 373 "Electronic Design" 374 "Northern Lights" 378 "Glendinning" 381 "B & G" 384 "Rose Point Navigation Systems" 385 "Johnson Outdoors Marine Electronics Inc Geonav" 394 "Capi 2" 396 "Beyond Measure" 400 "Livorsi Marine" 404 "ComNav" 409 "Chetco" 419 "Fusion Electronics" 421 "Standard Horizon" 422 "True Heading" 426 "Egersund Marine Electronics" 427 "em-trak Marine Electronics" 431 "Tohatsu Co, JP" 437 "Digital Yacht" 438 "Comar Systems Limited" 440 "Cummins" 443 "VDO (aka Continental-Corporation)" 451 "Parker Hannifin aka Village Marine Tech" 459 "Alltek Marine Electronics" 460 "SAN GIORGIO S.E.I.N" 466 "Veethree Electronics & Marine" 470 "SI-TEX Marine Electronics" 471 "Sea Cross Marine" 475 "GME aka Standard Communications" 476 "Humminbird Marine Electronics" 478 "Ocean Sat" 481 "Chetco Digital Instruments" 493 "Watcheye" 499 "Lcj Capteurs" 502 "Attwood Marine" 503 "Naviop S.R.L." 504 "Vesper Marine" 510 "Marinesoft" 513 "Simarine" 517 "NoLand Engineering" 518 "Transas USA" 529 "National Instruments Korea" 530 "National Marine Electronics Association" 532 "Onwa Marine" 540 "Webasto" 571 "Marinecraft (South Korea)" 573 "McMurdo Group aka Orolia" 578 "Advansea" 579 "KVH" 580 "San Jose Technology" 583 "Yacht Control" 586 "Suzuki Motor" 591 "US Coast Guard" 595 "Ship Module aka Customware" 600 "Aquatic AV" 605 "Aventics" 606 "Intellian" 612 "SamwonIT" 614 "Arlt Tecnologies" 637 "Bavaria Yachts" 641 "Diverse Yacht Services" 644 "Wema U.S.A dba KUS" 658 "Shenzhen Jiuzhou Himunication" 688 "Rockford" 699 "Harman International" 704 "JL Audio" 708 "Lars Thrane" 715 "Autonnic" 717 "Yacht Devices" 734 "REAP Systems" 735 "AEM Performance Electronics" 739 "LxNav" 741 "Littelfuse, Inc (formerly Carling Technologies)" 743 "DaeMyung" 744 "Woosung" 748 "ISOTTA IFRA srl" 773 "Clarion US" 776 "HMI Systems" 777 "Ocean Signal" 778 "Seakeeper" 781 "Poly Planar" 785 "Fischer Panda DE" 795 "Broyda Industries" 796 "Canadian Automotive" 797 "Tides Marine" 798 "Lumishore" 799 "Still Water Designs and Audio" 802 "BJ Technologies (Beneteau)" 803 "Gill Sensors" 811 "Blue Water Desalination" 815 "FLIR" 824 "Undheim Systems" 826 "Lewmar" 838 "TeamSurv" 844 "Fell Marine" 847 "Oceanvolt" 862 "Prospec" 868 "Data Panel" 890 "L3 Technologies" 894 "Rhodan Marine Systems" 896 "Nexfour Solutions" 905 "ASA Electronics" 909 "Marines Co (South Korea)" 911 "Nautic-on" 917 "Sentinel" 929 "JL Marine Systems" 930 "Ecotronix" 944 "Zontisa Marine" 951 "EXOR International" 962 "Timbolier Industries" 963 "TJC Micro" 968 "Cox Powertrain" 969 "Blue Seas" 981 "Kobelt Manufacturing" 992 "Blue Ocean IOT" 997 "Xenta Systems" 999 "Signal K" 1004 "Ultraflex" 1008 "Lintest SmartBoat" 1011 "Soundmax" 1020 "Team Italia Marine (Onyx Marine Automation s.r.l)" 1021 "Entratech" 1022 "ITC" 1029 "The Marine Guardian" 1047 "Sonic" 1051 "ProNav" 1053 "Vetus Maxwell INC." 1056 "Lithium Pros" 1059 "Boatrax" 1062 "Marol Co ltd" 1065 "CALYPSO Instruments" 1066 "Spot Zero Water" 1069 "Lithionics Battery" 1070 "Quick-teck Electronics" 1075 "Uniden America" 1083 "Nauticoncept" 1084 "Shadow-Caster LED lighting" 1085 "Wet Sounds" 1088 "E-T-A Circuit Breakers" 1092 "Scheiber" 1100 "Smart Yachts International Limited" 1109 "Dockmate" 1114 "Bobs Machine" 1118 "L3Harris ASV" 1119 "Balmar" 1120 "Elettromedia" 1127 "Electromaax" 1140 "Across Oceans Systems" 1145 "Kiwi Yachting" 1150 "BSB Artificial Intelligence" 1151 "Orca Technologies" 1154 "TBS Electronics" 1158 "Technoton Electroics" 1160 "MG Energy Systems" 1169 "Sea Machine Robotics" 1171 "Vista Manufacturing" 1183 "Zipwake" 1186 "Sailmon" 1192 "Airmoniq Pro Kft" 1194 "Sierra Marine" 1200 "Xinuo Information Technology (Xiamen)" 1218 "Septentrio" 1233 "NKE Marine Electronics" 1238 "SuperTrack Aps" 1239 "Honda Electronics" 1245 "Raritan Engineering" 1249 "Integrated Power Solutions AG" 1260 "Interactive Technologies" 1283 "LTG-Tech" 1299 "Energy Solutions (UK)" 1300 "WATT Fuel Cell" 1302 "Pro Mainer" 1305 "Dragonfly Energy" 1306 "Koden Electronics" 1311 "Humphree" 1316 "Hinkley Yachts" 1317 "Global Marine Management GmbH (GMM)" 1320 "Triskel Marine" 1330 "Warwick Control Technologies" 1331 "Dolphin Charger" 1337 "Barnacle Systems" 1348 "Radian IoT" 1353 "Ocean LED Marine" 1359 "BluNav" 1361 "OVA (Nantong Saiyang Electronics Co., Ltd)" 1368 "RAD Propulsion" 1369 "Electric Yacht" 1372 "Elco Motor Yachts" 1384 "Tecnoseal Foundry S.r.l" 1385 "Pro Charging Systems" 1389 "EVEX" 1398 "Gobius Sensor Technology" 1403 "Arco Marine" 1408 "Lenco Marine" 1413 "Naocontrol" 1417 "Revatek" 1438 "Aeolionics" 1439 "PredictWind" 1440 "Egis Mobile Electric" 1445 "Starboard Yacht Group" 1446 "Roswell Marine" 1451 "ePropulsion (Guangdong ePropulsion Technology Ltd.)" 1452 "Micro-Air" 1453 "Vital Battery" 1458 "Ride Controller" 1460 "Tocaro Blue" 1461 "Vanquish Yachts" 1471 "FT Technologies" 1478 "Alps Alpine" 1481 "E-Force Marine" 1482 "CMC Marine" 1483 "Nanjing Sandemarine Information Technology" 1850 "Teleflex Marine (SeaStar Solutions)" 1851 "Raymarine" 1852 "Navionics" 1853 "Japan Radio" 1854 "Northstar Technologies" 1855 "Furuno" 1856 "Trimble" 1857 "Simrad" 1858 "Litton" 1859 "Kvasar" 1860 "MMP" 1861 "Vector Cantech" 1862 "Yamaha Marine" 1863 "Faria Instruments" ;
VAL_ 2566861312 Industry_Code 0 "Global" 1 "Highway" 2 "Agriculture" 3 "Construction" 4 "Marine Industry" 5 "Industrial" ;
VAL_ 2566861824 Manufacturer_Code 69 "ARKS Enterprises" 78 "FW Murphy/Enovation Controls" 80 "Twin Disc" 85 "Kohler Power Systems" 88 "Hemisphere GPS" 135 "Airmar" 137 "Maretron" 140 "Lowrance" 144 "Mercury Marine" 147 "Nautibus Electronic" 148 "Blue Water Data" 154 "Westerbeke" 157 "ISSPRO" 161 "Offshore Systems (UK)" 163 "Evinrude/BRP" 165 "CPAC Systems" 168 "Xantrex Technology" 169 "Marlin Technologies" 172 "Yanmar Marine" 174 "Volvo Penta" 176 "Carling Technologies Inc. (Moritz Aerospace)" 185 "Beede Instruments" 192 "Floscan Instrument" 193 "Nobeltec" 198 "Mystic Valley Communications" 199 "Actia" 201 "Disenos Y Technologia" 211 "Digital Switching Systems" 215 "Xintex/Atena" 224 "EMMI NETWORK" 228 "ZF" 229 "Garmin" 233 "Yacht Monitoring Solutions" 235 "Sailormade Marine Telemetry/Tetra Technology" 243 "Eride" 257 "Honda Motor" 272 "Groco" 273 "Actisense" 274 "Amphenol LTW Technology" 275 "Navico" 283 "Hamilton Jet" 285 "Sea Recovery" 286 "Coelmo SRL Italy" 295 "BEP Marine" 304 "Empir Bus" 305 "NovAtel" 306 "Sleipner Motor" 307 "MBW Technologies" 315 "ICOM" 328 "Qwerty" 329 "Dief" 341 "Boening Automationstechnologie" 345 "Korean Maritime University" 351 "Thrane and Thrane" 355 "Mastervolt" 356 "Fischer Panda Generators" 358 "Victron Energy" 370 "Rolls Royce Marine" 373 "Electronic Design" 374 "Northern Lights" 378 "Glendinning" 381 "B & G" 384 "Rose Point Navigation Systems" 385 "Johnson Outdoors Marine Electronics Inc Geonav" 394 "Capi 2" 396 "Beyond Measure" 400 "Livorsi Marine" 404 "ComNav" 409 "Chetco" 419 "Fusion Electronics" 421 "Standard Horizon" 422 "True Heading" 426 "Egersund Marine Electronics" 427 "em-trak Marine Electronics" 431 "Tohatsu Co, JP" 437 "Digital Yacht" 438 "Comar Systems Limited" 440 "Cummins" 443 "VDO (aka Continental-Corporation)" 451 "Parker Hannifin aka Village Marine Tech" 459 "Alltek Marine Electronics" 460 "SAN GIORGIO S.E.I.N" 466 "Veethree Electronics & Marine" 470 "SI-TEX Marine Electronics" 471 "Sea Cross Marine" 475 "GME aka Standard Communications" 476 "Humminbird Marine Electronics" 478 "Ocean Sat" 481 "Chetco Digital Instruments" 493 "Watcheye" 499 "Lcj Capteurs" 502 "Attwood Marine" 503 "Naviop S.R.L." 504 "Vesper Marine" 510 "Marinesoft" 513 "Simarine" 517 "NoLand Engineering" 518 "Transas USA" 529 "National Instruments Korea" 530 "National Marine Electronics Association" 532 "Onwa Marine" 540 "Webasto" 571 "Marinecraft (South Korea)" 573 "McMurdo Group aka Orolia" 578 "Advansea" 579 "KVH" 580 "San Jose Technology" 583 "Yacht Control" 586 "Suzuki Motor" 591 "US Coast Guard" 595 "Ship Module aka Customware" 600 "Aquatic AV" 605 "Aventics" 606 "Intellian" 612 "SamwonIT" 614 "Arlt Tecnologies" 637 "Bavaria Yachts" 641 "Diverse Yacht Services" 644 "Wema U.S.A dba KUS" 658 "Shenzhen Jiuzhou Himunication" 688 "Rockford" 699 "Harman International" 704 "JL Audio" 708 "Lars Thrane" 715 "Autonnic" 717 "Yacht Devices" 734 "REAP Systems" 735 "AEM Performance Electronics" 739 "LxNav" 741 "Littelfuse, Inc (formerly Carling Technologies)" 743 "DaeMyung" 744 "Woosung" 748 "ISOTTA IFRA srl" 773 "Clarion US" 776 "HMI Systems" 777 "Ocean Signal" 778 "Seakeeper" 781 "Poly Planar" 785 "Fischer Panda DE" 795 "Broyda Industries" 796 "Canadian Automotive" 797 "Tides Marine" 798 "Lumishore" 799 "Still Water Designs and Audio" 802 "BJ Technologies (Beneteau)" 803 "Gill Sensors" 811 "Blue Water Desalination" 815 "FLIR" 824 "Undheim Systems" 826 "Lewmar" 838 "TeamSurv" 844 "Fell Marine" 847 "Oceanvolt" 862 "Prospec" 868 "Data Panel" 890 "L3 Technologies" 894 "Rhodan Marine Systems" 896 "Nexfour Solutions" 905 "ASA Electronics" 909 "Marines Co (South Korea)" 911 "Nautic-on" 917 "Sentinel" 929 "JL Marine Systems" 930 "Ecotronix" 944 "Zontisa Marine" 951 "EXOR International" 962 "Timbolier Industries" 963 "TJC Micro" 968 "Cox Powertrain" 969 "Blue Seas" 981 "Kobelt Manufacturing" 992 "Blue Ocean IOT" 997 "Xenta Systems" 999 "Signal K" 1004 "Ultraflex" 1008 "Lintest SmartBoat" 1011 "Soundmax" 1020 "Team Italia Marine (Onyx Marine Automation s.r.l)" 1021 "Entratech" 1022 "ITC" 1029 "The Marine Guardian" 1047 "Sonic" 1051 "ProNav" 1053 "Vetus Maxwell INC." 1056 "Lithium Pros" 1059 "Boatrax" 1062 "Marol Co ltd" 1065 "CALYPSO Instruments" 1066 "Spot Zero Water" 1069 "Lithionics Battery" 1070 "Quick-teck Electronics" 1075 "Uniden America" 1083 "Nauticoncept" 1084 "Shadow-Caster LED lighting" 1085 "Wet Sounds" 1088 "E-T-A Circuit Breakers" 1092 "Scheiber" 1100 "Smart Yachts International Limited" 1109 "Dockmate" 1114 "Bobs Machine" 1118 "L3Harris ASV" 1119 "Balmar" 1120 "Elettromedia" 1127 "Electromaax" 1140 "Across Oceans Systems" 1145 "Kiwi Yachting" 1150 "BSB Artificial Intelligence" 1151 "Orca Technologies" 1154 "TBS Electronics" 1158 "Technoton Electroics" 1160 "MG Energy Systems" 1169 "Sea Machine Robotics" 1171 "Vista Manufacturing" 1183 "Zipwake" 1186 "Sailmon" 1192 "Airmoniq Pro Kft" 1194 "Sierra Marine" 1200 "Xinuo Information Technology (Xiamen)" 1218 "Septentrio" 1233 "NKE Marine Electronics" 1238 "SuperTrack Aps" 1239 "Honda Electronics" 1245 "Raritan Engineering" 1249 "Integrated Power Solutions AG" 1260 "Interactive Technologies" 1283 "LTG-Tech" 1299 "Energy Solutions (UK)" 1300 "WATT Fuel Cell" 1302 "Pro Mainer" 1305 "Dragonfly Energy" 1306 "Koden Electronics" 1311 "Humphree" 1316 "Hinkley Yachts" 1317 "Global Marine Management GmbH (GMM)" 1320 "Triskel Marine" 1330 "Warwick Control Technologies" 1331 "Dolphin Charger" 1337 "Barnacle Systems" 1348 "Radian IoT" 1353 "Ocean LED Marine" 1359 "BluNav" 1361 "OVA (Nantong Saiyang Electronics Co., Ltd)" 1368 "RAD Propulsion" 1369 "Electric Yacht" 1372 "Elco Motor Yachts" 1384 "Tecnoseal Foundry S.r.l" 1385 "Pro Charging Systems" 1389 "EVEX" 1398 "Gobius Sensor Technology" 1403 "Arco Marine" 1408 "Lenco Marine" 1413 "Naocontrol" 1417 "Revatek" 1438 "Aeolionics" 1439 "PredictWind" 1440 "Egis Mobile Electric" 1445 "Starboard Yacht Group" 1446 "Roswell Marine" 1451 "ePropulsion (Guangdong ePropulsion Technology Ltd.)" 1452 "Micro-Air" 1453 "Vital Battery" 1458 "Ride Controller" 1460 "Tocaro Blue" 1461 "Vanquish Yachts" 1471 "FT Technologies" 1478 "Alps Alpine" 1481 "E-Force Marine" 1482 "CMC Marine" 1483 "Nanjing Sandemarine Information Technology" 1850 "Teleflex Marine (SeaStar Solutions)" 1851 "Raymarine" 1852 "Navionics" 1853 "Japan Radio" 1854 "Northstar Technologies" 1855 "Furuno" 1856 "Trimble" 1857 "Simrad" 1858 "Litton" 1859 "Kvasar" 1860 "MMP" 1861 "Vector Cantech" 1862 "Yamaha Marine" 1863 "Faria Instruments" ;
VAL_ 2566861824 Industry_Code 0 "Global" 1 "Highway" 2 "Agriculture" 3 "Construction" 4 "Marine Industry" 5 "Industrial" ;
VAL_ 2365537280 Manufacturer_Code 69 "ARKS Enterprises" 78 "FW Murphy/Enovation Controls" 80 "Twin Disc" 85 "Kohler Power Systems" 88 "Hemisphere GPS" 135 "Airmar" 137 "Maretron" 140 "Lowrance" 144 "Mercury Marine" 147 "Nautibus Electronic" 148 "Blue Water Data" 154 "Westerbeke" 157 "ISSPRO" 161 "Offshore Systems (UK)" 163 "Evinrude/BRP" 165 "CPAC Systems" 168 "Xantrex Technology" 169 "Marlin Technologies" 172 "Yanmar Marine" 174 "Volvo Penta" 176 "Carling Technologies Inc. (Moritz Aerospace)" 185 "Beede Instruments" 192 "Floscan Instrument" 193 "Nobeltec" 198 "Mystic Valley Communications" 199 "Actia" 201 "Disenos Y Technologia" 211 "Digital Switching Systems" 215 "Xintex/Atena" 224 "EMMI NETWORK" 228 "ZF" 229 "Garmin" 233 "Yacht Monitoring Solutions" 235 "Sailormade Marine Telemetry/Tetra Technology" 243 "Eride" 257 "Honda Motor" 272 "Groco" 273 "Actisense" 274 "Amphenol LTW Technology" 275 "Navico" 283 "Hamilton Jet" 285 "Sea Recovery" 286 "Coelmo SRL Italy" 295 "BEP Marine" 304 "Empir Bus" 305 "NovAtel" 306 "Sleipner Motor" 307 "MBW Technologies" 315 "ICOM" 328 "Qwerty" 329 "Dief" 341 "Boening Automationstechnologie" 345 "Korean Maritime University" 351 "Thrane and Thrane" 355 "Mastervolt" 356 "Fischer Panda Generators" 358 "Victron Energy" 370 "Rolls Royce Marine" 373 "Electronic Design" 374 "Northern Lights" 378 "Glendinning" 381 "B & G" 384 "Rose Point Navigation Systems" 385 "Johnson Outdoors Marine Electronics Inc Geonav" 394 "Capi 2" 396 "Beyond Measure" 400 "Livorsi Marine" 404 "ComNav" 409 "Chetco" 419 "Fusion Electronics" 421 "Standard Horizon" 422 "True Heading" 426 "Egersund Marine Electronics" 427 "em-trak Marine Electronics" 431 "Tohatsu Co, JP" 437 "Digital Yacht" 438 "Comar Systems Limited" 440 "Cummins" 443 "VDO (aka Continental-Corporation)" 451 "Parker Hannifin aka Village Marine Tech" 459 "Alltek Marine Electronics" 460 "SAN GIORGIO S.E.I.N" 466 "Veethree Electronics & Marine" 470 "SI-TEX Marine Electronics" 471 "Sea Cross Marine" 475 "GME aka Standard Communications" 476 "Humminbird Marine Electronics" 478 "Ocean Sat" 481 "Chetco Digital Instruments" 493 "Watcheye" 499 "Lcj Capteurs" 502 "Attwood Marine" 503 "Naviop S.R.L." 504 "Vesper Marine" 510 "Marinesoft" 513 "Simarine" 517 "NoLand Engineering" 518 "Transas USA" 529 "National Instruments Korea" 530 "National Marine Electronics Association" 532 "Onwa Marine" 540 "Webasto" 571 "Marinecraft (South Korea)" 573 "McMurdo Group aka Orolia" 578 "Advansea" 579 "KVH" 580 "San Jose Technology" 583 "Yacht Control" 586 "Suzuki Motor" 591 "US Coast Guard" 595 "Ship Module aka Customware" 600 "Aquatic AV" 605 "Aventics" 606 "Intellian" 612 "SamwonIT" 614 "Arlt Tecnologies" 637 "Bavaria Yachts" 641 "Diverse Yacht Services" 644 "Wema U.S.A dba KUS" 658 "Shenzhen Jiuzhou Himunication" 688 "Rockford" 699 "Harman International" 704 "JL Audio" 708 "Lars Thrane" 715 "Autonnic" 717 "Yacht Devices" 734 "REAP Systems" 735 "AEM Performance Electronics" 739 "LxNav" 741 "Littelfuse, Inc (formerly Carling Technologies)" 743 "DaeMyung" 744 "Woosung" 748 "ISOTTA IFRA srl" 773 "Clarion US" 776 "HMI Systems" 777 "Ocean Signal" 778 "Seakeeper" 781 "Poly Planar" 785 "Fischer Panda DE" 795 "Broyda Industries" 796 "Canadian Automotive" 797 "Tides Marine" 798 "Lumishore" 799 "Still Water Designs and Audio" 802 "BJ Technologies (Beneteau)" 803 "Gill Sensors" 811 "Blue Water Desalination" 815 "FLIR" 824 "Undheim Systems" 826 "Lewmar" 838 "TeamSurv" 844 "Fell Marine" 847 "Oceanvolt" 862 "Prospec" 868 "Data Panel" 890 "L3 Technologies" 894 "Rhodan Marine Systems" 896 "Nexfour Solutions" 905 "ASA Electronics" 909 "Marines Co (South Korea)" 911 "Nautic-on" 917 "Sentinel" 929 "JL Marine Systems" 930 "Ecotronix" 944 "Zontisa Marine" 951 "EXOR International" 962 "Timbolier Industries" 963 "TJC Micro" 968 "Cox Powertrain" 969 "Blue Seas" 981 "Kobelt Manufacturing" 992 "Blue Ocean IOT" 997 "Xenta Systems" 999 "Signal K" 1004 "Ultraflex" 1008 "Lintest SmartBoat" 1011 "Soundmax" 1020 "Team Italia Marine (Onyx Marine Automation s.r.l)" 1021 "Entratech" 1022 "ITC" 1029 "The Marine Guardian" 1047 "Sonic" 1051 "ProNav" 1053 "Vetus Maxwell INC." 1056 "Lithium Pros" 1059 "Boatrax" 1062 "Marol Co ltd" 1065 "CALYPSO Instruments" 1066 "Spot Zero Water" 1069 "Lithionics Battery" 1070 "Quick-teck Electronics" 1075 "Uniden America" 1083 "Nauticoncept" 1084 "Shadow-Caster LED lighting" 1085 "Wet Sounds" 1088 "E-T-A Circuit Breakers" 1092 "Scheiber" 1100 "Smart Yachts International Limited" 1109 "Dockmate" 1114 "Bobs Machine" 1118 "L3Harris ASV" 1119 "Balmar" 1120 "Elettromedia" 1127 "Electromaax" 1140 "Across Oceans Systems" 1145 "Kiwi Yachting" 1150 "BSB Artificial Intelligence" 1151 "Orca Technologies" 1154 "TBS Electronics" 1158 "Technoton Electroics" 1160 "MG Energy Systems" 1169 "Sea Machine Robotics" 1171 "Vista Manufacturing" 1183 "Zipwake" 1186 "Sailmon" 1192 "Airmoniq Pro Kft" 1194 "Sierra Marine" 1200 "Xinuo Information Technology (Xiamen)" 1218 "Septentrio" 1233 "NKE Marine Electronics" 1238 "SuperTrack Aps" 1239 "Honda Electronics" 1245 "Raritan Engineering" 1249 "Integrated Power Solutions AG" 1260 "Interactive Technologies" 1283 "LTG-Tech" 1299 "Energy Solutions (UK)" 1300 "WATT Fuel Cell" 1302 "Pro Mainer" 1305 "Dragonfly Energy" 1306 "Koden Electronics" 1311 "Humphree" 1316 "Hinkley Yachts" 1317 "Global Marine Management GmbH (GMM)" 1320 "Triskel Marine" 1330 "Warwick Control Technologies" 1331 "Dolphin Charger" 1337 "Barnacle Systems" 1348 "Radian IoT" 1353 "Ocean LED Marine" 1359 "BluNav" 1361 "OVA (Nantong Saiyang Electronics Co., Ltd)" 1368 "RAD Propulsion" 1369 "Electric Yacht" 1372 "Elco Motor Yachts" 1384 "Tecnoseal Foundry S.r.l" 1385 "Pro Charging Systems" 1389 "EVEX" 1398 "Gobius Sensor Technology" 1403 "Arco Marine" 1408 "Lenco Marine" 1413 "Naocontrol" 1417 "Revatek" 1438 "Aeolionics" 1439 "PredictWind" 1440 "Egis Mobile Electric" 1445 "Starboard Yacht Group" 1446 "Roswell Marine" 1451 "ePropulsion (Guangdong ePropulsion Technology Ltd.)" 1452 "Micro-Air" 1453 "Vital Battery" 1458 "Ride Controller" 1460 "Tocaro Blue" 1461 "Vanquish Yachts" 1471 "FT Technologies" 1478 "Alps Alpine" 1481 "E-Force Marine" 1482 "CMC Marine" 1483 "Nanjing Sandemarine Information Technology" 1850 "Teleflex Marine (SeaStar Solutions)" 1851 "Raymarine" 1852 "Navionics" 1853 "Japan Radio" 1854 "Northstar Technologies" 1855 "Furuno" 1856 "Trimble" 1857 "Simrad" 1858 "Litton" 1859 "Kvasar" 1860 "MMP" 1861 "Vector Cantech" 1862 "Yamaha Marine" 1863 "Faria Instruments" ;
VAL_ 2365537280 Industry_Code 0 "Global" 1 "Highway" 2 "Agriculture" 3 "Construction" 4 "Marine Industry" 5 "Industrial" ;
VAL_ 2365537280 Mode_Class 0 "Standby" 16 "Engaged" ;
VAL_ 2365537280 Mode 0 "Standby" 1 "Heading" 3 "Mode 4" 4 "Wind" 5 "Non-Follow-Up" 6 "Navigation" ;
VAL_ 2566864128 Manufacturer_Code 69 "ARKS Enterprises" 78 "FW Murphy/Enovation Controls" 80 "Twin Disc" 85 "Kohler Power Systems" 88 "Hemisphere GPS" 135 "Airmar" 137 "Maretron" 140 "Lowrance" 144 "Mercury Marine" 147 "Nautibus Electronic" 148 "Blue Water Data" 154 "Westerbeke" 157 "ISSPRO" 161 "Offshore Systems (UK)" 163 "Evinrude/BRP" 165 "CPAC Systems" 168 "Xantrex Technology" 169 "Marlin Technologies" 172 "Yanmar Marine" 174 "Volvo Penta" 176 "Carling Technologies Inc. (Moritz Aerospace)" 185 "Beede Instruments" 192 "Floscan Instrument" 193 "Nobeltec" 198 "Mystic Valley Communications" 199 "Actia" 201 "Disenos Y Technologia" 211 "Digital Switching Systems" 215 "Xintex/Atena" 224 "EMMI NETWORK" 228 "ZF" 229 "Garmin" 233 "Yacht Monitoring Solutions" 235 "Sailormade Marine Telemetry/Tetra Technology" 243 "Eride" 257 "Honda Motor" 272 "Groco" 273 "Actisense" 274 "Amphenol LTW Technology" 275 "Navico" 283 "Hamilton Jet" 285 "Sea Recovery" 286 "Coelmo SRL Italy" 295 "BEP Marine" 304 "Empir Bus" 305 "NovAtel" 306 "Sleipner Motor" 307 "MBW Technologies" 315 "ICOM" 328 "Qwerty" 329 "Dief" 341 "Boening Automationstechnologie" 345 "Korean Maritime University" 351 "Thrane and Thrane" 355 "Mastervolt" 356 "Fischer Panda Generators" 358 "Victron Energy" 370 "Rolls Royce Marine" 373 "Electronic Design" 374 "Northern Lights" 378 "Glendinning" 381 "B & G" 384 "Rose Point Navigation Systems" 385 "Johnson Outdoors Marine Electronics Inc Geonav" 394 "Capi 2" 396 "Beyond Measure" 400 "Livorsi Marine" 404 "ComNav" 409 "Chetco" 419 "Fusion Electronics" 421 "Standard Horizon" 422 "True Heading" 426 "Egersund Marine Electronics" 427 "em-trak Marine Electronics" 431 "Tohatsu Co, JP" 437 "Digital Yacht" 438 "Comar Systems Limited" 440 "Cummins" 443 "VDO (aka Continental-Corporation)" 451 "Parker Hannifin aka Village Marine Tech" 459 "Alltek Marine Electronics" 460 "SAN GIORGIO S.E.I.N" 466 "Veethree Electronics & Marine" 470 "SI-TEX Marine Electronics" 471 "Sea Cross Marine" 475 "GME aka Standard Communications" 476 "Humminbird Marine Electronics" 478 "Ocean Sat" 481 "Chetco Digital Instruments" 493 "Watcheye" 499 "Lcj Capteurs" 502 "Attwood Marine" 503 "Naviop S.R.L." 504 "Vesper Marine" 510 "Marinesoft" 513 "Simarine" 517 "NoLand Engineering" 518 "Transas USA" 529 "National Instruments Korea" 530 "National Marine Electronics Association" 532 "Onwa Marine" 540 "Webasto" 571 "Marinecraft (South Korea)" 573 "McMurdo Group aka Orolia" 578 "Advansea" 579 "KVH" 580 "San Jose Technology" 583 "Yacht Control" 586 "Suzuki Motor" 591 "US Coast Guard" 595 "Ship Module aka Customware" 600 "Aquatic AV" 605 "Aventics" 606 "Intellian" 612 "SamwonIT" 614 "Arlt Tecnologies" 637 "Bavaria Yachts" 641 "Diverse Yacht Services" 644 "Wema U.S.A dba KUS" 658 "Shenzhen Jiuzhou Himunication" 688 "Rockford" 699 "Harman International" 704 "JL Audio" 708 "Lars Thrane" 715 "Autonnic" 717 "Yacht Devices" 734 "REAP Systems" 735 "AEM Performance Electronics" 739 "LxNav" 741 "Littelfuse, Inc (formerly Carling Technologies)" 743 "DaeMyung" 744 "Woosung" 748 "ISOTTA IFRA srl" 773 "Clarion US" 776 "HMI Systems" 777 "Ocean Signal" 778 "Seakeeper" 781 "Poly Planar" 785 "Fischer Panda DE" 795 "Broyda Industries" 796 "Canadian Automotive" 797 "Tides Marine" 798 "Lumishore" 799 "Still Water Designs and Audio" 802 "BJ Technologies (Beneteau)" 803 "Gill Sensors" 811 "Blue Water Desalination" 815 "FLIR" 824 "Undheim Systems" 826 "Lewmar" 838 "TeamSurv" 844 "Fell Marine" 847 "Oceanvolt" 862 "Prospec" 868 "Data Panel" 890 "L3 Technologies" 894 "Rhodan Marine Systems" 896 "Nexfour Solutions" 905 "ASA Electronics" 909 "Marines Co (South Korea)" 911 "Nautic-on" 917 "Sentinel" 929 "JL Marine Systems" 930 "Ecotronix" 944 "Zontisa Marine" 951 "EXOR International" 962 "Timbolier Industries" 963 "TJC Micro" 968 "Cox Powertrain" 969 "Blue Seas" 981 "Kobelt Manufacturing" 992 "Blue Ocean IOT" 997 "Xenta Systems" 999 "Signal K" 1004 "Ultraflex" 1008 "Lintest SmartBoat" 1011 "Soundmax" 1020 "Team Italia Marine (Onyx Marine Automation s.r.l)" 1021 "Entratech" 1022 "ITC" 1029 "The Marine Guardian" 1047 "Sonic" 1051 "ProNav" 1053 "Vetus Maxwell INC." 1056 "Lithium Pros" 1059 "Boatrax" 1062 "Marol Co ltd" 1065 "CALYPSO Instruments" 1066 "Spot Zero Water" 1069 "Lithionics Battery" 1070 "Quick-teck Electronics" 1075 "Uniden America" 1083 "Nauticoncept" 1084 "Shadow-Caster LED lighting" 1085 "Wet Sounds" 1088 "E-T-A Circuit Breakers" 1092 "Scheiber" 1100 "Smart Yachts International Limited" 1109 "Dockmate" 1114 "Bobs Machine" 1118 "L3Harris ASV" 1119 "Balmar" 1120 "Elettromedia" 1127 "Electromaax" 1140 "Across Oceans Systems" 1145 "Kiwi Yachting" 1150 "BSB Artificial Intelligence" 1151 "Orca Technologies" 1154 "TBS Electronics" 1158 "Technoton Electroics" 1160 "MG Energy Systems" 1169 "Sea Machine Robotics" 1171 "Vista Manufacturing" 1183 "Zipwake" 1186 "Sailmon" 1192 "Airmoniq Pro Kft" 1194 "Sierra Marine" 1200 "Xinuo Information Technology (Xiamen)" 1218 "Septentrio" 1233 "NKE Marine Electronics" 1238 "SuperTrack Aps" 1239 "Honda Electronics" 1245 "Raritan Engineering" 1249 "Integrated Power Solutions AG" 1260 "Interactive Technologies" 1283 "LTG-Tech" 1299 "Energy Solutions (UK)" 1300 "WATT Fuel Cell" 1302 "Pro Mainer" 1305 "Dragonfly Energy" 1306 "Koden Electronics" 1311 "Humphree" 1316 "Hinkley Yachts" 1317 "Global Marine Management GmbH (GMM)" 1320 "Triskel Marine" 1330 "Warwick Control Technologies" 1331 "Dolphin Charger" 1337 "Barnacle Systems" 1348 "Radian IoT" 1353 "Ocean LED Marine" 1359 "BluNav" 1361 "OVA (Nantong Saiyang Electronics Co., Ltd)" 1368 "RAD Propulsion" 1369 "Electric Yacht" 1372 "Elco Motor Yachts" 1384 "Tecnoseal Foundry S.r.l" 1385 "Pro Charging Systems" 1389 "EVEX" 1398 "Gobius Sensor Technology" 1403 "Arco Marine" 1408 "Lenco Marine" 1413 "Naocontrol" 1417 "Revatek" 1438 "Aeolionics" 1439 "PredictWind" 1440 "Egis Mobile Electric" 1445 "Starboard Yacht Group" 1446 "Roswell Marine" 1451 "ePropulsion (Guangdong ePropulsion Technology Ltd.)" 1452 "Micro-Air" 1453 "Vital Battery" 1458 "Ride Controller" 1460 "Tocaro Blue" 1461 "Vanquish Yachts" 1471 "FT Technologies" 1478 "Alps Alpine" 1481 "E-Force Marine" 1482 "CMC Marine" 1483 "Nanjing Sandemarine Information Technology" 1850 "Teleflex Marine (SeaStar Solutions)" 1851 "Raymarine" 1852 "Navionics" 1853 "Japan Radio" 1854 "Northstar Technologies" 1855 "Furuno" 1856 "Trimble" 1857 "Simrad" 1858 "Litton" 1859 "Kvasar" 1860 "MMP" 1861 "Vector Cantech" 1862 "Yamaha Marine" 1863 "Faria Instruments" ;
VAL_ 2566864128 Industry_Code 0 "Global" 1 "Highway" 2 "Agriculture" 3 "Construction" 4 "Marine Industry" 5 "Industrial" ;
VAL_ 2566864128 Mode 2 "Heading" 3 "Wind" 10 "Nav" 11 "No Drift" ;
VAL_ 2566864896 Manufacturer_Code 69 "ARKS Enterprises" 78 "FW Murphy/Enovation Controls" 80 "Twin Disc" 85 "Kohler Power Systems" 88 "Hemisphere GPS" 135 "Airmar" 137 "Maretron" 140 "Lowrance" 144 "Mercury Marine" 147 "Nautibus Electronic" 148 "Blue Water Data" 154 "Westerbeke" 157 "ISSPRO" 161 "Offshore Systems (UK)" 163 "Evinrude/BRP" 165 "CPAC Systems" 168 "Xantrex Technology" 169 "Marlin Technologies" 172 "Yanmar Marine" 174 "Volvo Penta" 176 "Carling Technologies Inc. (Moritz Aerospace)" 185 "Beede Instruments" 192 "Floscan Instrument" 193 "Nobeltec" 198 "Mystic Valley Communications" 199 "Actia" 201 "Disenos Y Technologia" 211 "Digital Switching Systems" 215 "Xintex/Atena" 224 "EMMI NETWORK" 228 "ZF" 229 "Garmin" 233 "Yacht Monitoring Solutions" 235 "Sailormade Marine Telemetry/Tetra Technology" 243 "Eride" 257 "Honda Motor" 272 "Groco" 273 "Actisense" 274 "Amphenol LTW Technology" 275 "Navico" 283 "Hamilton Jet" 285 "Sea Recovery" 286 "Coelmo SRL Italy" 295 "BEP Marine" 304 "Empir Bus" 305 "NovAtel" 306 "Sleipner Motor" 307 "MBW Technologies" 315 "ICOM" 328 "Qwerty" 329 "Dief" 341 "Boening Automationstechnologie" 345 "Korean Maritime University" 351 "Thrane and Thrane" 355 "Mastervolt" 356 "Fischer Panda Generators" 358 "Victron Energy" 370 "Rolls Royce Marine" 373 "Electronic Design" 374 "Northern Lights" 378 "Glendinning" 381 "B & G" 384 "Rose Point Navigation Systems" 385 "Johnson Outdoors Marine Electronics Inc Geonav" 394 "Capi 2" 396 "Beyond Measure" 400 "Livorsi Marine" 404 "ComNav" 409 "Chetco" 419 "Fusion Electronics" 421 "Standard Horizon" 422 "True Heading" 426 "Egersund Marine Electronics" 427 "em-trak Marine Electronics" 431 "Tohatsu Co, JP" 437 "Digital Yacht" 438 "Comar Systems Limited" 440 "Cummins" 443 "VDO (aka Continental-Corporation)" 451 "Parker Hannifin aka Village Marine Tech" 459 "Alltek Marine Electronics" 460 "SAN GIORGIO S.E.I.N" 466 "Veethree Electronics & Marine" 470 "SI-TEX Marine Electronics" 471 "Sea Cross Marine" 475 "GME aka Standard Communications" 476 "Humminbird Marine Electronics" 478 "Ocean Sat" 481 "Chetco Digital Instruments" 493 "Watcheye" 499 "Lcj Capteurs" 502 "Attwood Marine" 503 "Naviop S.R.L." 504 "Vesper Marine" 510 "Marinesoft" 513 "Simarine" 517 "NoLand Engineering" 518 "Transas USA" 529 "National Instruments Korea" 530 "National Marine Electronics Association" 532 "Onwa Marine" 540 "Webasto" 571 "Marinecraft (South Korea)" 573 "McMurdo Group aka Orolia" 578 "Advansea" 579 "KVH" 580 "San Jose Technology" 583 "Yacht Control" 586 "Suzuki Motor" 591 "US Coast Guard" 595 "Ship Module aka Customware" 600 "Aquatic AV" 605 "Aventics" 606 "Intellian" 612 "SamwonIT" 614 "Arlt Tecnologies" 637 "Bavaria Yachts" 641 "Diverse Yacht Services" 644 "Wema U.S.A dba KUS" 658 "Shenzhen Jiuzhou Himunication" 688 "Rockford" 699 "Harman International" 704 "JL Audio" 708 "Lars Thrane" 715 "Autonnic" 717 "Yacht Devices" 734 "REAP Systems" 735 "AEM Performance Electronics" 739 "LxNav" 741 "Littelfuse, Inc (formerly Carling Technologies)" 743 "DaeMyung" 744 "Woosung" 748 "ISOTTA IFRA srl" 773 "Clarion US" 776 "HMI Systems" 777 "Ocean Signal" 778 "Seakeeper" 781 "Poly Planar" 785 "Fischer Panda DE" 795 "Broyda Industries" 796 "Canadian Automotive" 797 "Tides Marine" 798 "Lumishore" 799 "Still Water Designs and Audio" 802 "BJ Technologies (Beneteau)" 803 "Gill Sensors" 811 "Blue Water Desalination" 815 "FLIR" 824 "Undheim Systems" 826 "Lewmar" 838 "TeamSurv" 844 "Fell Marine" 847 "Oceanvolt" 862 "Prospec" 868 "Data Panel" 890 "L3 Technologies" 894 "Rhodan Marine Systems" 896 "Nexfour Solutions" 905 "ASA Electronics" 909 "Marines Co (South Korea)" 911 "Nautic-on" 917 "Sentinel" 929 "JL Marine Systems" 930 "Ecotronix" 944 "Zontisa Marine" 951 "EXOR International" 962 "Timbolier Industries" 963 "TJC Micro" 968 "Cox Powertrain" 969 "Blue Seas" 981 "Kobelt Manufacturing" 992 "Blue Ocean IOT" 997 "Xenta Systems" 999 "Signal K" 1004 "Ultraflex" 1008 "Lintest SmartBoat" 1011 "Soundmax" 1020 "Team Italia Marine (Onyx Marine Automation s.r.l)" 1021 "Entratech" 1022 "ITC" 1029 "The Marine Guardian" 1047 "Sonic" 1051 "ProNav" 1053 "Vetus Maxwell INC." 1056 "Lithium Pros" 1059 "Boatrax" 1062 "Marol Co ltd" 1065 "CALYPSO Instruments" 1066 "Spot Zero Water" 1069 "Lithionics Battery" 1070 "Quick-teck Electronics" 1075 "Uniden America" 1083 "Nauticoncept" 1084 "Shadow-Caster LED lighting" 1085 "Wet Sounds" 1088 "E-T-A Circuit Breakers" 1092 "Scheiber" 1100 "Smart Yachts International Limited" 1109 "Dockmate" 1114 "Bobs Machine" 1118 "L3Harris ASV" 1119 "Balmar" 1120 "Elettromedia" 1127 "Electromaax" 1140 "Across Oceans Systems" 1145 "Kiwi Yachting" 1150 "BSB Artificial Intelligence" 1151 "Orca Technologies" 1154 "TBS Electronics" 1158 "Technoton Electroics" 1160 "MG Energy Systems" 1169 "Sea Machine Robotics" 1171 "Vista Manufacturing" 1183 "Zipwake" 1186 "Sailmon" 1192 "Airmoniq Pro Kft" 1194 "Sierra Marine" 1200 "Xinuo Information Technology (Xiamen)" 1218 "Septentrio" 1233 "NKE Marine Electronics" 1238 "SuperTrack Aps" 1239 "Honda Electronics" 1245 "Raritan Engineering" 1249 "Integrated Power Solutions AG" 1260 "Interactive Technologies" 1283 "LTG-Tech" 1299 "Energy Solutions (UK)" 1300 "WATT Fuel Cell" 1302 "Pro Mainer" 1305 "Dragonfly Energy" 1306 "Koden Electronics" 1311 "Humphree" 1316 "Hinkley Yachts" 1317 "Global Marine Management GmbH (GMM)" 1320 "Triskel Marine" 1330 "Warwick Control Technologies" 1331 "Dolphin Charger" 1337 "Barnacle Systems" 1348 "Radian IoT" 1353 "Ocean LED Marine" 1359 "BluNav" 1361 "OVA (Nantong Saiyang Electronics Co., Ltd)" 1368 "RAD Propulsion" 1369 "Electric Yacht" 1372 "Elco Motor Yachts" 1384 "Tecnoseal Foundry S.r.l" 1385 "Pro Charging Systems" 1389 "EVEX" 1398 "Gobius Sensor Technology" 1403 "Arco Marine" 1408 "Lenco Marine" 1413 "Naocontrol" 1417 "Revatek" 1438 "Aeolionics" 1439 "PredictWind" 1440 "Egis Mobile Electric" 1445 "Starboard Yacht Group" 1446 "Roswell Marine" 1451 "ePropulsion (Guangdong ePropulsion Technology Ltd.)" 1452 "Micro-Air" 1453 "Vital Battery" 1458 "Ride Controller" 1460 "Tocaro Blue" 1461 "Vanquish Yachts" 1471 "FT Technologies" 1478 "Alps Alpine" 1481 "E-Force Marine" 1482 "CMC Marine" 1483 "Nanjing Sandemarine Information Technology" 1850 "Teleflex Marine (SeaStar Solutions)" 1851 "Raymarine" 1852 "Navionics" 1853 "Japan Radio" 1854 "Northstar Technologies" 1855 "Furuno" 1856 "Trimble" 1857 "Simrad" 1858 "Litton" 1859 "Kvasar" 1860 "MMP" 1861 "Vector Cantech" 1862 "Yamaha Marine" 1863 "Faria Instruments" ;
VAL_ 2566864896 Industry_Code 0 "Global" 1 "Highway" 2 "Agriculture" 3 "Construction" 4 "Marine Industry" 5 "Industrial" ;
VAL_ 2566865152 Manufacturer_Code 69 "ARKS Enterprises" 78 "FW Murphy/Enovation Controls" 80 "Twin Disc" 85 "Kohler Power Systems" 88 "Hemisphere GPS" 135 "Airmar" 137 "Maretron" 140 "Lowrance" 144 "Mercury Marine" 147 "Nautibus Electronic" 148 "Blue Water Data" 154 "Westerbeke" 157 "ISSPRO" 161 "Offshore Systems (UK)" 163 "Evinrude/BRP" 165 "CPAC Systems" 168 "Xantrex Technology" 169 "Marlin Technologies" 172 "Yanmar Marine" 174 "Volvo Penta" 176 "Carling Technologies Inc. (Moritz Aerospace)" 185 "Beede Instruments" 192 "Floscan Instrument" 193 "Nobeltec" 198 "Mystic Valley Communications" 199 "Actia" 201 "Disenos Y Technologia" 211 "Digital Switching Systems" 215 "Xintex/Atena" 224 "EMMI NETWORK" 228 "ZF" 229 "Garmin" 233 "Yacht Monitoring Solutions" 235 "Sailormade Marine Telemetry/Tetra Technology" 243 "Eride" 257 "Honda Motor" 272 "Groco" 273 "Actisense" 274 "Amphenol LTW Technology" 275 "Navico" 283 "Hamilton Jet" 285 "Sea Recovery" 286 "Coelmo SRL Italy" 295 "BEP Marine" 304 "Empir Bus" 305 "NovAtel" 306 "Sleipner Motor" 307 "MBW Technologies" 315 "ICOM" 328 "Qwerty" 329 "Dief" 341 "Boening Automationstechnologie" 345 "Korean Maritime University" 351 "Thrane and Thrane" 355 "Mastervolt" 356 "Fischer Panda Generators" 358 "Victron Energy" 370 "Rolls Royce Marine" 373 "Electronic Design" 374 "Northern Lights" 378 "Glendinning" 381 "B & G" 384 "Rose Point Navigation Systems" 385 "Johnson Outdoors Marine Electronics Inc Geonav" 394 "Capi 2" 396 "Beyond Measure" 400 "Livorsi Marine" 404 "ComNav" 409 "Chetco" 419 "Fusion Electronics" 421 "Standard Horizon" 422 "True Heading" 426 "Egersund Marine Electronics" 427 "em-trak Marine Electronics" 431 "Tohatsu Co, JP" 437 "Digital Yacht" 438 "Comar Systems Limited" 440 "Cummins" 443 "VDO (aka Continental-Corporation)" 451 "Parker Hannifin aka Village Marine Tech" 459 "Alltek Marine Electronics" 460 "SAN GIORGIO S.E.I.N" 466 "Veethree Electronics & Marine" 470 "SI-TEX Marine Electronics" 471 "Sea Cross Marine" 475 "GME aka Standard Communications" 476 "Humminbird Marine Electronics" 478 "Ocean Sat" 481 "Chetco Digital Instruments" 493 "Watcheye" 499 "Lcj Capteurs" 502 "Attwood Marine" 503 "Naviop S.R.L." 504 "Vesper Marine" 510 "Marinesoft" 513 "Simarine" 517 "NoLand Engineering" 518 "Transas USA" 529 "National Instruments Korea" 530 "National Marine Electronics Association" 532 "Onwa Marine" 540 "Webasto" 571 "Marinecraft (South Korea)" 573 "McMurdo Group aka Orolia" 578 "Advansea" 579 "KVH" 580 "San Jose Technology" 583 "Yacht Control" 586 "Suzuki Motor" 591 "US Coast Guard" 595 "Ship Module aka Customware" 600 "Aquatic AV" 605 "Aventics" 606 "Intellian" 612 "SamwonIT" 614 "Arlt Tecnologies" 637 "Bavaria Yachts" 641 "Diverse Yacht Services" 644 "Wema U.S.A dba KUS" 658 "Shenzhen Jiuzhou Himunication" 688 "Rockford" 699 "Harman International" 704 "JL Audio" 708 "Lars Thrane" 715 "Autonnic" 717 "Yacht Devices" 734 "REAP Systems" 735 "AEM Performance Electronics" 739 "LxNav" 741 "Littelfuse, Inc (formerly Carling Technologies)" 743 "DaeMyung" 744 "Woosung" 748 "ISOTTA IFRA srl" 773 "Clarion US" 776 "HMI Systems" 777 "Ocean Signal" 778 "Seakeeper" 781 "Poly Planar" 785 "Fischer Panda DE" 795 "Broyda Industries" 796 "Canadian Automotive" 797 "Tides Marine" 798 "Lumishore" 799 "Still Water Designs and Audio" 802 "BJ Technologies (Beneteau)" 803 "Gill Sensors" 811 "Blue Water Desalination" 815 "FLIR" 824 "Undheim Systems" 826 "Lewmar" 838 "TeamSurv" 844 "Fell Marine" 847 "Oceanvolt" 862 "Prospec" 868 "Data Panel" 890 "L3 Technologies" 894 "Rhodan Marine Systems" 896 "Nexfour Solutions" 905 "ASA Electronics" 909 "Marines Co (South Korea)" 911 "Nautic-on" 917 "Sentinel" 929 "JL Marine Systems" 930 "Ecotronix" 944 "Zontisa Marine" 951 "EXOR International" 962 "Timbolier Industries" 963 "TJC Micro" 968 "Cox Powertrain" 969 "Blue Seas" 981 "Kobelt Manufacturing" 992 "Blue Ocean IOT" 997 "Xenta Systems" 999 "Signal K" 1004 "Ultraflex" 1008 "Lintest SmartBoat" 1011 "Soundmax" 1020 "Team Italia Marine (Onyx Marine Automation s.r.l)" 1021 "Entratech" 1022 "ITC" 1029 "The Marine Guardian" 1047 "Sonic" 1051 "ProNav" 1053 "Vetus Maxwell INC." 1056 "Lithium Pros" 1059 "Boatrax" 1062 "Marol Co ltd" 1065 "CALYPSO Instruments" 1066 "Spot Zero Water" 1069 "Lithionics Battery" 1070 "Quick-teck Electronics" 1075 "Uniden America" 1083 "Nauticoncept" 1084 "Shadow-Caster LED lighting" 1085 "Wet Sounds" 1088 "E-T-A Circuit Breakers" 1092 "Scheiber" 1100 "Smart Yachts International Limited" 1109 "Dockmate" 1114 "Bobs Machine" 1118 "L3Harris ASV" 1119 "Balmar" 1120 "Elettromedia" 1127 "Electromaax" 1140 "Across Oceans Systems" 1145 "Kiwi Yachting" 1150 "BSB Artificial Intelligence" 1151 "Orca Technologies" 1154 "TBS Electronics" 1158 "Technoton Electroics" 1160 "MG Energy Systems" 1169 "Sea Machine Robotics" 1171 "Vista Manufacturing" 1183 "Zipwake" 1186 "Sailmon" 1192 "Airmoniq Pro Kft" 1194 "Sierra Marine" 1200 "Xinuo Information Technology (Xiamen)" 1218 "Septentrio" 1233 "NKE Marine Electronics" 1238 "SuperTrack Aps" 1239 "Honda Electronics" 1245 "Raritan Engineering" 1249 "Integrated Power Solutions AG" 1260 "Interactive Technologies" 1283 "LTG-Tech" 1299 "Energy Solutions (UK)" 1300 "WATT Fuel Cell" 1302 "Pro Mainer" 1305 "Dragonfly Energy" 1306 "Koden Electronics" 1311 "Humphree" 1316 "Hinkley Yachts" 1317 "Global Marine Management GmbH (GMM)" 1320 "Triskel Marine" 1330 "Warwick Control Technologies" 1331 "Dolphin Charger" 1337 "Barnacle Systems" 1348 "Radian IoT" 1353 "Ocean LED Marine" 1359 "BluNav" 1361 "OVA (Nantong Saiyang Electronics Co., Ltd)" 1368 "RAD Propulsion" 1369 "Electric Yacht" 1372 "Elco Motor Yachts" 1384 "Tecnoseal Foundry S.r.l" 1385 "Pro Charging Systems" 1389 "EVEX" 1398 "Gobius Sensor Technology" 1403 "Arco Marine" 1408 "Lenco Marine" 1413 "Naocontrol" 1417 "Revatek" 1438 "Aeolionics" 1439 "PredictWind" 1440 "Egis Mobile Electric" 1445 "Starboard Yacht Group" 1446 "Roswell Marine" 1451 "ePropulsion (Guangdong ePropulsion Technology Ltd.)" 1452 "Micro-Air" 1453 "Vital Battery" 1458 "Ride Controller" 1460 "Tocaro Blue" 1461 "Vanquish Yachts" 1471 "FT Technologies" 1478 "Alps Alpine" 1481 "E-Force Marine" 1482 "CMC Marine" 1483 "Nanjing Sandemarine Information Technology" 1850 "Teleflex Marine (SeaStar Solutions)" 1851 "Raymarine" 1852 "Navionics" 1853 "Japan Radio" 1854 "Northstar Technologies" 1855 "Furuno" 1856 "Trimble" 1857 "Simrad" 1858 "Litton" 1859 "Kvasar" 1860 "MMP" 1861 "Vector Cantech" 1862 "Yamaha Marine" 1863 "Faria Instruments" ;
VAL_ 2566865152 Industry_Code 0 "Global" 1 "Highway" 2 "Agriculture" 3 "Construction" 4 "Marine Industry" 5 "Industrial" ;
VAL_ 2566865408 Manufacturer_Code 69 "ARKS Enterprises" 78 "FW Murphy/Enovation Controls" 80 "Twin Disc" 85 "Kohler Power Systems" 88 "Hemisphere GPS" 135 "Airmar" 137 "Maretron" 140 "Lowrance" 144 "Mercury Marine" 147 "Nautibus Electronic" 148 "Blue Water Data" 154 "Westerbeke" 157 "ISSPRO" 161 "Offshore Systems (UK)" 163 "Evinrude/BRP" 165 "CPAC Systems" 168 "Xantrex Technology" 169 "Marlin Technologies" 172 "Yanmar Marine" 174 "Volvo Penta" 176 "Carling Technologies Inc. (Moritz Aerospace)" 185 "Beede Instruments" 192 "Floscan Instrument" 193 "Nobeltec" 198 "Mystic Valley Communications" 199 "Actia" 201 "Disenos Y Technologia" 211 "Digital Switching Systems" 215 "Xintex/Atena" 224 "EMMI NETWORK" 228 "ZF" 229 "Garmin" 233 "Yacht Monitoring Solutions" 235 "Sailormade Marine Telemetry/Tetra Technology" 243 "Eride" 257 "Honda Motor" 272 "Groco" 273 "Actisense" 274 "Amphenol LTW Technology" 275 "Navico" 283 "Hamilton Jet" 285 "Sea Recovery" 286 "Coelmo SRL Italy" 295 "BEP Marine" 304 "Empir Bus" 305 "NovAtel" 306 "Sleipner Motor" 307 "MBW Technologies" 315 "ICOM" 328 "Qwerty" 329 "Dief" 341 "Boening Automationstechnologie" 345 "Korean Maritime University" 351 "Thrane and Thrane" 355 "Mastervolt" 356 "Fischer Panda Generators" 358 "Victron Energy" 370 "Rolls Royce Marine" 373 "Electronic Design" 374 "Northern Lights" 378 "Glendinning" 381 "B & G" 384 "Rose Point Navigation Systems" 385 "Johnson Outdoors Marine Electronics Inc Geonav" 394 "Capi 2" 396 "Beyond Measure" 400 "Livorsi Marine" 404 "ComNav" 409 "Chetco" 419 "Fusion Electronics" 421 "Standard Horizon" 422 "True Heading" 426 "Egersund Marine Electronics" 427 "em-trak Marine Electronics" 431 "Tohatsu Co, JP" 437 "Digital Yacht" 438 "Comar Systems Limited" 440 "Cummins" 443 "VDO (aka Continental-Corporation)" 451 "Parker Hannifin aka Village Marine Tech" 459 "Alltek Marine Electronics" 460 "SAN GIORGIO S.E.I.N" 466 "Veethree Electronics & Marine" 470 "SI-TEX Marine Electronics" 471 "Sea Cross Marine" 475 "GME aka Standard Communications" 476 "Humminbird Marine Electronics" 478 "Ocean Sat" 481 "Chetco Digital Instruments" 493 "Watcheye" 499 "Lcj Capteurs" 502 "Attwood Marine" 503 "Naviop S.R.L." 504 "Vesper Marine" 510 "Marinesoft" 513 "Simarine" 517 "NoLand Engineering" 518 "Transas USA" 529 "National Instruments Korea" 530 "National Marine Electronics Association" 532 "Onwa Marine" 540 "Webasto" 571 "Marinecraft (South Korea)" 573 "McMurdo Group aka Orolia" 578 "Advansea" 579 "KVH" 580 "San Jose Technology" 583 "Yacht Control" 586 "Suzuki Motor" 591 "US Coast Guard" 595 "Ship Module aka Customware" 600 "Aquatic AV" 605 "Aventics" 606 "Intellian" 612 "SamwonIT" 614 "Arlt Tecnologies" 637 "Bavaria Yachts" 641 "Diverse Yacht Services" 644 "Wema U.S.A dba KUS" 658 "Shenzhen Jiuzhou Himunication" 688 "Rockford" 699 "Harman International" 704 "JL Audio" 708 "Lars Thrane" 715 "Autonnic" 717 "Yacht Devices" 734 "REAP Systems" 735 "AEM Performance Electronics" 739 "LxNav" 741 "Littelfuse, Inc (formerly Carling Technologies)" 743 "DaeMyung" 744 "Woosung" 748 "ISOTTA IFRA srl" 773 "Clarion US" 776 "HMI Systems" 777 "Ocean Signal" 778 "Seakeeper" 781 "Poly Planar" 785 "Fischer Panda DE" 795 "Broyda Industries" 796 "Canadian Automotive" 797 "Tides Marine" 798 "Lumishore" 799 "Still Water Designs and Audio" 802 "BJ Technologies (Beneteau)" 803 "Gill Sensors" 811 "Blue Water Desalination" 815 "FLIR" 824 "Undheim Systems" 826 "Lewmar" 838 "TeamSurv" 844 "Fell Marine" 847 "Oceanvolt" 862 "Prospec" 868 "Data Panel" 890 "L3 Technologies" 894 "Rhodan Marine Systems" 896 "Nexfour Solutions" 905 "ASA Electronics" 909 "Marines Co (South Korea)" 911 "Nautic-on" 917 "Sentinel" 929 "JL Marine Systems" 930 "Ecotronix" 944 "Zontisa Marine" 951 "EXOR International" 962 "Timbolier Industries" 963 "TJC Micro" 968 "Cox Powertrain" 969 "Blue Seas" 981 "Kobelt Manufacturing" 992 "Blue Ocean IOT" 997 "Xenta Systems" 999 "Signal K" 1004 "Ultraflex" 1008 "Lintest SmartBoat" 1011 "Soundmax" 1020 "Team Italia Marine (Onyx Marine Automation s.r.l)" 1021 "Entratech" 1022 "ITC" 1029 "The Marine Guardian" 1047 "Sonic" 1051 "ProNav" 1053 "Vetus Maxwell INC." 1056 "Lithium Pros" 1059 "Boatrax" 1062 "Marol Co ltd" 1065 "CALYPSO Instruments" 1066 "Spot Zero Water" 1069 "Lithionics Battery" 1070 "Quick-teck Electronics" 1075 "Uniden America" 1083 "Nauticoncept" 1084 "Shadow-Caster LED lighting" 1085 "Wet Sounds" 1088 "E-T-A Circuit Breakers" 1092 "Scheiber" 1100 "Smart Yachts International Limited" 1109 "Dockmate" 1114 "Bobs Machine" 1118 "L3Harris ASV" 1119 "Balmar" 1120 "Elettromedia" 1127 "Electromaax" 1140 "Across Oceans Systems" 1145 "Kiwi Yachting" 1150 "BSB Artificial Intelligence" 1151 "Orca Technologies" 1154 "TBS Electronics" 1158 "Technoton Electroics" 1160 "MG Energy Systems" 1169 "Sea Machine Robotics" 1171 "Vista Manufacturing" 1183 "Zipwake" 1186 "Sailmon" 1192 "Airmoniq Pro Kft" 1194 "Sierra Marine" 1200 "Xinuo Information Technology (Xiamen)" 1218 "Septentrio" 1233 "NKE Marine Electronics" 1238 "SuperTrack Aps" 1239 "Honda Electronics" 1245 "Raritan Engineering" 1249 "Integrated Power Solutions AG" 1260 "Interactive Technologies" 1283 "LTG-Tech" 1299 "Energy Solutions (UK)" 1300 "WATT Fuel Cell" 1302 "Pro Mainer" 1305 "Dragonfly Energy" 1306 "Koden Electronics" 1311 "Humphree" 1316 "Hinkley Yachts" 1317 "Global Marine Management GmbH (GMM)" 1320 "Triskel Marine" 1330 "Warwick Control Technologies" 1331 "Dolphin Charger" 1337 "Barnacle Systems" 1348 "Radian IoT" 1353 "Ocean LED Marine" 1359 "BluNav" 1361 "OVA (Nantong Saiyang Electronics Co., Ltd)" 1368 "RAD Propulsion" 1369 "Electric Yacht" 1372 "Elco Motor Yachts" 1384 "Tecnoseal Foundry S.r.l" 1385 "Pro Charging Systems" 1389 "EVEX" 1398 "Gobius Sensor Technology" 1403 "Arco Marine" 1408 "Lenco Marine" 1413 "Naocontrol" 1417 "Revatek" 1438 "Aeolionics" 1439 "PredictWind" 1440 "Egis Mobile Electric" 1445 "Starboard Yacht Group" 1446 "Roswell Marine" 1451 "ePropulsion (Guangdong ePropulsion Technology Ltd.)" 1452 "Micro-Air" 1453 "Vital Battery" 1458 "Ride Controller" 1460 "Tocaro Blue" 1461 "Vanquish Yachts" 1471 "FT Technologies" 1478 "Alps Alpine" 1481 "E-Force Marine" 1482 "CMC Marine" 1483 "Nanjing Sandemarine Information Technology" 1850 "Teleflex Marine (SeaStar Solutions)" 1851 "Raymarine" 1852 "Navionics" 1853 "Japan Radio" 1854 "Northstar Technologies" 1855 "Furuno" 1856 "Trimble" 1857 "Simrad" 1858 "Litton" 1859 "Kvasar" 1860 "MMP" 1861 "Vector Cantech" 1862 "Yamaha Marine" 1863 "Faria Instruments" ;
VAL_ 2566865408 Industry_Code 0 "Global" 1 "Highway" 2 "Agriculture" 3 "Construction" 4 "Marine Industry" 5 "Industrial" ;
VAL_ 2566865920 Manufacturer_Code 69 "ARKS Enterprises" 78 "FW Murphy/Enovation Controls" 80 "Twin Disc" 85 "Kohler Power Systems" 88 "Hemisphere GPS" 135 "Airmar" 137 "Maretron" 140 "Lowrance" 144 "Mercury Marine" 147 "Nautibus Electronic" 148 "Blue Water Data" 154 "Westerbeke" 157 "ISSPRO" 161 "Offshore Systems (UK)" 163 "Evinrude/BRP" 165 "CPAC Systems" 168 "Xantrex Technology" 169 "Marlin Technologies" 172 "Yanmar Marine" 174 "Volvo Penta" 176 "Carling Technologies Inc. (Moritz Aerospace)" 185 "Beede Instruments" 192 "Floscan Instrument" 193 "Nobeltec" 198 "Mystic Valley Communications" 199 "Actia" 201 "Disenos Y Technologia" 211 "Digital Switching Systems" 215 "Xintex/Atena" 224 "EMMI NETWORK" 228 "ZF" 229 "Garmin" 233 "Yacht Monitoring Solutions" 235 "Sailormade Marine Telemetry/Tetra Technology" 243 "Eride" 257 "Honda Motor" 272 "Groco" 273 "Actisense" 274 "Amphenol LTW Technology" 275 "Navico" 283 "Hamilton Jet" 285 "Sea Recovery" 286 "Coelmo SRL Italy" 295 "BEP Marine" 304 "Empir Bus" 305 "NovAtel" 306 "Sleipner Motor" 307 "MBW Technologies" 315 "ICOM" 328 "Qwerty" 329 "Dief" 341 "Boening Automationstechnologie" 345 "Korean Maritime University" 351 "Thrane and Thrane" 355 "Mastervolt" 356 "Fischer Panda Generators" 358 "Victron Energy" 370 "Rolls Royce Marine" 373 "Electronic Design" 374 "Northern Lights" 378 "Glendinning" 381 "B & G" 384 "Rose Point Navigation Systems" 385 "Johnson Outdoors Marine Electronics Inc Geonav" 394 "Capi 2" 396 "Beyond Measure" 400 "Livorsi Marine" 404 "ComNav" 409 "Chetco" 419 "Fusion Electronics" 421 "Standard Horizon" 422 "True Heading" 426 "Egersund Marine Electronics" 427 "em-trak Marine Electronics" 431 "Tohatsu Co, JP" 437 "Digital Yacht" 438 "Comar Systems Limited" 440 "Cummins" 443 "VDO (aka Continental-Corporation)" 451 "Parker Hannifin aka Village Marine Tech" 459 "Alltek Marine Electronics" 460 "SAN GIORGIO S.E.I.N" 466 "Veethree Electronics & Marine" 470 "SI-TEX Marine Electronics" 471 "Sea Cross Marine" 475 "GME aka Standard Communications" 476 "Humminbird Marine Electronics" 478 "Ocean Sat" 481 "Chetco Digital Instruments" 493 "Watcheye" 499 "Lcj Capteurs" 502 "Attwood Marine" 503 "Naviop S.R.L." 504 "Vesper Marine" 510 "Marinesoft" 513 "Simarine" 517 "NoLand Engineering" 518 "Transas USA" 529 "National Instruments Korea" 530 "National Marine Electronics Association" 532 "Onwa Marine" 540 "Webasto" 571 "Marinecraft (South Korea)" 573 "McMurdo Group aka Orolia" 578 "Advansea" 579 "KVH" 580 "San Jose Technology" 583 "Yacht Control" 586 "Suzuki Motor" 591 "US Coast Guard" 595 "Ship Module aka Customware" 600 "Aquatic AV" 605 "Aventics" 606 "Intellian" 612 "SamwonIT" 614 "Arlt Tecnologies" 637 "Bavaria Yachts" 641 "Diverse Yacht Services" 644 "Wema U.S.A dba KUS" 658 "Shenzhen Jiuzhou Himunication" 688 "Rockford" 699 "Harman International" 704 "JL Audio" 708 "Lars Thrane" 715 "Autonnic" 717 "Yacht Devices" 734 "REAP Systems" 735 "AEM Performance Electronics" 739 "LxNav" 741 "Littelfuse, Inc (formerly Carling Technologies)" 743 "DaeMyung" 744 "Woosung" 748 "ISOTTA IFRA srl" 773 "Clarion US" 776 "HMI Systems" 777 "Ocean Signal" 778 "Seakeeper" 781 "Poly Planar" 785 "Fischer Panda DE" 795 "Broyda Industries" 796 "Canadian Automotive" 797 "Tides Marine" 798 "Lumishore" 799 "Still Water Designs and Audio" 802 "BJ Technologies (Beneteau)" 803 "Gill Sensors" 811 "Blue Water Desalination" 815 "FLIR" 824 "Undheim Systems" 826 "Lewmar" 838 "TeamSurv" 844 "Fell Marine" 847 "Oceanvolt" 862 "Prospec" 868 "Data Panel" 890 "L3 Technologies" 894 "Rhodan Marine Systems" 896 "Nexfour Solutions" 905 "ASA Electronics" 909 "Marines Co (South Korea)" 911 "Nautic-on" 917 "Sentinel" 929 "JL Marine Systems" 930 "Ecotronix" 944 "Zontisa Marine" 951 "EXOR International" 962 "Timbolier Industries" 963 "TJC Micro" 968 "Cox Powertrain" 969 "Blue Seas" 981 "Kobelt Manufacturing" 992 "Blue Ocean IOT" 997 "Xenta Systems" 999 "Signal K" 1004 "Ultraflex" 1008 "Lintest SmartBoat" 1011 "Soundmax" 1020 "Team Italia Marine (Onyx Marine Automation s.r.l)" 1021 "Entratech" 1022 "ITC" 1029 "The Marine Guardian" 1047 "Sonic" 1051 "ProNav" 1053 "Vetus Maxwell INC." 1056 "Lithium Pros" 1059 "Boatrax" 1062 "Marol Co ltd" 1065 "CALYPSO Instruments" 1066 "Spot Zero Water" 1069 "Lithionics Battery" 1070 "Quick-teck Electronics" 1075 "Uniden America" 1083 "Nauticoncept" 1084 "Shadow-Caster LED lighting" 1085 "Wet Sounds" 1088 "E-T-A Circuit Breakers" 1092 "Scheiber" 1100 "Smart Yachts International Limited" 1109 "Dockmate" 1114 "Bobs Machine" 1118 "L3Harris ASV" 1119 "Balmar" 1120 "Elettromedia" 1127 "Electromaax" 1140 "Across Oceans Systems" 1145 "Kiwi Yachting" 1150 "BSB Artificial Intelligence" 1151 "Orca Technologies" 1154 "TBS Electronics" 1158 "Technoton Electroics" 1160 "MG Energy Systems" 1169 "Sea Machine Robotics" 1171 "Vista Manufacturing" 1183 "Zipwake" 1186 "Sailmon" 1192 "Airmoniq Pro Kft" 1194 "Sierra Marine" 1200 "Xinuo Information Technology (Xiamen)" 1218 "Septentrio" 1233 "NKE Marine Electronics" 1238 "SuperTrack Aps" 1239 "Honda Electronics" 1245 "Raritan Engineering" 1249 "Integrated Power Solutions AG" 1260 "Interactive Technologies" 1283 "LTG-Tech" 1299 "Energy Solutions (UK)" 1300 "WATT Fuel Cell" 1302 "Pro Mainer" 1305 "Dragonfly Energy" 1306 "Koden Electronics" 1311 "Humphree" 1316 "Hinkley Yachts" 1317 "Global Marine Management GmbH (GMM)" 1320 "Triskel Marine" 1330 "Warwick Control Technologies" 1331 "Dolphin Charger" 1337 "Barnacle Systems" 1348 "Radian IoT" 1353 "Ocean LED Marine" 1359 "BluNav" 1361 "OVA (Nantong Saiyang Electronics Co., Ltd)" 1368 "RAD Propulsion" 1369 "Electric Yacht" 1372 "Elco Motor Yachts" 1384 "Tecnoseal Foundry S.r.l" 1385 "Pro Charging Systems" 1389 "EVEX" 1398 "Gobius Sensor Technology" 1403 "Arco Marine" 1408 "Lenco Marine" 1413 "Naocontrol" 1417 "Revatek" 1438 "Aeolionics" 1439 "PredictWind" 1440 "Egis Mobile Electric" 1445 "Starboard Yacht Group" 1446 "Roswell Marine" 1451 "ePropulsion (Guangdong ePropulsion Technology Ltd.)" 1452 "Micro-Air" 1453 "Vital Battery" 1458 "Ride Controller" 1460 "Tocaro Blue" 1461 "Vanquish Yachts" 1471 "FT Technologies" 1478 "Alps Alpine" 1481 "E-Force Marine" 1482 "CMC Marine" 1483 "Nanjing Sandemarine Information Technology" 1850 "Teleflex Marine (SeaStar Solutions)" 1851 "Raymarine" 1852 "Navionics" 1853 "Japan Radio" 1854 "Northstar Technologies" 1855 "Furuno" 1856 "Trimble" 1857 "Simrad" 1858 "Litton" 1859 "Kvasar" 1860 "MMP" 1861 "Vector Cantech" 1862 "Yamaha Marine" 1863 "Faria Instruments" ;
VAL_ 2566865920 Industry_Code 0 "Global" 1 "Highway" 2 "Agriculture" 3 "Construction" 4 "Marine Industry" 5 "Industrial" ;
VAL_ 2566866176 Manufacturer_Code 69 "ARKS Enterprises" 78 "FW Murphy/Enovation Controls" 80 "Twin Disc" 85 "Kohler Power Systems" 88 "Hemisphere GPS" 135 "Airmar" 137 "Maretron" 140 "Lowrance" 144 "Mercury Marine" 147 "Nautibus Electronic" 148 "Blue Water Data" 154 "Westerbeke" 157 "ISSPRO" 161 "Offshore Systems (UK)" 163 "Evinrude/BRP" 165 "CPAC Systems" 168 "Xantrex Technology" 169 "Marlin Technologies" 172 "Yanmar Marine" 174 "Volvo Penta" 176 "Carling Technologies Inc. (Moritz Aerospace)" 185 "Beede Instruments" 192 "Floscan Instrument" 193 "Nobeltec" 198 "Mystic Valley Communications" 199 "Actia" 201 "Disenos Y Technologia" 211 "Digital Switching Systems" 215 "Xintex/Atena" 224 "EMMI NETWORK" 228 "ZF" 229 "Garmin" 233 "Yacht Monitoring Solutions" 235 "Sailormade Marine Telemetry/Tetra Technology" 243 "Eride" 257 "Honda Motor" 272 "Groco" 273 "Actisense" 274 "Amphenol LTW Technology" 275 "Navico" 283 "Hamilton Jet" 285 "Sea Recovery" 286 "Coelmo SRL Italy" 295 "BEP Marine" 304 "Empir Bus" 305 "NovAtel" 306 "Sleipner Motor" 307 "MBW Technologies" 315 "ICOM" 328 "Qwerty" 329 "Dief" 341 "Boening Automationstechnologie" 345 "Korean Maritime University" 351 "Thrane and Thrane" 355 "Mastervolt" 356 "Fischer Panda Generators" 358 "Victron Energy" 370 "Rolls Royce Marine" 373 "Electronic Design" 374 "Northern Lights" 378 "Glendinning" 381 "B & G" 384 "Rose Point Navigation Systems" 385 "Johnson Outdoors Marine Electronics Inc Geonav" 394 "Capi 2" 396 "Beyond Measure" 400 "Livorsi Marine" 404 "ComNav" 409 "Chetco" 419 "Fusion Electronics" 421 "Standard Horizon" 422 "True Heading" 426 "Egersund Marine Electronics" 427 "em-trak Marine Electronics" 431 "Tohatsu Co, JP" 437 "Digital Yacht" 438 "Comar Systems Limited" 440 "Cummins" 443 "VDO (aka Continental-Corporation)" 451 "Parker Hannifin aka Village Marine Tech" 459 "Alltek Marine Electronics" 460 "SAN GIORGIO S.E.I.N" 466 "Veethree Electronics & Marine" 470 "SI-TEX Marine Electronics" 471 "Sea Cross Marine" 475 "GME aka Standard Communications" 476 "Humminbird Marine Electronics" 478 "Ocean Sat" 481 "Chetco Digital Instruments" 493 "Watcheye" 499 "Lcj Capteurs" 502 "Attwood Marine" 503 "Naviop S.R.L." 504 "Vesper Marine" 510 "Marinesoft" 513 "Simarine" 517 "NoLand Engineering" 518 "Transas USA" 529 "National Instruments Korea" 530 "National Marine Electronics Association" 532 "Onwa Marine" 540 "Webasto" 571 "Marinecraft (South Korea)" 573 "McMurdo Group aka Orolia" 578 "Advansea" 579 "KVH" 580 "San Jose Technology" 583 "Yacht Control" 586 "Suzuki Motor" 591 "US Coast Guard" 595 "Ship Module aka Customware" 600 "Aquatic AV" 605 "Aventics" 606 "Intellian" 612 "SamwonIT" 614 "Arlt Tecnologies" 637 "Bavaria Yachts" 641 "Diverse Yacht Services" 644 "Wema U.S.A dba KUS" 658 "Shenzhen Jiuzhou Himunication" 688 "Rockford" 699 "Harman International" 704 "JL Audio" 708 "Lars Thrane" 715 "Autonnic" 717 "Yacht Devices" 734 "REAP Systems" 735 "AEM Performance Electronics" 739 "LxNav" 741 "Littelfuse, Inc (formerly Carling Technologies)" 743 "DaeMyung" 744 "Woosung" 748 "ISOTTA IFRA srl" 773 "Clarion US" 776 "HMI Systems" 777 "Ocean Signal" 778 "Seakeeper" 781 "Poly Planar" 785 "Fischer Panda DE" 795 "Broyda Industries" 796 "Canadian Automotive" 797 "Tides Marine" 798 "Lumishore" 799 "Still Water Designs and Audio" 802 "BJ Technologies (Beneteau)" 803 "Gill Sensors" 811 "Blue Water Desalination" 815 "FLIR" 824 "Undheim Systems" 826 "Lewmar" 838 "TeamSurv" 844 "Fell Marine" 847 "Oceanvolt" 862 "Prospec" 868 "Data Panel" 890 "L3 Technologies" 894 "Rhodan Marine Systems" 896 "Nexfour Solutions" 905 "ASA Electronics" 909 "Marines Co (South Korea)" 911 "Nautic-on" 917 "Sentinel" 929 "JL Marine Systems" 930 "Ecotronix" 944 "Zontisa Marine" 951 "EXOR International" 962 "Timbolier Industries" 963 "TJC Micro" 968 "Cox Powertrain" 969 "Blue Seas" 981 "Kobelt Manufacturing" 992 "Blue Ocean IOT" 997 "Xenta Systems" 999 "Signal K" 1004 "Ultraflex" 1008 "Lintest SmartBoat" 1011 "Soundmax" 1020 "Team Italia Marine (Onyx Marine Automation s.r.l)" 1021 "Entratech" 1022 "ITC" 1029 "The Marine Guardian" 1047 "Sonic" 1051 "ProNav" 1053 "Vetus Maxwell INC." 1056 "Lithium Pros" 1059 "Boatrax" 1062 "Marol Co ltd" 1065 "CALYPSO Instruments" 1066 "Spot Zero Water" 1069 "Lithionics Battery" 1070 "Quick-teck Electronics" 1075 "Uniden America" 1083 "Nauticoncept" 1084 "Shadow-Caster LED lighting" 1085 "Wet Sounds" 1088 "E-T-A Circuit Breakers" 1092 "Scheiber" 1100 "Smart Yachts International Limited" 1109 "Dockmate" 1114 "Bobs Machine" 1118 "L3Harris ASV" 1119 "Balmar" 1120 "Elettromedia" 1127 "Electromaax" 1140 "Across Oceans Systems" 1145 "Kiwi Yachting" 1150 "BSB Artificial Intelligence" 1151 "Orca Technologies" 1154 "TBS Electronics" 1158 "Technoton Electroics" 1160 "MG Energy Systems" 1169 "Sea Machine Robotics" 1171 "Vista Manufacturing" 1183 "Zipwake" 1186 "Sailmon" 1192 "Airmoniq Pro Kft" 1194 "Sierra Marine" 1200 "Xinuo Information Technology (Xiamen)" 1218 "Septentrio" 1233 "NKE Marine Electronics" 1238 "SuperTrack Aps" 1239 "Honda Electronics" 1245 "Raritan Engineering" 1249 "Integrated Power Solutions AG" 1260 "Interactive Technologies" 1283 "LTG-Tech" 1299 "Energy Solutions (UK)" 1300 "WATT Fuel Cell" 1302 "Pro Mainer" 1305 "Dragonfly Energy" 1306 "Koden Electronics" 1311 "Humphree" 1316 "Hinkley Yachts" 1317 "Global Marine Management GmbH (GMM)" 1320 "Triskel Marine" 1330 "Warwick Control Technologies" 1331 "Dolphin Charger" 1337 "Barnacle Systems" 1348 "Radian IoT" 1353 "Ocean LED Marine" 1359 "BluNav" 1361 "OVA (Nantong Saiyang Electronics Co., Ltd)" 1368 "RAD Propulsion" 1369 "Electric Yacht" 1372 "Elco Motor Yachts" 1384 "Tecnoseal Foundry S.r.l" 1385 "Pro Charging Systems" 1389 "EVEX" 1398 "Gobius Sensor Technology" 1403 "Arco Marine" 1408 "Lenco Marine" 1413 "Naocontrol" 1417 "Revatek" 1438 "Aeolionics" 1439 "PredictWind" 1440 "Egis Mobile Electric" 1445 "Starboard Yacht Group" 1446 "Roswell Marine" 1451 "ePropulsion (Guangdong ePropulsion Technology Ltd.)" 1452 "Micro-Air" 1453 "Vital Battery" 1458 "Ride Controller" 1460 "Tocaro Blue" 1461 "Vanquish Yachts" 1471 "FT Technologies" 1478 "Alps Alpine" 1481 "E-Force Marine" 1482 "CMC Marine" 1483 "Nanjing Sandemarine Information Technology" 1850 "Teleflex Marine (SeaStar Solutions)" 1851 "Raymarine" 1852 "Navionics" 1853 "Japan Radio" 1854 "Northstar Technologies" 1855 "Furuno" 1856 "Trimble" 1857 "Simrad" 1858 "Litton" 1859 "Kvasar" 1860 "MMP" 1861 "Vector Cantech" 1862 "Yamaha Marine" 1863 "Faria Instruments" ;
VAL_ 2566866176 Industry_Code 0 "Global" 1 "Highway" 2 "Agriculture" 3 "Construction" 4 "Marine Industry" 5 "Industrial" ;
VAL_ 2633977600 Manufacturer_Code 69 "ARKS Enterprises" 78 "FW Murphy/Enovation Controls" 80 "Twin Disc" 85 "Kohler Power Systems" 88 "Hemisphere GPS" 135 "Airmar" 137 "Maretron" 140 "Lowrance" 144 "Mercury Marine" 147 "Nautibus Electronic" 148 "Blue Water Data" 154 "Westerbeke" 157 "ISSPRO" 161 "Offshore Systems (UK)" 163 "Evinrude/BRP" 165 "CPAC Systems" 168 "Xantrex Technology" 169 "Marlin Technologies" 172 "Yanmar Marine" 174 "Volvo Penta" 176 "Carling Technologies Inc. (Moritz Aerospace)" 185 "Beede Instruments" 192 "Floscan Instrument" 193 "Nobeltec" 198 "Mystic Valley Communications" 199 "Actia" 201 "Disenos Y Technologia" 211 "Digital Switching Systems" 215 "Xintex/Atena" 224 "EMMI NETWORK" 228 "ZF" 229 "Garmin" 233 "Yacht Monitoring Solutions" 235 "Sailormade Marine Telemetry/Tetra Technology" 243 "Eride" 257 "Honda Motor" 272 "Groco" 273 "Actisense" 274 "Amphenol LTW Technology" 275 "Navico" 283 "Hamilton Jet" 285 "Sea Recovery" 286 "Coelmo SRL Italy" 295 "BEP Marine" 304 "Empir Bus" 305 "NovAtel" 306 "Sleipner Motor" 307 "MBW Technologies" 315 "ICOM" 328 "Qwerty" 329 "Dief" 341 "Boening Automationstechnologie" 345 "Korean Maritime University" 351 "Thrane and Thrane" 355 "Mastervolt" 356 "Fischer Panda Generators" 358 "Victron Energy" 370 "Rolls Royce Marine" 373 "Electronic Design" 374 "Northern Lights" 378 "Glendinning" 381 "B & G" 384 "Rose Point Navigation Systems" 385 "Johnson Outdoors Marine Electronics Inc Geonav" 394 "Capi 2" 396 "Beyond Measure" 400 "Livorsi Marine" 404 "ComNav" 409 "Chetco" 419 "Fusion Electronics" 421 "Standard Horizon" 422 "True Heading" 426 "Egersund Marine Electronics" 427 "em-trak Marine Electronics" 431 "Tohatsu Co, JP" 437 "Digital Yacht" 438 "Comar Systems Limited" 440 "Cummins" 443 "VDO (aka Continental-Corporation)" 451 "Parker Hannifin aka Village Marine Tech" 459 "Alltek Marine Electronics" 460 "SAN GIORGIO S.E.I.N" 466 "Veethree Electronics & Marine" 470 "SI-TEX Marine Electronics" 471 "Sea Cross Marine" 475 "GME aka Standard Communications" 476 "Humminbird Marine Electronics" 478 "Ocean Sat" 481 "Chetco Digital Instruments" 493 "Watcheye" 499 "Lcj Capteurs" 502 "Attwood Marine" 503 "Naviop S.R.L." 504 "Vesper Marine" 510 "Marinesoft" 513 "Simarine" 517 "NoLand Engineering" 518 "Transas USA" 529 "National Instruments Korea" 530 "National Marine Electronics Association" 532 "Onwa Marine" 540 "Webasto" 571 "Marinecraft (South Korea)" 573 "McMurdo Group aka Orolia" 578 "Advansea" 579 "KVH" 580 "San Jose Technology" 583 "Yacht Control" 586 "Suzuki Motor" 591 "US Coast Guard" 595 "Ship Module aka Customware" 600 "Aquatic AV" 605 "Aventics" 606 "Intellian" 612 "SamwonIT" 614 "Arlt Tecnologies" 637 "Bavaria Yachts" 641 "Diverse Yacht Services" 644 "Wema U.S.A dba KUS" 658 "Shenzhen Jiuzhou Himunication" 688 "Rockford" 699 "Harman International" 704 "JL Audio" 708 "Lars Thrane" 715 "Autonnic" 717 "Yacht Devices" 734 "REAP Systems" 735 "AEM Performance Electronics" 739 "LxNav" 741 "Littelfuse, Inc (formerly Carling Technologies)" 743 "DaeMyung" 744 "Woosung" 748 "ISOTTA IFRA srl" 773 "Clarion US" 776 "HMI Systems" 777 "Ocean Signal" 778 "Seakeeper" 781 "Poly Planar" 785 "Fischer Panda DE" 795 "Broyda Industries" 796 "Canadian Automotive" 797 "Tides Marine" 798 "Lumishore" 799 "Still Water Designs and Audio" 802 "BJ Technologies (Beneteau)" 803 "Gill Sensors" 811 "Blue Water Desalination" 815 "FLIR" 824 "Undheim Systems" 826 "Lewmar" 838 "TeamSurv" 844 "Fell Marine" 847 "Oceanvolt" 862 "Prospec" 868 "Data Panel" 890 "L3 Technologies" 894 "Rhodan Marine Systems" 896 "Nexfour Solutions" 905 "ASA Electronics" 909 "Marines Co (South Korea)" 911 "Nautic-on" 917 "Sentinel" 929 "JL Marine Systems" 930 "Ecotronix" 944 "Zontisa Marine" 951 "EXOR International" 962 "Timbolier Industries" 963 "TJC Micro" 968 "Cox Powertrain" 969 "Blue Seas" 981 "Kobelt Manufacturing" 992 "Blue Ocean IOT" 997 "Xenta Systems" 999 "Signal K" 1004 "Ultraflex" 1008 "Lintest SmartBoat" 1011 "Soundmax" 1020 "Team Italia Marine (Onyx Marine Automation s.r.l)" 1021 "Entratech" 1022 "ITC" 1029 "The Marine Guardian" 1047 "Sonic" 1051 "ProNav" 1053 "Vetus Maxwell INC." 1056 "Lithium Pros" 1059 "Boatrax" 1062 "Marol Co ltd" 1065 "CALYPSO Instruments" 1066 "Spot Zero Water" 1069 "Lithionics Battery" 1070 "Quick-teck Electronics" 1075 "Uniden America" 1083 "Nauticoncept" 1084 "Shadow-Caster LED lighting" 1085 "Wet Sounds" 1088 "E-T-A Circuit Breakers" 1092 "Scheiber" 1100 "Smart Yachts International Limited" 1109 "Dockmate" 1114 "Bobs Machine" 1118 "L3Harris ASV" 1119 "Balmar" 1120 "Elettromedia" 1127 "Electromaax" 1140 "Across Oceans Systems" 1145 "Kiwi Yachting" 1150 "BSB Artificial Intelligence" 1151 "Orca Technologies" 1154 "TBS Electronics" 1158 "Technoton Electroics" 1160 "MG Energy Systems" 1169 "Sea Machine Robotics" 1171 "Vista Manufacturing" 1183 "Zipwake" 1186 "Sailmon" 1192 "Airmoniq Pro Kft" 1194 "Sierra Marine" 1200 "Xinuo Information Technology (Xiamen)" 1218 "Septentrio" 1233 "NKE Marine Electronics" 1238 "SuperTrack Aps" 1239 "Honda Electronics" 1245 "Raritan Engineering" 1249 "Integrated Power Solutions AG" 1260 "Interactive Technologies" 1283 "LTG-Tech" 1299 "Energy Solutions (UK)" 1300 "WATT Fuel Cell" 1302 "Pro Mainer" 1305 "Dragonfly Energy" 1306 "Koden Electronics" 1311 "Humphree" 1316 "Hinkley Yachts" 1317 "Global Marine Management GmbH (GMM)" 1320 "Triskel Marine" 1330 "Warwick Control Technologies" 1331 "Dolphin Charger" 1337 "Barnacle Systems" 1348 "Radian IoT" 1353 "Ocean LED Marine" 1359 "BluNav" 1361 "OVA (Nantong Saiyang Electronics Co., Ltd)" 1368 "RAD Propulsion" 1369 "Electric Yacht" 1372 "Elco Motor Yachts" 1384 "Tecnoseal Foundry S.r.l" 1385 "Pro Charging Systems" 1389 "EVEX" 1398 "Gobius Sensor Technology" 1403 "Arco Marine" 1408 "Lenco Marine" 1413 "Naocontrol" 1417 "Revatek" 1438 "Aeolionics" 1439 "PredictWind" 1440 "Egis Mobile Electric" 1445 "Starboard Yacht Group" 1446 "Roswell Marine" 1451 "ePropulsion (Guangdong ePropulsion Technology Ltd.)" 1452 "Micro-Air" 1453 "Vital Battery" 1458 "Ride Controller" 1460 "Tocaro Blue" 1461 "Vanquish Yachts" 1471 "FT Technologies" 1478 "Alps Alpine" 1481 "E-Force Marine" 1482 "CMC Marine" 1483 "Nanjing Sandemarine Information Technology" 1850 "Teleflex Marine (SeaStar Solutions)" 1851 "Raymarine" 1852 "Navionics" 1853 "Japan Radio" 1854 "Northstar Technologies" 1855 "Furuno" 1856 "Trimble" 1857 "Simrad" 1858 "Litton" 1859 "Kvasar" 1860 "MMP" 1861 "Vector Cantech" 1862 "Yamaha Marine" 1863 "Faria Instruments" ;
VAL_ 2633977600 Industry_Code 0 "Global" 1 "Highway" 2 "Agriculture" 3 "Construction" 4 "Marine Industry" 5 "Industrial" ;

BA_DEF_ BO_ "GenMsgCycleTime" INT 0 60000;
BA_DEF_ BO_ "ProtocolType" STRING;

BA_DEF_ BO_ "J1939PGN" INT 0 262143;
BA_ "J1939PGN" BO_ 2566855168 65306;
BA_ "J1939PGN" BO_ 2566855680 65308;
BA_ "J1939PGN" BO_ 2633964800 65309;
BA_ "J1939PGN" BO_ 2566856192 65310;
BA_ "J1939PGN" BO_ 2566856448 65311;
BA_ "J1939PGN" BO_ 2633965568 65312;
BA_ "J1939PGN" BO_ 2566856960 65313;
BA_ "J1939PGN" BO_ 2566857216 65314;
BA_ "J1939PGN" BO_ 2566857216 65314;
BA_ "J1939PGN" BO_ 2566857472 65315;
BA_ "J1939PGN" BO_ 2566857728 65316;
BA_ "J1939PGN" BO_ 2566857984 65317;
BA_ "J1939PGN" BO_ 2365532928 65323;
BA_ "GenMsgCycleTime" BO_ 2365532928 1000;
BA_ "J1939PGN" BO_ 2365533184 65324;
BA_ "GenMsgCycleTime" BO_ 2365533184 1000;
BA_ "J1939PGN" BO_ 2566860032 65325;
BA_ "J1939PGN" BO_ 2566861056 65329;
BA_ "J1939PGN" BO_ 2566861312 65330;
BA_ "J1939PGN" BO_ 2566861824 65332;
BA_ "J1939PGN" BO_ 2365537280 65340;
BA_ "GenMsgCycleTime" BO_ 2365537280 1000;
BA_ "J1939PGN" BO_ 2566864128 65341;
BA_ "J1939PGN" BO_ 2566864896 65344;
BA_ "J1939PGN" BO_ 2566865152 65345;
BA_ "J1939PGN" BO_ 2566865408 65346;
BA_ "J1939PGN" BO_ 2566865920 65348;
BA_ "J1939PGN" BO_ 2566866176 65349;
BA_ "J1939PGN" BO_ 2566866432 65350;
BA_ "J1939PGN" BO_ 2633977600 65359;
